VERSION ""

NS_ :

BS_:

BU_: TPMS EBS

BO_ 3221225472 VECTOR__INDEPENDENT_SIG_MSG: 0 Vector__XXX
 SG_ RqedPercentFanSpeed : 0|8@1+ (0.4,0) [0|100] "%" Vector__XXX
 SG_ IlluminationBrightnessPercent : 0|8@1+ (0.4,0) [0|100] "%" Vector__XXX
 SG_ CbA_CRfrgrntCmprssorOutletPress : 0|8@1+ (16,0) [0|4000] "kPa" Vector__XXX
 SG_ RelativeLevelRearAxleRight : 0|16@1+ (0.1,-2800) [-2800|3225.5] "mm" Vector__XXX
 SG_ RelativeLevelRearAxleLeft : 0|16@1+ (0.1,-2800) [-2800|3225.5] "mm" Vector__XXX
 SG_ RelativeLevelFrontAxleRight : 0|16@1+ (0.1,-2800) [-2800|3225.5] "mm" Vector__XXX
 SG_ RelativeLevelFrontAxleLeft : 0|16@1+ (0.1,-2800) [-2800|3225.5] "mm" Vector__XXX
 SG_ SspensionCtrlRefusalInformation : 0|4@1+ (1,0) [0|15] "" Vector__XXX
 SG_ SuspensionRemoteCtrl2 : 0|2@1+ (1,0) [0|3] "" Vector__XXX
 SG_ SuspensionRemoteCtrl1 : 0|2@1+ (1,0) [0|3] "" Vector__XXX
 SG_ RearAxleInBumperRange : 0|2@1+ (1,0) [0|3] "" Vector__XXX
 SG_ FrontAxleInBumperRange : 0|2@1+ (1,0) [0|3] "" Vector__XXX
 SG_ DoorRelease : 0|2@1+ (1,0) [0|3] "" Vector__XXX
 SG_ VehicleMotionInhibit : 0|2@1+ (1,0) [0|3] "" Vector__XXX
 SG_ SecurityDevice : 0|2@1+ (1,0) [0|3] "" Vector__XXX
 SG_ LevelCtrlMode : 0|4@1+ (1,0) [0|15] "" Vector__XXX
 SG_ KneelingInformation : 0|4@1+ (1,0) [0|15] "" Vector__XXX
 SG_ LiftingCtrlModeRearAxle : 0|2@1+ (1,0) [0|3] "" Vector__XXX
 SG_ LiftingCtrlModeFrontAxle : 0|2@1+ (1,0) [0|3] "" Vector__XXX
 SG_ LoweringCtrlModeRearAxle : 0|2@1+ (1,0) [0|3] "" Vector__XXX
 SG_ LoweringCtrlModeFrontAxle : 0|2@1+ (1,0) [0|3] "" Vector__XXX
 SG_ AboveNominalLevelRearAxle : 0|2@1+ (1,0) [0|3] "" Vector__XXX
 SG_ AboveNominalLevelFrontAxle : 0|2@1+ (1,0) [0|3] "" Vector__XXX
 SG_ BelowNominalLevelRearAxle : 0|2@1+ (1,0) [0|3] "" Vector__XXX
 SG_ BelowNominalLevelFrontAxle : 0|2@1+ (1,0) [0|3] "" Vector__XXX
 SG_ NominalLevelRearAxle : 0|4@1+ (1,0) [0|15] "" Vector__XXX
 SG_ NominalLevelFrontAxle : 0|4@1+ (1,0) [0|15] "" Vector__XXX
 SG_ LiftAxle2Pos : 0|2@1+ (1,0) [0|3] "" Vector__XXX
 SG_ LiftAxle1Pos : 0|2@1+ (1,0) [0|3] "" Vector__XXX
 SG_ UseTransferMode : 0|2@1+ (1,0) [0|3] "" Vector__XXX
 SG_ ParameterGroupNumber : 0|24@1+ (1,0) [0|16777215] "" Vector__XXX
 SG_ RoadSurfaceTemp : 0|16@1+ (0.03125,-273) [-273|1735] "deg" Vector__XXX
 SG_ EngAirInletTemp : 0|8@1+ (1,-40) [-40|210] "deg" Vector__XXX
 SG_ AmbientAirTemp : 0|16@1+ (0.03125,-273) [-273|1735] "deg" Vector__XXX
 SG_ CabInteriorTemp : 0|16@1+ (0.03125,-273) [-273|1735] "deg" Vector__XXX
 SG_ BarometricPress : 0|8@1+ (0.5,0) [0|125] "kPa" Vector__XXX
 SG_ TransOilLevelMeasurementStatus : 0|4@1+ (1,0) [0|15] "" Vector__XXX
 SG_ TransOilLevelCountdownTimer : 0|4@1+ (1,0) [0|15] "" Vector__XXX
 SG_ TransOilLevelHigh_Low : 0|8@1+ (0.5,-62.5) [-62.5|62.5] "L" Vector__XXX
 SG_ TransOilTemp : 0|16@1+ (0.03125,-273) [-273|1735] "deg" Vector__XXX
 SG_ TransOilPress : 0|8@1+ (16,0) [0|4000] "kPa" Vector__XXX
 SG_ TransFilterDiffPress : 0|8@1+ (2,0) [0|500] "kPa" Vector__XXX
 SG_ TransOilLevel : 0|8@1+ (0.4,0) [0|100] "%" Vector__XXX
 SG_ ClutchPress : 0|8@1+ (16,0) [0|4000] "kPa" Vector__XXX
 SG_ BatteryPotentialSwitched : 0|16@1+ (0.05,0) [0|3212.75] "V" Vector__XXX
 SG_ ElectricalPotential : 0|16@1+ (0.05,0) [0|3212.75] "V" Vector__XXX
 SG_ ChargingSystemPotential : 0|16@1+ (0.05,0) [0|3212.75] "V" Vector__XXX
 SG_ AltCurrent : 0|8@1+ (1,0) [0|250] "A" Vector__XXX
 SG_ NetBatteryCurrent : 0|8@1+ (1,-125) [-125|125] "A" Vector__XXX
 SG_ TotalNumberOfPacketsEoMA : 0|8@1+ (1,0) [0|255] "" Vector__XXX
 SG_ TotalMessageSizeEoMA : 0|16@1+ (1,0) [0|64255] "counts" Vector__XXX
 SG_ TotalMessageSizeBAM : 0|16@1+ (1,0) [0|64255] "counts" Vector__XXX
 SG_ TotalNumberOfPacketsBAM : 0|8@1+ (1,0) [0|255] "" Vector__XXX
 SG_ ConnectionAbortReason : 0|8@1+ (1,0) [0|255] "" Vector__XXX
 SG_ NextPacketNumberToBeSent : 0|8@1+ (1,0) [0|255] "" Vector__XXX
 SG_ NumberOfPacketsThatCanBeSent : 0|8@1+ (1,0) [0|255] "" Vector__XXX
 SG_ PGNumber : 0|24@1+ (1,0) [0|16777200] "" Vector__XXX
 SG_ MaximumNumberOfPackets : 0|8@1+ (1,0) [0|255] "" Vector__XXX
 SG_ TotalNumberOfPackets : 0|8@1+ (1,0) [0|255] "" Vector__XXX
 SG_ TotalMessageSize : 0|16@1+ (1,0) [0|64255] "counts" Vector__XXX
 SG_ ControlByte : 0|8@1+ (1,0) [0|255] "" Vector__XXX
 SG_ SequenceNumber : 0|8@1+ (1,0) [0|252] "" Vector__XXX
 SG_ DTC5 : 0|32@1+ (1,0) [0|4294967295] "" Vector__XXX
 SG_ DTC4 : 0|32@1+ (1,0) [0|4294967295] "" Vector__XXX
 SG_ DTC3 : 0|32@1+ (1,0) [0|4294967295] "" Vector__XXX
 SG_ DTC2 : 0|32@1+ (1,0) [0|4294967295] "" Vector__XXX
 SG_ DTC1 : 0|32@1+ (1,0) [0|4294967295] "" Vector__XXX
 SG_ DTC5 : 0|32@1+ (1,0) [0|4294967295] "" Vector__XXX
 SG_ DTC4 : 0|32@1+ (1,0) [0|4294967295] "" Vector__XXX
 SG_ DTC3 : 0|32@1+ (1,0) [0|4294967295] "" Vector__XXX
 SG_ DTC2 : 0|32@1+ (1,0) [0|4294967295] "" Vector__XXX
 SG_ CalibrationID4 : 0|32@1+ (1,0) [0|4294967295] "" Vector__XXX
 SG_ CalibrationID3 : 0|32@1+ (1,0) [0|4294967295] "" Vector__XXX
 SG_ CalibrationID2 : 0|32@1+ (1,0) [0|4294967295] "" Vector__XXX
 SG_ CalibrationID1 : 0|32@1+ (1,0) [0|4294967295] "" Vector__XXX
 SG_ CalibrationVerificationNumber : 0|32@1+ (1,0) [0|4294967295] "" Vector__XXX
 SG_ DTC5 : 0|32@1+ (1,0) [0|4294967295] "" Vector__XXX
 SG_ DTC4 : 0|32@1+ (1,0) [0|4294967295] "" Vector__XXX
 SG_ DTC3 : 0|32@1+ (1,0) [0|4294967295] "" Vector__XXX
 SG_ DTC2 : 0|32@1+ (1,0) [0|4294967295] "" Vector__XXX
 SG_ DTC1 : 0|32@1+ (1,0) [0|4294967295] "" Vector__XXX
 SG_ SPNSupported1High : 0|3@1+ (1,0) [0|7] "" Vector__XXX
 SG_ SPNSupportTypeSTR3 : 0|1@1+ (1,0) [0|1] "" Vector__XXX
 SG_ SPNSupportTypeSTR2 : 0|1@1+ (1,0) [0|1] "" Vector__XXX
 SG_ SPNSupportTypeEFF3 : 0|1@1+ (1,0) [0|1] "" Vector__XXX
 SG_ SPNSupportTypeEFF2 : 0|1@1+ (1,0) [0|1] "" Vector__XXX
 SG_ SPNSupportTypeDS3 : 0|1@1+ (1,0) [0|1] "" Vector__XXX
 SG_ SPNSupportTypeDS2 : 0|1@1+ (1,0) [0|1] "" Vector__XXX
 SG_ SPNSupported3High : 0|3@1+ (1,0) [0|7] "" Vector__XXX
 SG_ SPNSupported2High : 0|3@1+ (1,0) [0|7] "" Vector__XXX
 SG_ SPNSupported3 : 0|16@1+ (1,0) [0|65535] "" Vector__XXX
 SG_ SPNSupported2 : 0|16@1+ (1,0) [0|65535] "" Vector__XXX
 SG_ SPNDataLength3 : 0|8@1+ (1,0) [0|240] "" Vector__XXX
 SG_ SPNSupportTypeSTR1 : 0|1@1+ (1,0) [0|1] "" Vector__XXX
 SG_ SPNSupportTypeDS1 : 0|1@1+ (1,0) [0|1] "" Vector__XXX
 SG_ SPNSupportTypeEFF1 : 0|1@1+ (1,0) [0|1] "" Vector__XXX
 SG_ SPNDataLength2 : 0|8@1+ (1,0) [0|240] "" Vector__XXX
 SG_ SPNDataLength1 : 0|8@1+ (1,0) [0|240] "" Vector__XXX
 SG_ SPNSupported1 : 0|16@1+ (1,0) [0|65535] "" Vector__XXX
 SG_ DTC1 : 0|32@1+ (1,0) [0|4294967295] "" Vector__XXX
 SG_ ExpandedFreezeFrameLength : 0|8@1+ (1,0) [0|255] "Byte" Vector__XXX
 SG_ DTC1 : 0|32@1+ (1,0) [0|4294967295] "" Vector__XXX
 SG_ FreezeFrameLength : 0|8@1+ (1,0) [0|255] "Byte" Vector__XXX
 SG_ EngineCoolantTemperature : 0|8@1+ (1,-40) [-40|210] "°C" Vector__XXX
 SG_ MisfireMonitoringSupport : 0|1@1+ (1,0) [0|0] "" Vector__XXX
 SG_ OBDCompliance : 0|8@1+ (1,0) [0|240] "" Vector__XXX
 SG_ PreviouslyActiveTroubleCodes : 0|8@1+ (1,0) [0|240] "" Vector__XXX
 SG_ ActiveTroubleCodes : 0|8@1+ (1,0) [0|240] "" Vector__XXX
 SG_ SecondAirSystemMonStatus : 0|1@1+ (1,0) [0|1] "" Vector__XXX
 SG_ EvaporativeSystemMonStatus : 0|1@1+ (1,0) [0|1] "" Vector__XXX
 SG_ ACSystemRefrigerantMonStatus : 0|1@1+ (1,0) [0|1] "" Vector__XXX
 SG_ OxygenSensorHeaterMonStatus : 0|1@1+ (1,0) [0|1] "" Vector__XXX
 SG_ OxygenSensorMonStatus : 0|1@1+ (1,0) [0|1] "" Vector__XXX
 SG_ EGRSystemMonitoringStatus : 0|1@1+ (1,0) [0|1] "" Vector__XXX
 SG_ CatalystMonStatus : 0|1@1+ (1,0) [0|1] "" Vector__XXX
 SG_ ColdStartAidSystemMonStatus : 0|1@1+ (1,0) [0|1] "" Vector__XXX
 SG_ HeatedCatalystMonStatus : 0|1@1+ (1,0) [0|0] "" Vector__XXX
 SG_ CatalystMonSupp : 0|1@1+ (1,0) [0|1] "" Vector__XXX
 SG_ ColdStartAidSystemMonSupp : 0|1@1+ (1,0) [0|1] "" Vector__XXX
 SG_ HeatedCatalystMonSupp : 0|1@1+ (1,0) [0|0] "" Vector__XXX
 SG_ EvaporativeSystemMonSupp : 0|1@1+ (1,0) [0|1] "" Vector__XXX
 SG_ SecondAirSystemMonSupp : 0|1@1+ (1,0) [0|1] "" Vector__XXX
 SG_ ACSystemRefrigerantMonSupp : 0|1@1+ (1,0) [0|1] "" Vector__XXX
 SG_ OxygenSensorMonSupp : 0|1@1+ (1,0) [0|1] "" Vector__XXX
 SG_ OxygenSensorHeaterMonSupp : 0|1@1+ (1,0) [0|1] "" Vector__XXX
 SG_ EGRSystemMonitoringSupp : 0|1@1+ (1,0) [0|1] "" Vector__XXX
 SG_ MisfireMonitoringStatus : 0|1@1+ (1,0) [0|0] "" Vector__XXX
 SG_ ComprehensiveCompMonStatus : 0|1@1+ (1,0) [0|1] "" Vector__XXX
 SG_ FuelSystemMonitoringStatus : 0|1@1+ (1,0) [0|1] "" Vector__XXX
 SG_ ComprehensiveComponentMonSupp : 0|1@1+ (1,0) [0|0] "" Vector__XXX
 SG_ FuelSystemMonitoringSupport : 0|1@1+ (1,0) [0|1] "" Vector__XXX
 SG_ DTC5 : 0|32@1+ (1,0) [0|4294967295] "" Vector__XXX
 SG_ DTC4 : 0|32@1+ (1,0) [0|4294967295] "" Vector__XXX
 SG_ DTC3 : 0|32@1+ (1,0) [0|4294967295] "" Vector__XXX
 SG_ DTC2 : 0|32@1+ (1,0) [0|4294967295] "" Vector__XXX
 SG_ DTC1 : 0|32@1+ (1,0) [0|4294967295] "" Vector__XXX
 SG_ ShrtNameOfActualReportingDevice : 0|32@1+ (1,0) [0|0] "(2^32 - 1)" Vector__XXX
 SG_ LengthOfDataForTheReportedPGN : 0|8@1+ (1,0) [0|255] "" Vector__XXX
 SG_ PGNofRequstedInformation : 0|24@1+ (1,0) [0|16777215] "" Vector__XXX

BO_ 2566748171 AT2TI_EBS: 32 EBS
 SG_ Aftrtrtmnt2TrpNmbrOfActvRgnrtnMn : 224|32@1+ (1,0) [0|4294967295] "counts" Vector__XXX
 SG_ Aftrtrtmnt2TrpNmbrOfActvRgnrtnIn : 192|32@1+ (1,0) [0|4294967295] "counts" Vector__XXX
 SG_ Aftrtrtmnt2TrpNmbrOfPssvRgnrtns : 160|32@1+ (1,0) [0|4294967295] "counts" Vector__XXX
 SG_ Aftrtrtmnt2TrpPssvRgnrationTime : 128|32@1+ (1,0) [0|4211081215] "sec" Vector__XXX
 SG_ Aftrtrtmnt2TrpNmbrOfActvRgnrtns : 96|32@1+ (1,0) [0|4294967295] "counts" Vector__XXX
 SG_ Aftertreatment2TripDisabledTime : 64|32@1+ (1,0) [0|4211081215] "sec" Vector__XXX
 SG_ Aftrtrtmnt2TrpActvRgnrationTime : 32|32@1+ (1,0) [0|4211081215] "sec" Vector__XXX
 SG_ Aftertreatment2TripFuelUsed : 0|32@1+ (0.5,0) [0|2105540607.5] "L" Vector__XXX

BO_ 2566748414 AT2TI: 32 Vector__XXX
 SG_ Aftrtrtmnt2TrpNmbrOfActvRgnrtnMn : 224|32@1+ (1,0) [0|4294967295] "counts"  EBS
 SG_ Aftrtrtmnt2TrpNmbrOfActvRgnrtnIn : 192|32@1+ (1,0) [0|4294967295] "counts"  EBS
 SG_ Aftrtrtmnt2TrpNmbrOfPssvRgnrtns : 160|32@1+ (1,0) [0|4294967295] "counts"  EBS
 SG_ Aftrtrtmnt2TrpPssvRgnrationTime : 128|32@1+ (1,0) [0|4211081215] "sec"  EBS
 SG_ Aftrtrtmnt2TrpNmbrOfActvRgnrtns : 96|32@1+ (1,0) [0|4294967295] "counts"  EBS
 SG_ Aftertreatment2TripDisabledTime : 64|32@1+ (1,0) [0|4211081215] "sec"  EBS
 SG_ Aftrtrtmnt2TrpActvRgnrationTime : 32|32@1+ (1,0) [0|4211081215] "sec"  EBS
 SG_ Aftertreatment2TripFuelUsed : 0|32@1+ (0.5,0) [0|2105540607.5] "L"  EBS

BO_ 2550791691 CMD_PDU1_EBS: 15 EBS
 SG_ CMD_Signal : 0|8@1- (1,0) [0|0] "" Vector__XXX

BO_ 2550791934 CMD_PDU1: 15 Vector__XXX
 SG_ CMD_Signal : 0|8@1- (1,0) [0|0] ""  EBS

BO_ 2566838526 CA: 9 Vector__XXX
 SG_ AddressAssignment : 64|8@1+ (1,0) [0|255] ""  EBS
 SG_ ArbitraryAddressCapable : 63|1@1+ (1,0) [0|1] ""  EBS
 SG_ IndustryGroup M : 60|3@1+ (1,0) [0|7] ""  EBS
 SG_ VehicleSystemInstance : 56|4@1+ (1,0) [0|15] ""  EBS
 SG_ Function : 40|8@1+ (1,0) [0|255] ""  EBS
 SG_ VehicleSystem m0 : 49|7@1+ (1,0) [0|127] ""  EBS
 SG_ FunctionInstance : 35|5@1+ (1,0) [0|31] ""  EBS
 SG_ ECUInstance : 32|3@1+ (1,0) [0|7] ""  EBS
 SG_ ManufacturerCode : 21|11@1+ (1,0) [0|2047] ""  EBS
 SG_ IdentityNumber : 0|21@1+ (1,0) [0|2097152] ""  EBS
 SG_ VehicleSystem5 m5 : 49|7@1+ (1,0) [0|127] ""  EBS
 SG_ VehicleSystem4 m4 : 49|7@1+ (1,0) [0|127] ""  EBS
 SG_ VehicleSystem3 m3 : 49|7@1+ (1,0) [0|127] ""  EBS
 SG_ VehicleSystem2 m2 : 49|7@1+ (1,0) [0|127] ""  EBS
 SG_ VehicleSystem1 m1 : 49|7@1+ (1,0) [0|127] ""  EBS

BO_ 2042 CAN_STD: 1 Vector__XXX

BO_ 2565799424 ACL_EMS: 8 Vector__XXX
 SG_ VehicleSystem5 m5 : 49|7@1+ (1,0) [0|127] "" Vector__XXX
 SG_ VehicleSystem4 m4 : 49|7@1+ (1,0) [0|127] "" Vector__XXX
 SG_ VehicleSystem3 m3 : 49|7@1+ (1,0) [0|127] "" Vector__XXX
 SG_ VehicleSystem2 m2 : 49|7@1+ (1,0) [0|127] "" Vector__XXX
 SG_ VehicleSystem1 m1 : 49|7@1+ (1,0) [0|127] "" Vector__XXX
 SG_ ArbitraryAddressCapable : 63|1@1+ (1,0) [0|1] "" Vector__XXX
 SG_ IndustryGroup M : 60|3@1+ (1,0) [0|7] "" Vector__XXX
 SG_ VehicleSystemInstance : 56|4@1+ (1,0) [0|15] "" Vector__XXX
 SG_ VehicleSystem m0 : 49|7@1+ (1,0) [0|127] "" Vector__XXX
 SG_ Function : 40|8@1+ (1,0) [0|255] "" Vector__XXX
 SG_ FunctionInstance : 35|5@1+ (1,0) [0|31] "" Vector__XXX
 SG_ ECUInstance : 32|3@1+ (1,0) [0|7] "" Vector__XXX
 SG_ ManufacturerCode : 21|11@1+ (1,0) [0|2047] "" Vector__XXX
 SG_ IdentityNumber : 0|21@1+ (1,0) [0|2097152] "" Vector__XXX

BO_ 2565406208 ACKM_EMS: 8 Vector__XXX
 SG_ AddressBusy m3 : 32|8@1+ (1,0) [0|255] "" Vector__XXX
 SG_ ParameterGroupNumber : 40|24@1+ (1,0) [0|16777215] "" Vector__XXX
 SG_ GroupFunctionValue : 8|8@1+ (1,0) [0|255] "" Vector__XXX
 SG_ ControlByte M : 0|8@1+ (1,0) [0|255] "" Vector__XXX
 SG_ AddressAccessDenied m2 : 32|8@1+ (1,0) [0|255] "" Vector__XXX
 SG_ AddressNegativeAcknowledgement m1 : 32|8@1+ (1,0) [0|255] "" Vector__XXX
 SG_ AddressAcknowledged m0 : 32|8@1+ (1,0) [0|255] "" Vector__XXX

BO_ 2565406259 ACKM_TPMS: 8 TPMS
 SG_ AddressBusy m3 : 32|8@1+ (1,0) [0|255] "" Vector__XXX
 SG_ ParameterGroupNumber : 40|24@1+ (1,0) [0|16777215] "" Vector__XXX
 SG_ GroupFunctionValue : 8|8@1+ (1,0) [0|255] "" Vector__XXX
 SG_ ControlByte M : 0|8@1+ (1,0) [0|255] "" Vector__XXX
 SG_ AddressAccessDenied m2 : 32|8@1+ (1,0) [0|255] "" Vector__XXX
 SG_ AddressNegativeAcknowledgement m1 : 32|8@1+ (1,0) [0|255] "" Vector__XXX
 SG_ AddressAcknowledged m0 : 32|8@1+ (1,0) [0|255] "" Vector__XXX

BO_ 2565799475 ACL_TPMS: 8 TPMS
 SG_ VehicleSystem5 m5 : 49|7@1+ (1,0) [0|127] "" Vector__XXX
 SG_ VehicleSystem4 m4 : 49|7@1+ (1,0) [0|127] "" Vector__XXX
 SG_ VehicleSystem3 m3 : 49|7@1+ (1,0) [0|127] "" Vector__XXX
 SG_ VehicleSystem2 m2 : 49|7@1+ (1,0) [0|127] "" Vector__XXX
 SG_ VehicleSystem1 m1 : 49|7@1+ (1,0) [0|127] "" Vector__XXX
 SG_ ArbitraryAddressCapable : 63|1@1+ (1,0) [0|1] "" Vector__XXX
 SG_ IndustryGroup M : 60|3@1+ (1,0) [0|7] "" Vector__XXX
 SG_ VehicleSystemInstance : 56|4@1+ (1,0) [0|15] "" Vector__XXX
 SG_ VehicleSystem m0 : 49|7@1+ (1,0) [0|127] "" Vector__XXX
 SG_ Function : 40|8@1+ (1,0) [0|255] "" Vector__XXX
 SG_ FunctionInstance : 35|5@1+ (1,0) [0|31] "" Vector__XXX
 SG_ ECUInstance : 32|3@1+ (1,0) [0|7] "" Vector__XXX
 SG_ ManufacturerCode : 21|11@1+ (1,0) [0|2047] "" Vector__XXX
 SG_ IdentityNumber : 0|21@1+ (1,0) [0|2097152] "" Vector__XXX

BO_ 2565485323 RQST_EBS: 3 EBS
 SG_ ParameterGroupNumber : 0|24@1+ (1,0) [0|16777215] ""  TPMS

BO_ 2566850611 PROPR_08_TPMS: 8 TPMS
 SG_ PROPR_08_Signal : 0|64@1- (1,0) [0|0] ""  EBS

BO_ 2566850814 PROPR_08: 8 Vector__XXX
 SG_ PROPR_08_Signal : 0|64@1- (1,0) [0|0] "" Vector__XXX

BO_ 2566850355 PROPR_07_TPMS: 8 TPMS
 SG_ PROPR_07_Signal : 0|64@1- (1,0) [0|0] ""  EBS

BO_ 2566849547 PROPR_04_EBS: 8 EBS
 SG_ PROPR_04_Signal : 0|64@1- (1,0) [0|0] "" Vector__XXX

BO_ 2566849035 PROPR_02_EBS: 8 EBS
 SG_ PROPR_02_Signal : 0|64@1- (1,0) [0|0] "" Vector__XXX

BO_ 2566849291 PROPR_03_EBS: 8 EBS
 SG_ PROPR_03_Signal : 0|64@1- (1,0) [0|0] "" Vector__XXX

BO_ 2566850558 PROPR_07: 8 Vector__XXX
 SG_ PROPR_07_Signal : 0|64@1- (1,0) [0|0] "" Vector__XXX

BO_ 2566849790 PROPR_04: 8 Vector__XXX
 SG_ PROPR_04_Signal : 0|64@1- (1,0) [0|0] "" Vector__XXX

BO_ 2566849534 PROPR_03: 8 Vector__XXX
 SG_ PROPR_03_Signal : 0|64@1- (1,0) [0|0] "" Vector__XXX

BO_ 2566849278 PROPR_02: 8 Vector__XXX
 SG_ PROPR_02_Signal : 0|64@1- (1,0) [0|0] "" Vector__XXX

BO_ 2566834699 DM1_EBS: 22 EBS
 SG_ DTC5 : 144|32@1+ (1,0) [0|4294967295] "" Vector__XXX
 SG_ DTC4 : 112|32@1+ (1,0) [0|4294967295] "" Vector__XXX
 SG_ DTC3 : 80|32@1+ (1,0) [0|4294967295] "" Vector__XXX
 SG_ DTC2 : 48|32@1+ (1,0) [0|4294967295] "" Vector__XXX
 SG_ DTC1 : 16|32@1+ (1,0) [0|4294967295] "" Vector__XXX
 SG_ FlashRedStopLamp : 12|2@1+ (1,0) [0|3] "" Vector__XXX
 SG_ FlashProtectLamp : 8|2@1+ (1,0) [0|3] "" Vector__XXX
 SG_ FlashMalfuncIndicatorLamp : 14|2@1+ (1,0) [0|3] "" Vector__XXX
 SG_ FlashAmberWarningLamp : 10|2@1+ (1,0) [0|3] "" Vector__XXX
 SG_ MalfunctionIndicatorLampStatus : 6|2@1+ (1,0) [0|3] "" Vector__XXX
 SG_ AmberWarningLampStatus : 2|2@1+ (1,0) [0|3] "" Vector__XXX
 SG_ RedStopLampState : 4|2@1+ (1,0) [0|3] "" Vector__XXX
 SG_ ProtectLampStatus : 0|2@1+ (1,0) [0|3] "" Vector__XXX

BO_ 2566834955 DM2_EBS: 22 Vector__XXX
 SG_ DTC5 : 144|32@1+ (1,0) [0|4294967295] "" Vector__XXX
 SG_ DTC4 : 112|32@1+ (1,0) [0|4294967295] "" Vector__XXX
 SG_ DTC3 : 80|32@1+ (1,0) [0|4294967295] "" Vector__XXX
 SG_ DTC2 : 48|32@1+ (1,0) [0|4294967295] "" Vector__XXX
 SG_ DTC1 : 16|32@1+ (1,0) [0|4294967295] "" Vector__XXX
 SG_ MalfunctionIndicatorLampStatus : 6|2@1+ (1,0) [0|3] "" Vector__XXX
 SG_ RedStopLampState : 4|2@1+ (1,0) [0|3] "" Vector__XXX
 SG_ AmberWarningLampStatus : 2|2@1+ (1,0) [0|3] "" Vector__XXX
 SG_ ProtectLampStatus : 0|2@1+ (1,0) [0|3] "" Vector__XXX
 SG_ FlashRedStopLamp : 12|2@1+ (1,0) [0|3] "" Vector__XXX
 SG_ FlashProtectLamp : 8|2@1+ (1,0) [0|3] "" Vector__XXX
 SG_ FlashMalfuncIndicatorLamp : 14|2@1+ (1,0) [0|3] "" Vector__XXX
 SG_ FlashAmberWarningLamp : 10|2@1+ (1,0) [0|3] "" Vector__XXX

BO_ 2566764043 DM24_EBS: 12 Vector__XXX
 SG_ SPNSupported1High : 21|3@1+ (1,0) [0|7] "" Vector__XXX
 SG_ SPNSupportTypeSTR3 : 82|1@1+ (1,0) [0|1] "" Vector__XXX
 SG_ SPNSupportTypeSTR2 : 81|1@1+ (1,0) [0|1] "" Vector__XXX
 SG_ SPNSupportTypeEFF3 : 80|1@1+ (1,0) [0|1] "" Vector__XXX
 SG_ SPNSupportTypeEFF2 : 48|1@1+ (1,0) [0|1] "" Vector__XXX
 SG_ SPNSupportTypeDS3 : 50|1@1+ (1,0) [0|1] "" Vector__XXX
 SG_ SPNSupportTypeDS2 : 49|1@1+ (1,0) [0|1] "" Vector__XXX
 SG_ SPNSupported3High : 85|3@1+ (1,0) [0|7] "" Vector__XXX
 SG_ SPNSupported2High : 53|3@1+ (1,0) [0|7] "" Vector__XXX
 SG_ SPNSupported3 : 64|16@1+ (1,0) [0|65535] "" Vector__XXX
 SG_ SPNSupported2 : 32|16@1+ (1,0) [0|65535] "" Vector__XXX
 SG_ SPNDataLength3 : 88|8@1+ (1,0) [0|240] "" Vector__XXX
 SG_ SPNSupportTypeSTR1 : 18|1@1+ (1,0) [0|1] "" Vector__XXX
 SG_ SPNSupportTypeDS1 : 17|1@1+ (1,0) [0|1] "" Vector__XXX
 SG_ SPNSupportTypeEFF1 : 16|1@1+ (1,0) [0|1] "" Vector__XXX
 SG_ SPNDataLength2 : 56|8@1+ (1,0) [0|240] "" Vector__XXX
 SG_ SPNDataLength1 : 24|8@1+ (1,0) [0|240] "" Vector__XXX
 SG_ SPNSupported1 : 0|16@1+ (1,0) [0|65535] "" Vector__XXX

BO_ 2566764299 DM25_EBS: 13 Vector__XXX
 SG_ DTC1 : 8|32@1+ (1,0) [0|4294967295] "" Vector__XXX
 SG_ ExpandedFreezeFrameLength : 0|8@1+ (1,0) [0|255] "Byte" Vector__XXX

BO_ 2566835467 DM4_EBS: 13 Vector__XXX
 SG_ DTC1 : 8|32@1+ (1,0) [0|4294967295] "" Vector__XXX
 SG_ FreezeFrameLength : 0|8@1+ (1,0) [0|255] "Byte" Vector__XXX
 SG_ EngSpeed : 56|16@1+ (0.125,0) [0|8031.875] "RPM" Vector__XXX
 SG_ EngTorqueMode : 40|4@1+ (1,0) [0|15] "" Vector__XXX
 SG_ EngTurboBoostPress : 48|8@1+ (2,0) [0|500] "kPa" Vector__XXX
 SG_ WheelBasedVehicleSpeed : 88|16@1+ (0.00390625,0) [0|250.996] "km/h" Vector__XXX
 SG_ EngPercentLoadAtCurrentSpeed : 72|8@1+ (1,0) [0|250] "%" Vector__XXX
 SG_ EngineCoolantTemperature : 80|8@1+ (1,-40) [-40|210] "°C" Vector__XXX

BO_ 2566848779 PROPR_01_EBS: 8 EBS
 SG_ PROPR_01_Signal : 0|64@1- (1,0) [0|0] "" Vector__XXX

BO_ 2566849022 PROPR_01: 8 Vector__XXX
 SG_ PROPR_01_Signal : 0|64@1- (1,0) [0|0] "" Vector__XXX

BO_ 2565799435 ACL_EBS: 8 EBS
 SG_ VehicleSystem5 m5 : 49|7@1+ (1,0) [0|127] "" Vector__XXX
 SG_ VehicleSystem4 m4 : 49|7@1+ (1,0) [0|127] "" Vector__XXX
 SG_ VehicleSystem3 m3 : 49|7@1+ (1,0) [0|127] "" Vector__XXX
 SG_ VehicleSystem2 m2 : 49|7@1+ (1,0) [0|127] "" Vector__XXX
 SG_ VehicleSystem1 m1 : 49|7@1+ (1,0) [0|127] "" Vector__XXX
 SG_ ArbitraryAddressCapable : 63|1@1+ (1,0) [0|1] "" Vector__XXX
 SG_ IndustryGroup M : 60|3@1+ (1,0) [0|7] "" Vector__XXX
 SG_ VehicleSystemInstance : 56|4@1+ (1,0) [0|15] "" Vector__XXX
 SG_ VehicleSystem m0 : 49|7@1+ (1,0) [0|127] "" Vector__XXX
 SG_ Function : 40|8@1+ (1,0) [0|255] "" Vector__XXX
 SG_ FunctionInstance : 35|5@1+ (1,0) [0|31] "" Vector__XXX
 SG_ ECUInstance : 32|3@1+ (1,0) [0|7] "" Vector__XXX
 SG_ ManufacturerCode : 21|11@1+ (1,0) [0|2047] "" Vector__XXX
 SG_ IdentityNumber : 0|21@1+ (1,0) [0|2097152] "" Vector__XXX

BO_ 2565602827 TPDT_EBS: 8 EBS
 SG_ SequenceNumber : 0|8@1+ (1,0) [0|252] "" Vector__XXX

BO_ 2565668363 TPCM_EBS: 8 EBS
 SG_ TotalNumberOfPacketsEoMA m19 : 24|8@1+ (1,0) [0|255] "" Vector__XXX
 SG_ TotalMessageSizeEoMA m19 : 8|16@1+ (1,0) [0|64255] "counts" Vector__XXX
 SG_ TotalMessageSizeBAM m32 : 8|16@1+ (1,0) [0|64255] "counts" Vector__XXX
 SG_ TotalNumberOfPacketsBAM m32 : 24|8@1+ (1,0) [0|255] "" Vector__XXX
 SG_ ConnectionAbortReason m255 : 8|8@1+ (1,0) [0|255] "" Vector__XXX
 SG_ NextPacketNumberToBeSent m17 : 16|8@1+ (1,0) [0|255] "" Vector__XXX
 SG_ NumberOfPacketsThatCanBeSent m17 : 8|8@1+ (1,0) [0|255] "" Vector__XXX
 SG_ PGNumber : 40|24@1+ (1,0) [0|16777200] "" Vector__XXX
 SG_ MaximumNumberOfPackets m16 : 32|8@1+ (1,0) [0|255] "" Vector__XXX
 SG_ TotalNumberOfPackets m16 : 24|8@1+ (1,0) [0|255] "" Vector__XXX
 SG_ TotalMessageSize m16 : 8|16@1+ (1,0) [0|64255] "counts" Vector__XXX
 SG_ ControlByte M : 0|8@1+ (1,0) [0|255] "" Vector__XXX

BO_ 2565406219 ACKM_EBS: 8 EBS
 SG_ AddressBusy m3 : 32|8@1+ (1,0) [0|255] "" Vector__XXX
 SG_ ParameterGroupNumber : 40|24@1+ (1,0) [0|16777215] "" Vector__XXX
 SG_ GroupFunctionValue : 8|8@1+ (1,0) [0|255] "" Vector__XXX
 SG_ ControlByte M : 0|8@1+ (1,0) [0|255] "" Vector__XXX
 SG_ AddressAccessDenied m2 : 32|8@1+ (1,0) [0|255] "" Vector__XXX
 SG_ AddressNegativeAcknowledgement m1 : 32|8@1+ (1,0) [0|255] "" Vector__XXX
 SG_ AddressAcknowledged m0 : 32|8@1+ (1,0) [0|255] "" Vector__XXX

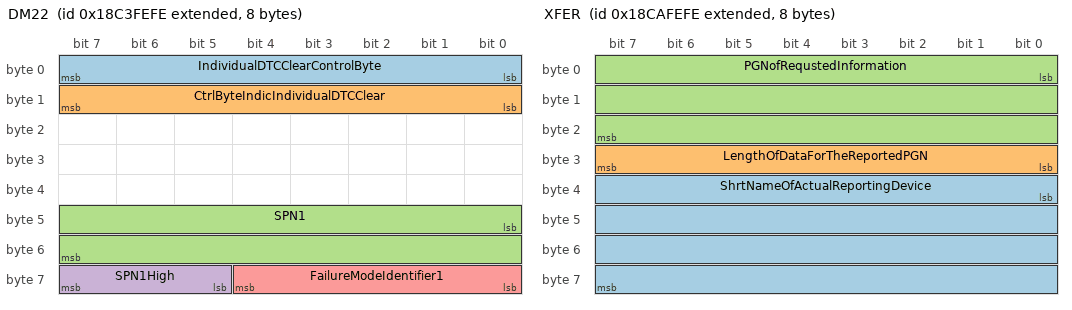
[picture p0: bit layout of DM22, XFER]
BO_ 2562981630 DM22: 8 Vector__XXX
 SG_ IndividualDTCClearControlByte : 0|8@1+ (1,0) [0|255] "" Vector__XXX
 SG_ CtrlByteIndicIndividualDTCClear : 8|8@1+ (1,0) [0|255] "" Vector__XXX
 SG_ SPN1 : 40|16@1+ (1,0) [0|65536] "" Vector__XXX
 SG_ SPN1High : 61|3@1+ (1,0) [0|7] "" Vector__XXX
 SG_ FailureModeIdentifier1 : 56|5@1+ (1,0) [0|0] "" Vector__XXX

BO_ 2566836222 DM6: 22 Vector__XXX
 SG_ DTC5 : 144|32@1+ (1,0) [0|4294967295] "" Vector__XXX
 SG_ DTC4 : 112|32@1+ (1,0) [0|4294967295] "" Vector__XXX
 SG_ DTC3 : 80|32@1+ (1,0) [0|4294967295] "" Vector__XXX
 SG_ DTC2 : 48|32@1+ (1,0) [0|4294967295] "" Vector__XXX
 SG_ DTC1 : 16|32@1+ (1,0) [0|4294967295] "" Vector__XXX
 SG_ FlashRedStopLamp : 12|2@1+ (1,0) [0|3] "" Vector__XXX
 SG_ FlashProtectLamp : 8|2@1+ (1,0) [0|3] "" Vector__XXX
 SG_ FlashMalfuncIndicatorLamp : 14|2@1+ (1,0) [0|3] "" Vector__XXX
 SG_ MalfunctionIndicatorLampStatus : 6|2@1+ (1,0) [0|3] "" Vector__XXX
 SG_ RedStopLampState : 4|2@1+ (1,0) [0|3] "" Vector__XXX
 SG_ AmberWarningLampStatus : 2|2@1+ (1,0) [0|3] "" Vector__XXX
 SG_ ProtectLampStatus : 0|2@1+ (1,0) [0|3] "" Vector__XXX

BO_ 2566835966 DM5: 8 Vector__XXX
 SG_ MisfireMonitoringSupport : 24|1@1+ (1,0) [0|0] "" Vector__XXX
 SG_ OBDCompliance : 16|8@1+ (1,0) [0|240] "" Vector__XXX
 SG_ PreviouslyActiveTroubleCodes : 8|8@1+ (1,0) [0|240] "" Vector__XXX
 SG_ ActiveTroubleCodes : 0|8@1+ (1,0) [0|240] "" Vector__XXX
 SG_ SecondAirSystemMonStatus : 51|1@1+ (1,0) [0|1] "" Vector__XXX
 SG_ EvaporativeSystemMonStatus : 50|1@1+ (1,0) [0|1] "" Vector__XXX
 SG_ ACSystemRefrigerantMonStatus : 52|1@1+ (1,0) [0|1] "" Vector__XXX
 SG_ OxygenSensorHeaterMonStatus : 54|1@1+ (1,0) [0|1] "" Vector__XXX
 SG_ OxygenSensorMonStatus : 53|1@1+ (1,0) [0|1] "" Vector__XXX
 SG_ EGRSystemMonitoringStatus : 55|1@1+ (1,0) [0|1] "" Vector__XXX
 SG_ CatalystMonStatus : 48|1@1+ (1,0) [0|1] "" Vector__XXX
 SG_ ColdStartAidSystemMonStatus : 56|1@1+ (1,0) [0|1] "" Vector__XXX
 SG_ HeatedCatalystMonStatus : 49|1@1+ (1,0) [0|0] "" Vector__XXX
 SG_ CatalystMonSupp : 32|1@1+ (1,0) [0|1] "" Vector__XXX
 SG_ ColdStartAidSystemMonSupp : 40|1@1+ (1,0) [0|1] "" Vector__XXX
 SG_ HeatedCatalystMonSupp : 33|1@1+ (1,0) [0|0] "" Vector__XXX
 SG_ EvaporativeSystemMonSupp : 34|1@1+ (1,0) [0|1] "" Vector__XXX
 SG_ SecondAirSystemMonSupp : 35|1@1+ (1,0) [0|1] "" Vector__XXX
 SG_ ACSystemRefrigerantMonSupp : 36|1@1+ (1,0) [0|1] "" Vector__XXX
 SG_ OxygenSensorMonSupp : 37|1@1+ (1,0) [0|1] "" Vector__XXX
 SG_ OxygenSensorHeaterMonSupp : 38|1@1+ (1,0) [0|1] "" Vector__XXX
 SG_ EGRSystemMonitoringSupp : 39|1@1+ (1,0) [0|1] "" Vector__XXX
 SG_ MisfireMonitoringStatus : 28|1@1+ (1,0) [0|0] "" Vector__XXX
 SG_ ComprehensiveCompMonStatus : 30|1@1+ (1,0) [0|1] "" Vector__XXX
 SG_ FuelSystemMonitoringStatus : 29|1@1+ (1,0) [0|1] "" Vector__XXX
 SG_ ComprehensiveComponentMonSupp : 26|1@1+ (1,0) [0|0] "" Vector__XXX
 SG_ FuelSystemMonitoringSupport : 25|1@1+ (1,0) [0|1] "" Vector__XXX

BO_ 2566835710 DM4: 13 Vector__XXX
 SG_ DTC1 : 8|32@1+ (1,0) [0|4294967295] "" Vector__XXX
 SG_ FreezeFrameLength : 0|8@1+ (1,0) [0|255] "Byte" Vector__XXX
 SG_ EngSpeed : 56|16@1+ (0.125,0) [0|8031.875] "RPM" Vector__XXX
 SG_ EngTorqueMode : 40|4@1+ (1,0) [0|15] "" Vector__XXX
 SG_ EngTurboBoostPress : 48|8@1+ (2,0) [0|500] "kPa" Vector__XXX
 SG_ WheelBasedVehicleSpeed : 88|16@1+ (0.00390625,0) [0|250.996] "km/h" Vector__XXX
 SG_ EngPercentLoadAtCurrentSpeed : 72|8@1+ (1,0) [0|250] "%" Vector__XXX
 SG_ EngineCoolantTemperature : 80|8@1+ (1,-40) [-40|210] "°C" Vector__XXX

BO_ 2566835454 DM3: 0 Vector__XXX

BO_ 2566764542 DM25: 13 Vector__XXX
 SG_ DTC1 : 8|32@1+ (1,0) [0|4294967295] "" Vector__XXX
 SG_ ExpandedFreezeFrameLength : 0|8@1+ (1,0) [0|255] "Byte" Vector__XXX

BO_ 2566764286 DM24: 12 Vector__XXX
 SG_ SPNSupported1High : 21|3@1+ (1,0) [0|7] "" Vector__XXX
 SG_ SPNSupportTypeSTR3 : 82|1@1+ (1,0) [0|1] "" Vector__XXX
 SG_ SPNSupportTypeSTR2 : 50|1@1+ (1,0) [0|1] "" Vector__XXX
 SG_ SPNSupportTypeEFF3 : 80|1@1+ (1,0) [0|1] "" Vector__XXX
 SG_ SPNSupportTypeEFF2 : 48|1@1+ (1,0) [0|1] "" Vector__XXX
 SG_ SPNSupportTypeDS3 : 81|1@1+ (1,0) [0|1] "" Vector__XXX
 SG_ SPNSupportTypeDS2 : 49|1@1+ (1,0) [0|1] "" Vector__XXX
 SG_ SPNSupported3High : 85|3@1+ (1,0) [0|7] "" Vector__XXX
 SG_ SPNSupported2High : 53|3@1+ (1,0) [0|7] "" Vector__XXX
 SG_ SPNSupported3 : 64|16@1+ (1,0) [0|65535] "" Vector__XXX
 SG_ SPNSupported2 : 32|16@1+ (1,0) [0|65535] "" Vector__XXX
 SG_ SPNDataLength3 : 88|8@1+ (1,0) [0|240] "" Vector__XXX
 SG_ SPNSupportTypeSTR1 : 18|1@1+ (1,0) [0|1] "" Vector__XXX
 SG_ SPNSupportTypeDS1 : 17|1@1+ (1,0) [0|1] "" Vector__XXX
 SG_ SPNSupportTypeEFF1 : 16|1@1+ (1,0) [0|1] "" Vector__XXX
 SG_ SPNDataLength2 : 56|8@1+ (1,0) [0|240] "" Vector__XXX
 SG_ SPNDataLength1 : 24|8@1+ (1,0) [0|240] "" Vector__XXX
 SG_ SPNSupported1 : 0|16@1+ (1,0) [0|65535] "" Vector__XXX

BO_ 2566835198 DM2: 22 Vector__XXX
 SG_ DTC5 : 144|32@1+ (1,0) [0|4294967295] "" Vector__XXX
 SG_ DTC4 : 112|32@1+ (1,0) [0|4294967295] "" Vector__XXX
 SG_ DTC3 : 80|32@1+ (1,0) [0|4294967295] "" Vector__XXX
 SG_ DTC2 : 48|32@1+ (1,0) [0|4294967295] "" Vector__XXX
 SG_ DTC1 : 16|32@1+ (1,0) [0|4294967295] "" Vector__XXX
 SG_ MalfunctionIndicatorLampStatus : 6|2@1+ (1,0) [0|3] "" Vector__XXX
 SG_ RedStopLampState : 4|2@1+ (1,0) [0|3] "" Vector__XXX
 SG_ AmberWarningLampStatus : 2|2@1+ (1,0) [0|3] "" Vector__XXX
 SG_ ProtectLampStatus : 0|2@1+ (1,0) [0|3] "" Vector__XXX
 SG_ FlashRedStopLamp : 12|2@1+ (1,0) [0|3] "" Vector__XXX
 SG_ FlashProtectLamp : 8|2@1+ (1,0) [0|3] "" Vector__XXX
 SG_ FlashMalfuncIndicatorLamp : 14|2@1+ (1,0) [0|3] "" Vector__XXX
 SG_ FlashAmberWarningLamp : 10|2@1+ (1,0) [0|3] "" Vector__XXX

BO_ 2564030206 DM19: 20 Vector__XXX
 SG_ CalibrationID4 : 128|32@1+ (1,0) [0|4294967295] "" Vector__XXX
 SG_ CalibrationID3 : 96|32@1+ (1,0) [0|4294967295] "" Vector__XXX
 SG_ CalibrationID2 : 64|32@1+ (1,0) [0|4294967295] "" Vector__XXX
 SG_ CalibrationID1 : 32|32@1+ (1,0) [0|4294967295] "" Vector__XXX
 SG_ CalibrationVerificationNumber : 0|32@1+ (1,0) [0|4294967295] "" Vector__XXX

BO_ 2566837502 DM12: 22 Vector__XXX
 SG_ DTC5 : 144|32@1+ (1,0) [0|4294967295] "" Vector__XXX
 SG_ DTC4 : 112|32@1+ (1,0) [0|4294967295] "" Vector__XXX
 SG_ DTC3 : 80|32@1+ (1,0) [0|4294967295] "" Vector__XXX
 SG_ DTC2 : 48|32@1+ (1,0) [0|4294967295] "" Vector__XXX
 SG_ FlashRedStopLamp : 12|2@1+ (1,0) [0|3] "" Vector__XXX
 SG_ FlashProtectLamp : 8|2@1+ (1,0) [0|3] "" Vector__XXX
 SG_ MalfunctionIndicatorLampStatus : 6|2@1+ (1,0) [0|3] "" Vector__XXX
 SG_ RedStopLampState : 4|2@1+ (1,0) [0|3] "" Vector__XXX
 SG_ AmberWarningLampStatus : 2|2@1+ (1,0) [0|3] "" Vector__XXX
 SG_ ProtectLampStatus : 0|2@1+ (1,0) [0|3] "" Vector__XXX
 SG_ FlashMalfuncIndicatorLamp : 14|2@1+ (1,0) [0|3] "" Vector__XXX
 SG_ FlashAmberWarningLamp : 10|2@1+ (1,0) [0|3] "" Vector__XXX
 SG_ SPN1 : 16|16@1+ (1,0) [0|65536] "" Vector__XXX

BO_ 2566834942 DM1: 22 Vector__XXX
 SG_ DTC5 : 144|32@1+ (1,0) [0|4294967295] "" Vector__XXX
 SG_ DTC4 : 112|32@1+ (1,0) [0|4294967295] "" Vector__XXX
 SG_ DTC3 : 80|32@1+ (1,0) [0|4294967295] "" Vector__XXX
 SG_ DTC2 : 48|32@1+ (1,0) [0|4294967295] "" Vector__XXX
 SG_ DTC1 : 16|32@1+ (1,0) [0|4294967295] "" Vector__XXX
 SG_ FlashRedStopLamp : 12|2@1+ (1,0) [0|3] "" Vector__XXX
 SG_ FlashProtectLamp : 8|2@1+ (1,0) [0|3] "" Vector__XXX
 SG_ FlashMalfuncIndicatorLamp : 14|2@1+ (1,0) [0|3] "" Vector__XXX
 SG_ FlashAmberWarningLamp : 10|2@1+ (1,0) [0|3] "" Vector__XXX
 SG_ MalfunctionIndicatorLampStatus : 6|2@1+ (1,0) [0|3] "" Vector__XXX
 SG_ AmberWarningLampStatus : 2|2@1+ (1,0) [0|3] "" Vector__XXX
 SG_ RedStopLampState : 4|2@1+ (1,0) [0|3] "" Vector__XXX
 SG_ ProtectLampStatus : 0|2@1+ (1,0) [0|3] "" Vector__XXX

BO_ 2565799678 ACL: 8 Vector__XXX
 SG_ VehicleSystem5 m5 : 49|7@1+ (1,0) [0|127] "" Vector__XXX
 SG_ VehicleSystem4 m4 : 49|7@1+ (1,0) [0|127] "" Vector__XXX
 SG_ VehicleSystem3 m3 : 49|7@1+ (1,0) [0|127] "" Vector__XXX
 SG_ VehicleSystem2 m2 : 49|7@1+ (1,0) [0|127] "" Vector__XXX
 SG_ VehicleSystem1 m1 : 49|7@1+ (1,0) [0|127] "" Vector__XXX
 SG_ ArbitraryAddressCapable : 63|1@1+ (1,0) [0|1] "" Vector__XXX
 SG_ IndustryGroup M : 60|3@1+ (1,0) [0|7] "" Vector__XXX
 SG_ VehicleSystemInstance : 56|4@1+ (1,0) [0|15] "" Vector__XXX
 SG_ VehicleSystem m0 : 49|7@1+ (1,0) [0|127] "" Vector__XXX
 SG_ Function : 40|8@1+ (1,0) [0|255] "" Vector__XXX
 SG_ FunctionInstance : 35|5@1+ (1,0) [0|31] "" Vector__XXX
 SG_ ECUInstance : 32|3@1+ (1,0) [0|7] "" Vector__XXX
 SG_ ManufacturerCode : 21|11@1+ (1,0) [0|2047] "" Vector__XXX
 SG_ IdentityNumber : 0|21@1+ (1,0) [0|2097152] "" Vector__XXX

BO_ 2563440382 XFER: 8 Vector__XXX
 SG_ ShrtNameOfActualReportingDevice : 32|32@1+ (1,0) [0|0] "(2^32 - 1)" Vector__XXX
 SG_ LengthOfDataForTheReportedPGN : 24|8@1+ (1,0) [0|255] "" Vector__XXX
 SG_ PGNofRequstedInformation : 0|24@1+ (1,0) [0|16777215] "" Vector__XXX

BO_ 2565603070 TPDT: 8 Vector__XXX
 SG_ SequenceNumber : 0|8@1+ (1,0) [0|252] ""  EBS

BO_ 2565668606 TPCM: 8 Vector__XXX
 SG_ TotalNumberOfPacketsEoMA m19 : 24|8@1+ (1,0) [0|255] ""  EBS
 SG_ TotalMessageSizeEoMA m19 : 8|16@1+ (1,0) [0|64255] "counts"  EBS
 SG_ TotalMessageSizeBAM m32 : 8|16@1+ (1,0) [0|64255] "counts"  EBS
 SG_ TotalNumberOfPacketsBAM m32 : 24|8@1+ (1,0) [0|255] ""  EBS
 SG_ ConnectionAbortReason m255 : 8|8@1+ (1,0) [0|255] ""  EBS
 SG_ NextPacketNumberToBeSent m17 : 16|8@1+ (1,0) [0|255] ""  EBS
 SG_ NumberOfPacketsThatCanBeSent m17 : 8|8@1+ (1,0) [0|255] ""  EBS
 SG_ PGNumber : 40|24@1+ (1,0) [0|16777200] ""  EBS
 SG_ MaximumNumberOfPackets m16 : 32|8@1+ (1,0) [0|255] ""  EBS
 SG_ TotalNumberOfPackets m16 : 24|8@1+ (1,0) [0|255] ""  EBS
 SG_ TotalMessageSize m16 : 8|16@1+ (1,0) [0|64255] "counts"  EBS
 SG_ ControlByte M : 0|8@1+ (1,0) [0|255] ""  EBS

BO_ 2565537534 RQST: 3 Vector__XXX
 SG_ ParameterGroupNumber : 0|24@1+ (1,0) [0|16777215] ""  EBS

BO_ 2565406462 ACKM: 8 Vector__XXX
 SG_ AddressBusy m3 : 32|8@1+ (1,0) [0|255] "" Vector__XXX
 SG_ ParameterGroupNumber : 40|24@1+ (1,0) [0|16777215] "" Vector__XXX
 SG_ GroupFunctionValue : 8|8@1+ (1,0) [0|255] "" Vector__XXX
 SG_ ControlByte M : 0|8@1+ (1,0) [0|255] "" Vector__XXX
 SG_ AddressAccessDenied m2 : 32|8@1+ (1,0) [0|255] "" Vector__XXX
 SG_ AddressNegativeAcknowledgement m1 : 32|8@1+ (1,0) [0|255] "" Vector__XXX
 SG_ AddressAcknowledged m0 : 32|8@1+ (1,0) [0|255] "" Vector__XXX

EV_ EnvEnable_Bug_Table03_Row01: 0 [0|1] "" 0 1 DUMMY_NODE_VECTOR0 Vector__XXX;

EV_ EnvEBS_CannotClaimACL: 0 [0|1] "" 0 2 DUMMY_NODE_VECTOR3  EBS;

EV_ EnvEBS_Powercycle: 0 [0|1] "" 0 3 DUMMY_NODE_VECTOR3 Vector__XXX;

EV_ EnvEBS_Powercycle_1s: 0 [0|1] "" 0 4 DUMMY_NODE_VECTOR3 Vector__XXX;

EV_ EnvEBS_RequestACL: 0 [0|1] "" 0 5 DUMMY_NODE_VECTOR3  EBS;

EV_ EnvEBS_SendACL: 0 [0|1] "" 0 6 DUMMY_NODE_VECTOR3  EBS;

EV_ EnvOpenOnlineHelpForThisDemo: 0 [0|0] "" 0 7 DUMMY_NODE_VECTOR0 Vector__XXX;

EV_ EnvSendShortDM1: 0 [0|1] "" 0 8 DUMMY_NODE_VECTOR0 Vector__XXX;

EV_ EnvEnable_Bug_Table03_Row07: 0 [0|1] "" 0 9 DUMMY_NODE_VECTOR0 Vector__XXX;

EV_ EnvEnable_Bug_Table03_Row06: 0 [0|1] "" 0 10 DUMMY_NODE_VECTOR0 Vector__XXX;

EV_ EnvEnable_Bug_Table03_Row05: 0 [0|1] "" 0 11 DUMMY_NODE_VECTOR0 Vector__XXX;

EV_ EnvEnable_Bug_Table03_Row04: 0 [0|1] "" 0 12 DUMMY_NODE_VECTOR0 Vector__XXX;

EV_ EnvEnable_Bug_Table03_Row03: 0 [0|1] "" 0 13 DUMMY_NODE_VECTOR0 Vector__XXX;

EV_ EnvEnable_Bug_Table03_Row02: 0 [0|1] "" 0 14 DUMMY_NODE_VECTOR0 Vector__XXX;

EV_ EnvVehicleSpeed: 1 [0|0] "km/h" 0 15 DUMMY_NODE_VECTOR0 Vector__XXX;

EV_ EnvEBS_FaultBrakePedalPos: 0 [0|1] "" 0 16 DUMMY_NODE_VECTOR1  EBS;

EV_ EnvEBS_FaultAppPressureError: 0 [0|1] "" 0 17 DUMMY_NODE_VECTOR1  EBS;

EV_ EnvEBS_BrakePedalPos: 0 [0|10] "" 0 18 DUMMY_NODE_VECTOR3  EBS;

EV_ EnvIgnitionSwitch: 0 [0|2] "" 2 19 DUMMY_NODE_VECTOR0 Vector__XXX;

EV_ EnvEBS_SimulationMode: 0 [0|1] "" 1 20 DUMMY_NODE_VECTOR3 Vector__XXX;
CM_ SG_ 3221225472 RqedPercentFanSpeed "Fan speed as a ratio of the actual fan drive (current speed) to the fully engaged fan drive (maximum fan speed).";
CM_ SG_ 3221225472 CbA_CRfrgrntCmprssorOutletPress "This is the gage pressure at the compressor outlet in the cab air conditioning system.";
CM_ SG_ 3221225472 RelativeLevelRearAxleRight "Information of the height at the left side of the rear axle referred to normal level 1.";
CM_ SG_ 3221225472 RelativeLevelRearAxleLeft "Information of the height at the left side of the rear axle referred to normal level 1.";
CM_ SG_ 3221225472 RelativeLevelFrontAxleRight "Information of the height at the right side of the front axle referred to normal level 1.";
CM_ SG_ 3221225472 RelativeLevelFrontAxleLeft "Information of the height at the left side of the front axle referred to normal level 1.";
CM_ SG_ 3221225472 SspensionCtrlRefusalInformation "Signal which indicates that the air suspension control cannot perform a request due to the operating conditions.";
CM_ SG_ 3221225472 SuspensionRemoteCtrl2 "Signal which indicates that the suspension system is controlled by remote control #2.";
CM_ SG_ 3221225472 SuspensionRemoteCtrl1 "Signal which indicates that the suspension system is controlled by remote control #1.";
CM_ SG_ 3221225472 RearAxleInBumperRange "Signal which indicates that the vehicle height at the rear axle (SPNs 1723 and 1724) is within the bumper range.";
CM_ SG_ 3221225472 FrontAxleInBumperRange "Signal which indicates that the vehicle height at the front axle (SPNs 1721 and 1722) is within the bumper range.";
CM_ SG_ 3221225472 DoorRelease "Signal which indicates that the doors may be opened.";
CM_ SG_ 3221225472 VehicleMotionInhibit "Signal which indicates whether vehicle motion is inhibited.";
CM_ SG_ 3221225472 SecurityDevice "The signal which indicates the status of the security device.";
CM_ SG_ 3221225472 AboveNominalLevelRearAxle "Signal which indicates whether the actual height of the rear axle is above the nominal (desired) level of the rear axle.";
CM_ SG_ 3221225472 AboveNominalLevelFrontAxle "Signal which indicates whether the actual height of the front axle is above the nominal (desired) level of the front axle.";
CM_ SG_ 3221225472 BelowNominalLevelRearAxle "Signal which indicates whether the actual height of the rear axle is below the nominal (desired) level for the rear axle.";
CM_ SG_ 3221225472 BelowNominalLevelFrontAxle "Signal which indicates whether the actual height of the front axle is below the nominal (desired) level for the front axle.";
CM_ SG_ 3221225472 NominalLevelRearAxle "Signal which indicates the nominal (desired) height of the rear axle to be controlled by the suspension system.";
CM_ SG_ 3221225472 NominalLevelFrontAxle "Signal which indicates the nominal (desired) height of the front axle to be controlled by the suspension system.";
CM_ SG_ 3221225472 LiftAxle2Pos "Signal which indicates the position / load condition of lift axle / tag axle #2.";
CM_ SG_ 3221225472 LiftAxle1Pos "Signal which indicates the position / load condition of lift axle / tag axle #1.";
CM_ SG_ 3221225472 UseTransferMode "Requester is to respond via the Transfer PGN";
CM_ SG_ 3221225472 ParameterGroupNumber "PGN which is requested by Request2 message";
CM_ SG_ 3221225472 RoadSurfaceTemp "Indicated temperature of road surface over which vehicle is operating.";
CM_ SG_ 3221225472 EngAirInletTemp "Temperature of air entering vehicle air induction system.";
CM_ SG_ 3221225472 AmbientAirTemp "Temperature of air surrounding vehicle.";
CM_ SG_ 3221225472 CabInteriorTemp "Temperature of air inside the part of the vehicle that encloses the driver and vehicle operating controls.";
CM_ SG_ 3221225472 BarometricPress "Absolute air pressure of the atmosphere.";
CM_ SG_ 3221225472 TransOilLevelHigh_Low "Amount of current volume of transmission sump oil compared to recommended volume.";
CM_ SG_ 3221225472 TransOilTemp "Temperature of the transmission lubricant.";
CM_ SG_ 3221225472 TransOilPress "Gage pressure of lubrication fluid in transmission, measured after pump.";
CM_ SG_ 3221225472 TransOilLevel "Ratio of volume of transmission sump oil to recommended volume.";
CM_ SG_ 3221225472 ClutchPress "Gage pressure of oil within a wet clutch.";
CM_ SG_ 3221225472 BatteryPotentialSwitched "Electrical potential measured at the input of the electronic control unit supplied through a switching device.";
CM_ SG_ 3221225472 ElectricalPotential "Measured electrical potential of the battery.";
CM_ SG_ 3221225472 ChargingSystemPotential "Electrical potential measured at the charging system output.";
CM_ SG_ 3221225472 AltCurrent "Measure of electrical current flow from the alternator.";
CM_ SG_ 3221225472 NetBatteryCurrent "Net flow of electrical current into/out of the battery or batteries.";
CM_ SG_ 3221225472 TotalNumberOfPacketsEoMA "Total number of packets for BAM message.Total number of packets received for RTS/CTS message.Total number of packets for RTS/CTS message.";
CM_ SG_ 3221225472 TotalMessageSizeEoMA "Total message size (in bytes) for BAM message.Total message size (in bytes) for RTS/CTS message.Total message size (in bytes) for RTS/CTS message.";
CM_ SG_ 3221225472 TotalMessageSizeBAM "Total message size (in bytes) for BAM message.Total message size (in bytes) for RTS/CTS message.Total message size (in bytes) for RTS/CTS message.";
CM_ SG_ 3221225472 TotalNumberOfPacketsBAM "Total number of packets for BAM message.Total number of packets received for RTS/CTS message.Total number of packets for RTS/CTS message.";
CM_ SG_ 3221225472 ConnectionAbortReason "Reason for connection abort message.";
CM_ SG_ 3221225472 NextPacketNumberToBeSent "Next Packet Number to be sent (TP.CM_CTS)";
CM_ SG_ 3221225472 NumberOfPacketsThatCanBeSent "Number of Packets that can be sent (TP.CM_CTS)";
CM_ SG_ 3221225472 MaximumNumberOfPackets "Maximum number of packets for RTS/CTS message.";
CM_ SG_ 3221225472 TotalNumberOfPackets "Total number of packets for BAM message.Total number of packets received for RTS/CTS message.Total number of packets for RTS/CTS message.";
CM_ SG_ 3221225472 TotalMessageSize "Total message size (in bytes) for BAM message.Total message size (in bytes) for RTS/CTS message.Total message size (in bytes) for RTS/CTS message.";
CM_ SG_ 3221225472 DTC5 "Diagnostic Trouble CodeDiagnostic Trouble CodeDiagnostic Trouble CodeDiagnostic Trouble Code";
CM_ SG_ 3221225472 DTC4 "Diagnostic Trouble CodeDiagnostic Trouble CodeDiagnostic Trouble CodeDiagnostic Trouble Code";
CM_ SG_ 3221225472 DTC3 "Diagnostic Trouble CodeDiagnostic Trouble CodeDiagnostic Trouble CodeDiagnostic Trouble Code";
CM_ SG_ 3221225472 DTC2 "Diagnostic Trouble CodeDiagnostic Trouble CodeDiagnostic Trouble CodeDiagnostic Trouble Code";
CM_ SG_ 3221225472 DTC1 "Diagnostic Trouble CodeDiagnostic Trouble CodeDiagnostic Trouble CodeDiagnostic Trouble CodeDiagnostic Trouble Code";
CM_ SG_ 3221225472 SPNSupported1High "This parameter defines the SPN(s) that is/are supported for the freeze frame and/or data stream information.";
CM_ SG_ 3221225472 SPNSupportTypeSTR3 "This parameter defines whether the applicable parameter (that is the SPN) is supported in the freeze frame, the data stream or both the freeze frame and data stream.";
CM_ SG_ 3221225472 SPNSupportTypeSTR2 "This parameter defines whether the applicable parameter (that is the SPN) is supported in the freeze frame, the data stream or both the freeze frame and data stream.";
CM_ SG_ 3221225472 SPNSupportTypeEFF3 "This parameter defines whether the applicable parameter (that is the SPN) is supported in the freeze frame, the data stream or both the freeze frame and data stream.";
CM_ SG_ 3221225472 SPNSupportTypeEFF2 "This parameter defines whether the applicable parameter (that is the SPN) is supported in the freeze frame, the data stream or both the freeze frame and data stream.";
CM_ SG_ 3221225472 SPNSupportTypeDS3 "This parameter defines whether the applicable parameter (that is the SPN) is supported in the freeze frame, the data stream or both the freeze frame and data stream.";
CM_ SG_ 3221225472 SPNSupportTypeDS2 "This parameter defines whether the applicable parameter (that is the SPN) is supported in the freeze frame, the data stream or both the freeze frame and data stream.";
CM_ SG_ 3221225472 SPNSupported3High "This parameter defines the SPN(s) that is/are supported for the freeze frame and/or data stream information.";
CM_ SG_ 3221225472 SPNSupported2High "This parameter defines the SPN(s) that is/are supported for the freeze frame and/or data stream information.";
CM_ SG_ 3221225472 SPNSupported3 "This parameter defines the SPN(s) that is/are supported for the freeze frame and/or data stream information.";
CM_ SG_ 3221225472 SPNSupported2 "This parameter defines the SPN(s) that is/are supported for the freeze frame and/or data stream information.";
CM_ SG_ 3221225472 SPNDataLength3 "The number of data bytes associated with the SPN in the Freeze Frame.";
CM_ SG_ 3221225472 SPNSupportTypeSTR1 "This parameter defines whether the applicable parameter (that is the SPN) is supported in the freeze frame, the data stream or both the freeze frame and data stream.";
CM_ SG_ 3221225472 SPNSupportTypeDS1 "This parameter defines whether the applicable parameter (that is the SPN) is supported in the freeze frame, the data stream or both the freeze frame and data stream.";
CM_ SG_ 3221225472 SPNSupportTypeEFF1 "This parameter defines whether the applicable parameter (that is the SPN) is supported in the freeze frame, the data stream or both the freeze frame and data stream.";
CM_ SG_ 3221225472 SPNDataLength2 "The number of data bytes associated with the SPN in the Freeze Frame.";
CM_ SG_ 3221225472 SPNDataLength1 "The number of data bytes associated with the SPN in the Freeze Frame.";
CM_ SG_ 3221225472 SPNSupported1 "This parameter defines the SPN(s) that is/are supported for the freeze frame and/or data stream information.";
CM_ SG_ 3221225472 ExpandedFreezeFrameLength "The freeze frame length shall be equal to the number of bytes in the required parameters plus the number of bytes in the
manufacturer specific parameters.";
CM_ SG_ 3221225472 FreezeFrameLength "The freeze frame length shall be equal to the number of bytes in the required parameters plus the number of bytes in the
manufacturer specific parameters.";
CM_ SG_ 3221225472 OBDCompliance "Identifies the OBD compliance capabilityof the responding controller.";
CM_ SG_ 3221225472 PreviouslyActiveTroubleCodes "Identifies the number of previously active trouble codes that are present in a specific controller.";
CM_ SG_ 3221225472 ActiveTroubleCodes "Identifies the number of active trouble codes that are present in a specific controller.";
CM_ SG_ 3221225472 ShrtNameOfActualReportingDevice "Short name of reporting device of the requested PGN via the Transfer PGN.";
CM_ SG_ 3221225472 LengthOfDataForTheReportedPGN "Length of data reported with the associated PGN via the Transfer PGN.";
CM_ SG_ 3221225472 PGNofRequstedInformation "PGN associated with this transfer message";
CM_ BO_ 2566838526 "Commanded Address";
CM_ SG_ 2566838526 AddressAssignment "The source address that is to be assigned to the CA that has the NAME corresponding to the one conveyed in the first eight bytes of this Commanded Address message.";
CM_ SG_ 2566838526 IndustryGroup "0 = Global; 
   1  = On-Highway; 
   2  = Agricultural and Forestry; 
   3  = Construction; 
   4  = Marine;
   5  = Industrial - Process
          Control - Stationary (Gen-Sets)
   6  = Reserve for SAE
   7  = Reserve for SAE";
CM_ SG_ 2566838526 ManufacturerCode "Assigned by NMEA 2000 Committee";
CM_ BO_ 2565799424 "Address Claimed";
CM_ SG_ 2565799424 IndustryGroup "0 = Global; 
   1  = On-Highway; 
   2  = Agricultural and Forestry; 
   3  = Construction; 
   4  = Marine;
   5  = Industrial - Process
          Control - Stationary (Gen-Sets)
   6  = Reserve for SAE
   7  = Reserve for SAE";
CM_ SG_ 2565799424 ManufacturerCode "Assigned by NMEA 2000 Committee";
CM_ BO_ 2565406208 "Acknowledgment Message";
CM_ SG_ 2565406208 ParameterGroupNumber "PGN which is requested by Request2 message";
CM_ SG_ 2565406208 GroupFunctionValue "Indicates the acknowledgement response.Indicates the acknowledgement response.Negative Acknowledgement Group Function valuePositive Acknowledgement Group Function value";
CM_ BO_ 2565406259 "Acknowledgment Message";
CM_ SG_ 2565406259 ParameterGroupNumber "PGN which is requested by Request2 message";
CM_ SG_ 2565406259 GroupFunctionValue "Indicates the acknowledgement response.Indicates the acknowledgement response.Negative Acknowledgement Group Function valuePositive Acknowledgement Group Function value";
CM_ BO_ 2565799475 "Address Claimed";
CM_ SG_ 2565799475 IndustryGroup "0 = Global; 
   1  = On-Highway; 
   2  = Agricultural and Forestry; 
   3  = Construction; 
   4  = Marine;
   5  = Industrial - Process
          Control - Stationary (Gen-Sets)
   6  = Reserve for SAE
   7  = Reserve for SAE";
CM_ SG_ 2565799475 ManufacturerCode "Assigned by NMEA 2000 Committee";
CM_ BO_ 2565485323 "Request";
CM_ SG_ 2565485323 ParameterGroupNumber "PGN which is requested by Request2 message";
CM_ BO_ 2566834699 "Active diagnostic trouble codes";
CM_ SG_ 2566834699 DTC5 "Diagnostic Trouble Code";
CM_ SG_ 2566834699 DTC4 "Diagnostic Trouble Code";
CM_ SG_ 2566834699 DTC3 "Diagnostic Trouble Code";
CM_ SG_ 2566834699 DTC2 "Diagnostic Trouble Code";
CM_ SG_ 2566834699 DTC1 "Diagnostic Trouble Code";
CM_ SG_ 2566834699 FlashRedStopLamp "This parameter provides the capability to flash the RSL (SPN 3039).";
CM_ SG_ 2566834699 FlashProtectLamp "This parameter provides the capability to flash the engine protect lamp (SPN 3041).";
CM_ SG_ 2566834699 FlashMalfuncIndicatorLamp "This parameter provides the capability to flash the MIL (SPN 3038).";
CM_ SG_ 2566834699 FlashAmberWarningLamp "This parameter provides the capability to flash the AWL (SPN 3040). ";
CM_ SG_ 2566834699 MalfunctionIndicatorLampStatus "A lamp used to relay only emissions-related trouble code information.";
CM_ SG_ 2566834699 AmberWarningLampStatus "This lamp is used to relay trouble code information that is reporting a problem with the vehicle system but the vehicle need
not be immediately stopped.";
CM_ SG_ 2566834699 RedStopLampState "This lamp is uesed to relay trouble code information that is of a severe enought condition that it warrants stopping the vehicle.";
CM_ SG_ 2566834699 ProtectLampStatus "This lamp is used to relay trouble code informatio that is reporting a problem with a vehicle system that is most
probably not electronic subsystem related.";
CM_ BO_ 2566834955 "Previously active diagnostic trouble codes";
CM_ SG_ 2566834955 DTC5 "Diagnostic Trouble Code";
CM_ SG_ 2566834955 DTC4 "Diagnostic Trouble Code";
CM_ SG_ 2566834955 DTC3 "Diagnostic Trouble Code";
CM_ SG_ 2566834955 DTC2 "Diagnostic Trouble Code";
CM_ SG_ 2566834955 DTC1 "Diagnostic Trouble Code";
CM_ SG_ 2566834955 MalfunctionIndicatorLampStatus "A lamp used to relay only emissions-related trouble code information.";
CM_ SG_ 2566834955 RedStopLampState "This lamp is uesed to relay trouble code information that is of a severe enought condition that it warrants stopping the vehicle.";
CM_ SG_ 2566834955 AmberWarningLampStatus "This lamp is used to relay trouble code information that is reporting a problem with the vehicle system but the vehicle need
not be immediately stopped.";
CM_ SG_ 2566834955 ProtectLampStatus "This lamp is used to relay trouble code informatio that is reporting a problem with a vehicle system that is most
probably not electronic subsystem related.";
CM_ SG_ 2566834955 FlashRedStopLamp "This parameter provides the capability to flash the RSL (SPN 3039).";
CM_ SG_ 2566834955 FlashProtectLamp "This parameter provides the capability to flash the engine protect lamp (SPN 3041).";
CM_ SG_ 2566834955 FlashMalfuncIndicatorLamp "This parameter provides the capability to flash the MIL (SPN 3038).";
CM_ SG_ 2566834955 FlashAmberWarningLamp "This parameter provides the capability to flash the AWL (SPN 3040). ";
CM_ BO_ 2566764043 "SPN Support. This message is used to identify those SPNs supported by the product for freeze frames and data stream messages.";
CM_ SG_ 2566764043 SPNSupported1High "This parameter defines the SPN(s) that is/are supported for the freeze frame and/or data stream information.";
CM_ SG_ 2566764043 SPNSupportTypeSTR3 "This parameter defines whether the applicable parameter (that is the SPN) is supported in the freeze frame, the data stream or both the freeze frame and data stream.";
CM_ SG_ 2566764043 SPNSupportTypeSTR2 "This parameter defines whether the applicable parameter (that is the SPN) is supported in the freeze frame, the data stream or both the freeze frame and data stream.";
CM_ SG_ 2566764043 SPNSupportTypeEFF3 "This parameter defines whether the applicable parameter (that is the SPN) is supported in the freeze frame, the data stream or both the freeze frame and data stream.";
CM_ SG_ 2566764043 SPNSupportTypeEFF2 "This parameter defines whether the applicable parameter (that is the SPN) is supported in the freeze frame, the data stream or both the freeze frame and data stream.";
CM_ SG_ 2566764043 SPNSupportTypeDS3 "This parameter defines whether the applicable parameter (that is the SPN) is supported in the freeze frame, the data stream or both the freeze frame and data stream.";
CM_ SG_ 2566764043 SPNSupportTypeDS2 "This parameter defines whether the applicable parameter (that is the SPN) is supported in the freeze frame, the data stream or both the freeze frame and data stream.";
CM_ SG_ 2566764043 SPNSupported3High "This parameter defines the SPN(s) that is/are supported for the freeze frame and/or data stream information.";
CM_ SG_ 2566764043 SPNSupported2High "This parameter defines the SPN(s) that is/are supported for the freeze frame and/or data stream information.";
CM_ SG_ 2566764043 SPNSupported3 "This parameter defines the SPN(s) that is/are supported for the freeze frame and/or data stream information.";
CM_ SG_ 2566764043 SPNSupported2 "This parameter defines the SPN(s) that is/are supported for the freeze frame and/or data stream information.";
CM_ SG_ 2566764043 SPNDataLength3 "The number of data bytes associated with the SPN in the Freeze Frame.";
CM_ SG_ 2566764043 SPNSupportTypeSTR1 "This parameter defines whether the applicable parameter (that is the SPN) is supported in the freeze frame, the data stream or both the freeze frame and data stream.";
CM_ SG_ 2566764043 SPNSupportTypeDS1 "This parameter defines whether the applicable parameter (that is the SPN) is supported in the freeze frame, the data stream or both the freeze frame and data stream.";
CM_ SG_ 2566764043 SPNSupportTypeEFF1 "This parameter defines whether the applicable parameter (that is the SPN) is supported in the freeze frame, the data stream or both the freeze frame and data stream.";
CM_ SG_ 2566764043 SPNDataLength2 "The number of data bytes associated with the SPN in the Freeze Frame.";
CM_ SG_ 2566764043 SPNDataLength1 "The number of data bytes associated with the SPN in the Freeze Frame.";
CM_ SG_ 2566764043 SPNSupported1 "This parameter defines the SPN(s) that is/are supported for the freeze frame and/or data stream information.";
CM_ BO_ 2566764299 "Expanded freeze frame.";
CM_ SG_ 2566764299 DTC1 "Diagnostic Trouble Code";
CM_ SG_ 2566764299 ExpandedFreezeFrameLength "The freeze frame length shall be equal to the number of bytes in the required parameters plus the number of bytes in the
manufacturer specific parameters.";
CM_ BO_ 2566835467 "Freeze frame parameters";
CM_ SG_ 2566835467 DTC1 "Diagnostic Trouble Code";
CM_ SG_ 2566835467 FreezeFrameLength "The freeze frame length shall be equal to the number of bytes in the required parameters plus the number of bytes in the
manufacturer specific parameters.";
CM_ SG_ 2566835467 EngSpeed "Actual engine speed which is calculated over a minimum crankshaft angle of 720 degrees divided by the number of cylinders.";
CM_ SG_ 2566835467 EngTorqueMode "State signal which indicates which engine torque mode is currently generating, limiting, or controlling the torque.";
CM_ SG_ 2566835467 EngTurboBoostPress "Gage pressure of air measured downstream on the compressor discharge side of the turbocharger.";
CM_ SG_ 2566835467 WheelBasedVehicleSpeed "Speed of the vehicle as calculated from wheel or tailshaft speed.";
CM_ BO_ 2565799435 "Address Claimed";
CM_ SG_ 2565799435 IndustryGroup "0 = Global; 
   1  = On-Highway; 
   2  = Agricultural and Forestry; 
   3  = Construction; 
   4  = Marine;
   5  = Industrial - Process
          Control - Stationary (Gen-Sets)
   6  = Reserve for SAE
   7  = Reserve for SAE";
CM_ SG_ 2565799435 ManufacturerCode "Assigned by NMEA 2000 Committee";
CM_ BO_ 2565602827 "Transport Protocol - Data Transfer";
CM_ BO_ 2565668363 "Transport Protocol - Connection Management";
CM_ SG_ 2565668363 TotalNumberOfPacketsEoMA "Total number of packets for BAM message.Total number of packets received for RTS/CTS message.Total number of packets for RTS/CTS message.";
CM_ SG_ 2565668363 TotalMessageSizeEoMA "Total message size (in bytes) for BAM message.Total message size (in bytes) for RTS/CTS message.Total message size (in bytes) for RTS/CTS message.";
CM_ SG_ 2565668363 TotalMessageSizeBAM "Total message size (in bytes) for BAM message.Total message size (in bytes) for RTS/CTS message.Total message size (in bytes) for RTS/CTS message.";
CM_ SG_ 2565668363 TotalNumberOfPacketsBAM "Total number of packets for BAM message.Total number of packets received for RTS/CTS message.Total number of packets for RTS/CTS message.";
CM_ SG_ 2565668363 ConnectionAbortReason "Reason for connection abort message.";
CM_ SG_ 2565668363 NextPacketNumberToBeSent "Next Packet Number to be sent (TP.CM_CTS)";
CM_ SG_ 2565668363 NumberOfPacketsThatCanBeSent "Number of Packets that can be sent (TP.CM_CTS)";
CM_ SG_ 2565668363 MaximumNumberOfPackets "Maximum number of packets for RTS/CTS message.";
CM_ SG_ 2565668363 TotalNumberOfPackets "Total number of packets for BAM message.Total number of packets received for RTS/CTS message.Total number of packets for RTS/CTS message.";
CM_ SG_ 2565668363 TotalMessageSize "Total message size (in bytes) for BAM message.Total message size (in bytes) for RTS/CTS message.Total message size (in bytes) for RTS/CTS message.";
CM_ BO_ 2565406219 "Acknowledgment Message";
CM_ SG_ 2565406219 ParameterGroupNumber "PGN which is requested by Request2 message";
CM_ SG_ 2565406219 GroupFunctionValue "Indicates the acknowledgement response.Indicates the acknowledgement response.Negative Acknowledgement Group Function valuePositive Acknowledgement Group Function value";
CM_ BO_ 2562981630 "Individual Clear/Reset of active and previously active DTC.";
CM_ SG_ 2562981630 SPN1 "SPN #1 (Conversion Version 4)";
CM_ SG_ 2562981630 SPN1High "SPN #1 (Conversion Version 4)";
CM_ SG_ 2562981630 FailureModeIdentifier1 "The FMI defines the type of failure detected in the subsystem identified by an SPN.";
CM_ BO_ 2566836222 "Pending DTCs";
CM_ SG_ 2566836222 DTC5 "Diagnostic Trouble Code";
CM_ SG_ 2566836222 DTC4 "Diagnostic Trouble Code";
CM_ SG_ 2566836222 DTC3 "Diagnostic Trouble Code";
CM_ SG_ 2566836222 DTC2 "Diagnostic Trouble Code";
CM_ SG_ 2566836222 DTC1 "Diagnostic Trouble Code";
CM_ SG_ 2566836222 FlashRedStopLamp "This parameter provides the capability to flash the RSL (SPN 3039).";
CM_ SG_ 2566836222 FlashProtectLamp "This parameter provides the capability to flash the engine protect lamp (SPN 3041).";
CM_ SG_ 2566836222 FlashMalfuncIndicatorLamp "This parameter provides the capability to flash the MIL (SPN 3038).";
CM_ SG_ 2566836222 MalfunctionIndicatorLampStatus "A lamp used to relay only emissions-related trouble code information.";
CM_ SG_ 2566836222 RedStopLampState "This lamp is uesed to relay trouble code information that is of a severe enought condition that it warrants stopping the vehicle.";
CM_ SG_ 2566836222 AmberWarningLampStatus "This lamp is used to relay trouble code information that is reporting a problem with the vehicle system but the vehicle need
not be immediately stopped.";
CM_ SG_ 2566836222 ProtectLampStatus "This lamp is used to relay trouble code informatio that is reporting a problem with a vehicle system that is most
probably not electronic subsystem related.";
CM_ BO_ 2566835966 "Diagnostic readiness 1";
CM_ SG_ 2566835966 OBDCompliance "Identifies the OBD compliance capabilityof the responding controller.";
CM_ SG_ 2566835966 PreviouslyActiveTroubleCodes "Identifies the number of previously active trouble codes that are present in a specific controller.";
CM_ SG_ 2566835966 ActiveTroubleCodes "Identifies the number of active trouble codes that are present in a specific controller.";
CM_ BO_ 2566835710 "Freeze frame parameters";
CM_ SG_ 2566835710 DTC1 "Diagnostic Trouble Code";
CM_ SG_ 2566835710 FreezeFrameLength "The freeze frame length shall be equal to the number of bytes in the required parameters plus the number of bytes in the
manufacturer specific parameters.";
CM_ SG_ 2566835710 EngSpeed "Actual engine speed which is calculated over a minimum crankshaft angle of 720 degrees divided by the number of cylinders.";
CM_ SG_ 2566835710 EngTorqueMode "State signal which indicates which engine torque mode is currently generating, limiting, or controlling the torque.";
CM_ SG_ 2566835710 EngTurboBoostPress "Gage pressure of air measured downstream on the compressor discharge side of the turbocharger.";
CM_ SG_ 2566835710 WheelBasedVehicleSpeed "Speed of the vehicle as calculated from wheel or tailshaft speed.";
CM_ BO_ 2566835454 "Diagnostic data clear/reset of previously active DTCs.";
CM_ BO_ 2566764542 "Expanded freeze frame.";
CM_ SG_ 2566764542 DTC1 "Diagnostic Trouble Code";
CM_ SG_ 2566764542 ExpandedFreezeFrameLength "The freeze frame length shall be equal to the number of bytes in the required parameters plus the number of bytes in the
manufacturer specific parameters.";
CM_ BO_ 2566764286 "SPN Support. This message is used to identify those SPNs supported by the product for freeze frames and data stream messages.";
CM_ SG_ 2566764286 SPNSupported1High "This parameter defines the SPN(s) that is/are supported for the freeze frame and/or data stream information.";
CM_ SG_ 2566764286 SPNSupportTypeSTR3 "This parameter defines whether the applicable parameter (that is the SPN) is supported in the freeze frame, the data stream or both the freeze frame and data stream.";
CM_ SG_ 2566764286 SPNSupportTypeSTR2 "This parameter defines whether the applicable parameter (that is the SPN) is supported in the freeze frame, the data stream or both the freeze frame and data stream.";
CM_ SG_ 2566764286 SPNSupportTypeEFF3 "This parameter defines whether the applicable parameter (that is the SPN) is supported in the freeze frame, the data stream or both the freeze frame and data stream.";
CM_ SG_ 2566764286 SPNSupportTypeEFF2 "This parameter defines whether the applicable parameter (that is the SPN) is supported in the freeze frame, the data stream or both the freeze frame and data stream.";
CM_ SG_ 2566764286 SPNSupportTypeDS3 "This parameter defines whether the applicable parameter (that is the SPN) is supported in the freeze frame, the data stream or both the freeze frame and data stream.";
CM_ SG_ 2566764286 SPNSupportTypeDS2 "This parameter defines whether the applicable parameter (that is the SPN) is supported in the freeze frame, the data stream or both the freeze frame and data stream.";
CM_ SG_ 2566764286 SPNSupported3High "This parameter defines the SPN(s) that is/are supported for the freeze frame and/or data stream information.";
CM_ SG_ 2566764286 SPNSupported2High "This parameter defines the SPN(s) that is/are supported for the freeze frame and/or data stream information.";
CM_ SG_ 2566764286 SPNSupported3 "This parameter defines the SPN(s) that is/are supported for the freeze frame and/or data stream information.";
CM_ SG_ 2566764286 SPNSupported2 "This parameter defines the SPN(s) that is/are supported for the freeze frame and/or data stream information.";
CM_ SG_ 2566764286 SPNDataLength3 "The number of data bytes associated with the SPN in the Freeze Frame.";
CM_ SG_ 2566764286 SPNSupportTypeSTR1 "This parameter defines whether the applicable parameter (that is the SPN) is supported in the freeze frame, the data stream or both the freeze frame and data stream.";
CM_ SG_ 2566764286 SPNSupportTypeDS1 "This parameter defines whether the applicable parameter (that is the SPN) is supported in the freeze frame, the data stream or both the freeze frame and data stream.";
CM_ SG_ 2566764286 SPNSupportTypeEFF1 "This parameter defines whether the applicable parameter (that is the SPN) is supported in the freeze frame, the data stream or both the freeze frame and data stream.";
CM_ SG_ 2566764286 SPNDataLength2 "The number of data bytes associated with the SPN in the Freeze Frame.";
CM_ SG_ 2566764286 SPNDataLength1 "The number of data bytes associated with the SPN in the Freeze Frame.";
CM_ SG_ 2566764286 SPNSupported1 "This parameter defines the SPN(s) that is/are supported for the freeze frame and/or data stream information.";
CM_ BO_ 2566835198 "Previously active diagnostic trouble codes";
CM_ SG_ 2566835198 DTC5 "Diagnostic Trouble Code";
CM_ SG_ 2566835198 DTC4 "Diagnostic Trouble Code";
CM_ SG_ 2566835198 DTC3 "Diagnostic Trouble Code";
CM_ SG_ 2566835198 DTC2 "Diagnostic Trouble Code";
CM_ SG_ 2566835198 DTC1 "Diagnostic Trouble Code";
CM_ SG_ 2566835198 MalfunctionIndicatorLampStatus "A lamp used to relay only emissions-related trouble code information.";
CM_ SG_ 2566835198 RedStopLampState "This lamp is uesed to relay trouble code information that is of a severe enought condition that it warrants stopping the vehicle.";
CM_ SG_ 2566835198 AmberWarningLampStatus "This lamp is used to relay trouble code information that is reporting a problem with the vehicle system but the vehicle need
not be immediately stopped.";
CM_ SG_ 2566835198 ProtectLampStatus "This lamp is used to relay trouble code informatio that is reporting a problem with a vehicle system that is most
probably not electronic subsystem related.";
CM_ SG_ 2566835198 FlashRedStopLamp "This parameter provides the capability to flash the RSL (SPN 3039).";
CM_ SG_ 2566835198 FlashProtectLamp "This parameter provides the capability to flash the engine protect lamp (SPN 3041).";
CM_ SG_ 2566835198 FlashMalfuncIndicatorLamp "This parameter provides the capability to flash the MIL (SPN 3038).";
CM_ SG_ 2566835198 FlashAmberWarningLamp "This parameter provides the capability to flash the AWL (SPN 3040). ";
CM_ BO_ 2564030206 "Calibration Information";
CM_ BO_ 2566837502 "Emissions-related active diagnostic trouble codes.";
CM_ SG_ 2566837502 DTC5 "Diagnostic Trouble Code";
CM_ SG_ 2566837502 DTC4 "Diagnostic Trouble Code";
CM_ SG_ 2566837502 DTC3 "Diagnostic Trouble Code";
CM_ SG_ 2566837502 DTC2 "Diagnostic Trouble Code";
CM_ SG_ 2566837502 FlashRedStopLamp "This parameter provides the capability to flash the RSL (SPN 3039).";
CM_ SG_ 2566837502 FlashProtectLamp "This parameter provides the capability to flash the engine protect lamp (SPN 3041).";
CM_ SG_ 2566837502 MalfunctionIndicatorLampStatus "A lamp used to relay only emissions-related trouble code information.";
CM_ SG_ 2566837502 RedStopLampState "This lamp is uesed to relay trouble code information that is of a severe enought condition that it warrants stopping the vehicle.";
CM_ SG_ 2566837502 AmberWarningLampStatus "This lamp is used to relay trouble code information that is reporting a problem with the vehicle system but the vehicle need
not be immediately stopped.";
CM_ SG_ 2566837502 ProtectLampStatus "This lamp is used to relay trouble code informatio that is reporting a problem with a vehicle system that is most
probably not electronic subsystem related.";
CM_ SG_ 2566837502 FlashMalfuncIndicatorLamp "This parameter provides the capability to flash the MIL (SPN 3038).";
CM_ SG_ 2566837502 FlashAmberWarningLamp "This parameter provides the capability to flash the AWL (SPN 3040). ";
CM_ SG_ 2566837502 SPN1 "SPN #1 (Conversion Version 4)";
CM_ BO_ 2566834942 "Active diagnostic trouble codes";
CM_ SG_ 2566834942 DTC5 "Diagnostic Trouble Code";
CM_ SG_ 2566834942 DTC4 "Diagnostic Trouble Code";
CM_ SG_ 2566834942 DTC3 "Diagnostic Trouble Code";
CM_ SG_ 2566834942 DTC2 "Diagnostic Trouble Code";
CM_ SG_ 2566834942 DTC1 "Diagnostic Trouble Code";
CM_ SG_ 2566834942 FlashRedStopLamp "This parameter provides the capability to flash the RSL (SPN 3039).";
CM_ SG_ 2566834942 FlashProtectLamp "This parameter provides the capability to flash the engine protect lamp (SPN 3041).";
CM_ SG_ 2566834942 FlashMalfuncIndicatorLamp "This parameter provides the capability to flash the MIL (SPN 3038).";
CM_ SG_ 2566834942 FlashAmberWarningLamp "This parameter provides the capability to flash the AWL (SPN 3040). ";
CM_ SG_ 2566834942 MalfunctionIndicatorLampStatus "A lamp used to relay only emissions-related trouble code information.";
CM_ SG_ 2566834942 AmberWarningLampStatus "This lamp is used to relay trouble code information that is reporting a problem with the vehicle system but the vehicle need
not be immediately stopped.";
CM_ SG_ 2566834942 RedStopLampState "This lamp is uesed to relay trouble code information that is of a severe enought condition that it warrants stopping the vehicle.";
CM_ SG_ 2566834942 ProtectLampStatus "This lamp is used to relay trouble code informatio that is reporting a problem with a vehicle system that is most
probably not electronic subsystem related.";
CM_ BO_ 2565799678 "Address Claimed";
CM_ SG_ 2565799678 IndustryGroup "0 = Global; 
   1  = On-Highway; 
   2  = Agricultural and Forestry; 
   3  = Construction; 
   4  = Marine;
   5  = Industrial - Process
          Control - Stationary (Gen-Sets)
   6  = Reserve for SAE
   7  = Reserve for SAE";
CM_ SG_ 2565799678 ManufacturerCode "Assigned by NMEA 2000 Committee";
CM_ BO_ 2563440382 "Transfer";
CM_ SG_ 2563440382 ShrtNameOfActualReportingDevice "Short name of reporting device of the requested PGN via the Transfer PGN.";
CM_ SG_ 2563440382 LengthOfDataForTheReportedPGN "Length of data reported with the associated PGN via the Transfer PGN.";
CM_ SG_ 2563440382 PGNofRequstedInformation "PGN associated with this transfer message";
CM_ BO_ 2565603070 "Transport Protocol - Data Transfer";
CM_ BO_ 2565668606 "Transport Protocol - Connection Management";
CM_ SG_ 2565668606 TotalNumberOfPacketsEoMA "Total number of packets for BAM message.Total number of packets received for RTS/CTS message.Total number of packets for RTS/CTS message.";
CM_ SG_ 2565668606 TotalMessageSizeEoMA "Total message size (in bytes) for BAM message.Total message size (in bytes) for RTS/CTS message.Total message size (in bytes) for RTS/CTS message.";
CM_ SG_ 2565668606 TotalMessageSizeBAM "Total message size (in bytes) for BAM message.Total message size (in bytes) for RTS/CTS message.Total message size (in bytes) for RTS/CTS message.";
CM_ SG_ 2565668606 TotalNumberOfPacketsBAM "Total number of packets for BAM message.Total number of packets received for RTS/CTS message.Total number of packets for RTS/CTS message.";
CM_ SG_ 2565668606 ConnectionAbortReason "Reason for connection abort message.";
CM_ SG_ 2565668606 NextPacketNumberToBeSent "Next Packet Number to be sent (TP.CM_CTS)";
CM_ SG_ 2565668606 NumberOfPacketsThatCanBeSent "Number of Packets that can be sent (TP.CM_CTS)";
CM_ SG_ 2565668606 MaximumNumberOfPackets "Maximum number of packets for RTS/CTS message.";
CM_ SG_ 2565668606 TotalNumberOfPackets "Total number of packets for BAM message.Total number of packets received for RTS/CTS message.Total number of packets for RTS/CTS message.";
CM_ SG_ 2565668606 TotalMessageSize "Total message size (in bytes) for BAM message.Total message size (in bytes) for RTS/CTS message.Total message size (in bytes) for RTS/CTS message.";
CM_ BO_ 2565537534 "Request";
CM_ SG_ 2565537534 ParameterGroupNumber "PGN which is requested by Request2 message";
CM_ BO_ 2565406462 "Acknowledgment Message";
CM_ SG_ 2565406462 ParameterGroupNumber "PGN which is requested by Request2 message";
CM_ SG_ 2565406462 GroupFunctionValue "Indicates the acknowledgement response.Indicates the acknowledgement response.Negative Acknowledgement Group Function valuePositive Acknowledgement Group Function value";
BA_DEF_ SG_  "SAEDocument" STRING ;
BA_DEF_ SG_  "GenSigEVName" STRING ;
BA_DEF_ BO_  "SAE_Document" STRING ;
BA_DEF_ BO_  "SingleFrame" INT 0 1;
BA_DEF_ SG_  "SigType" ENUM  "Default","Range","RangeSigned","ASCII","Discrete","Control","ReferencePGN","DTC","StringDelimiter","StringLength","StringLengthControl";
BA_DEF_ SG_  "GenSigStartValue" FLOAT 0 10000;
BA_DEF_ SG_  "GenSigSendType" ENUM  "Cyclic","OnWrite","reserved","OnChange","reserved","reserved","reserved","NoSigSendType";
BA_DEF_ SG_  "GenSigILSupport" ENUM  "Yes","No";
BA_DEF_ BO_  "GenMsgILSupport" ENUM  "Yes","No";
BA_DEF_ SG_  "SPN" INT 0 524287;
BA_DEF_ BO_  "GenMsgRequestable" INT 0 1;
BA_DEF_ BO_  "GenMsgSendType" ENUM  "cyclic","reserved","cyclicIfActive","reserved","reserved","reserved","reserved","reserved","noMsgSendType";
BA_DEF_ BO_  "VFrameFormat" ENUM  "StandardCAN","ExtendedCAN","reserved","J1939PG";
BA_DEF_ BO_  "GenMsgCycleTime" INT 0 3600000;
BA_DEF_DEF_  "SAEDocument" "";
BA_DEF_DEF_  "GenSigEVName" "Env@Nodename_@Signame";
BA_DEF_DEF_  "SAE_Document" "";
BA_DEF_DEF_  "SingleFrame" 1;
BA_DEF_DEF_  "SigType" "Default";
BA_DEF_DEF_  "GenSigStartValue" 0;
BA_DEF_DEF_  "GenSigSendType" "NoSigSendType";
BA_DEF_DEF_  "GenSigILSupport" "Yes";
BA_DEF_DEF_  "GenMsgILSupport" "Yes";
BA_DEF_DEF_  "SPN" 0;
BA_DEF_DEF_  "GenMsgRequestable" 1;
BA_DEF_DEF_  "GenMsgSendType" "noMsgSendType";
BA_DEF_DEF_  "VFrameFormat" "J1939PG";
BA_DEF_DEF_  "GenMsgCycleTime" 0;
BA_ "SAE_Document" BO_ 2566838526 "J1939-81";
BA_ "VFrameFormat" BO_ 2042 0;
BA_ "GenMsgSendType" BO_ 2566834699 0;
BA_ "GenMsgCycleTime" BO_ 2566834699 1000;
BA_ "GenMsgCycleTime" BO_ 2566834942 20;
BA_ "GenMsgSendType" BO_ 2566834942 0;
BA_ "SigType" SG_ 3221225472 RqedPercentFanSpeed 1;
BA_ "SPN" SG_ 3221225472 RqedPercentFanSpeed 986;
BA_ "SigType" SG_ 3221225472 IlluminationBrightnessPercent 1;
BA_ "SPN" SG_ 3221225472 IlluminationBrightnessPercent 1487;
BA_ "SigType" SG_ 3221225472 CbA_CRfrgrntCmprssorOutletPress 1;
BA_ "SPN" SG_ 3221225472 CbA_CRfrgrntCmprssorOutletPress 2609;
BA_ "SigType" SG_ 3221225472 RelativeLevelRearAxleRight 1;
BA_ "SPN" SG_ 3221225472 RelativeLevelRearAxleRight 1723;
BA_ "SigType" SG_ 3221225472 RelativeLevelRearAxleLeft 1;
BA_ "SPN" SG_ 3221225472 RelativeLevelRearAxleLeft 1724;
BA_ "SigType" SG_ 3221225472 RelativeLevelFrontAxleRight 1;
BA_ "SPN" SG_ 3221225472 RelativeLevelFrontAxleRight 1722;
BA_ "SigType" SG_ 3221225472 RelativeLevelFrontAxleLeft 1;
BA_ "SPN" SG_ 3221225472 RelativeLevelFrontAxleLeft 1721;
BA_ "SigType" SG_ 3221225472 SspensionCtrlRefusalInformation 4;
BA_ "SPN" SG_ 3221225472 SspensionCtrlRefusalInformation 1827;
BA_ "SigType" SG_ 3221225472 SuspensionRemoteCtrl2 4;
BA_ "SPN" SG_ 3221225472 SuspensionRemoteCtrl2 1825;
BA_ "SigType" SG_ 3221225472 SuspensionRemoteCtrl1 4;
BA_ "SPN" SG_ 3221225472 SuspensionRemoteCtrl1 1826;
BA_ "SigType" SG_ 3221225472 RearAxleInBumperRange 4;
BA_ "SPN" SG_ 3221225472 RearAxleInBumperRange 1823;
BA_ "SigType" SG_ 3221225472 FrontAxleInBumperRange 4;
BA_ "SPN" SG_ 3221225472 FrontAxleInBumperRange 1824;
BA_ "SigType" SG_ 3221225472 DoorRelease 4;
BA_ "SPN" SG_ 3221225472 DoorRelease 1744;
BA_ "SigType" SG_ 3221225472 VehicleMotionInhibit 4;
BA_ "SPN" SG_ 3221225472 VehicleMotionInhibit 1745;
BA_ "SigType" SG_ 3221225472 SecurityDevice 4;
BA_ "SPN" SG_ 3221225472 SecurityDevice 1746;
BA_ "SigType" SG_ 3221225472 LevelCtrlMode 4;
BA_ "SPN" SG_ 3221225472 LevelCtrlMode 1741;
BA_ "SigType" SG_ 3221225472 KneelingInformation 4;
BA_ "SPN" SG_ 3221225472 KneelingInformation 1742;
BA_ "SigType" SG_ 3221225472 LiftingCtrlModeRearAxle 4;
BA_ "SPN" SG_ 3221225472 LiftingCtrlModeRearAxle 1756;
BA_ "SigType" SG_ 3221225472 LiftingCtrlModeFrontAxle 4;
BA_ "SPN" SG_ 3221225472 LiftingCtrlModeFrontAxle 1739;
BA_ "SigType" SG_ 3221225472 LoweringCtrlModeRearAxle 4;
BA_ "SPN" SG_ 3221225472 LoweringCtrlModeRearAxle 1755;
BA_ "SigType" SG_ 3221225472 LoweringCtrlModeFrontAxle 4;
BA_ "SPN" SG_ 3221225472 LoweringCtrlModeFrontAxle 1740;
BA_ "SigType" SG_ 3221225472 AboveNominalLevelRearAxle 4;
BA_ "SPN" SG_ 3221225472 AboveNominalLevelRearAxle 1736;
BA_ "SigType" SG_ 3221225472 AboveNominalLevelFrontAxle 4;
BA_ "SPN" SG_ 3221225472 AboveNominalLevelFrontAxle 1737;
BA_ "SigType" SG_ 3221225472 BelowNominalLevelRearAxle 4;
BA_ "SPN" SG_ 3221225472 BelowNominalLevelRearAxle 1754;
BA_ "SigType" SG_ 3221225472 BelowNominalLevelFrontAxle 4;
BA_ "SPN" SG_ 3221225472 BelowNominalLevelFrontAxle 1738;
BA_ "SigType" SG_ 3221225472 NominalLevelRearAxle 4;
BA_ "SPN" SG_ 3221225472 NominalLevelRearAxle 1733;
BA_ "SigType" SG_ 3221225472 NominalLevelFrontAxle 4;
BA_ "SPN" SG_ 3221225472 NominalLevelFrontAxle 1734;
BA_ "SigType" SG_ 3221225472 LiftAxle2Pos 4;
BA_ "SPN" SG_ 3221225472 LiftAxle2Pos 1822;
BA_ "SigType" SG_ 3221225472 LiftAxle1Pos 4;
BA_ "SPN" SG_ 3221225472 LiftAxle1Pos 1743;
BA_ "SigType" SG_ 3221225472 UseTransferMode 4;
BA_ "SPN" SG_ 3221225472 UseTransferMode 2575;
BA_ "SigType" SG_ 3221225472 ParameterGroupNumber 1;
BA_ "SPN" SG_ 3221225472 ParameterGroupNumber 2574;
BA_ "SigType" SG_ 3221225472 RoadSurfaceTemp 1;
BA_ "SPN" SG_ 3221225472 RoadSurfaceTemp 79;
BA_ "SigType" SG_ 3221225472 EngAirInletTemp 1;
BA_ "SPN" SG_ 3221225472 EngAirInletTemp 172;
BA_ "SigType" SG_ 3221225472 AmbientAirTemp 1;
BA_ "SPN" SG_ 3221225472 AmbientAirTemp 171;
BA_ "SigType" SG_ 3221225472 CabInteriorTemp 1;
BA_ "SPN" SG_ 3221225472 CabInteriorTemp 170;
BA_ "SigType" SG_ 3221225472 BarometricPress 1;
BA_ "SPN" SG_ 3221225472 BarometricPress 108;
BA_ "SigType" SG_ 3221225472 TransOilLevelMeasurementStatus 4;
BA_ "SPN" SG_ 3221225472 TransOilLevelMeasurementStatus 3026;
BA_ "SigType" SG_ 3221225472 TransOilLevelCountdownTimer 4;
BA_ "SPN" SG_ 3221225472 TransOilLevelCountdownTimer 3028;
BA_ "SigType" SG_ 3221225472 TransOilLevelHigh_Low 1;
BA_ "SPN" SG_ 3221225472 TransOilLevelHigh_Low 3027;
BA_ "SigType" SG_ 3221225472 TransOilTemp 1;
BA_ "SPN" SG_ 3221225472 TransOilTemp 177;
BA_ "SigType" SG_ 3221225472 TransOilPress 1;
BA_ "SPN" SG_ 3221225472 TransOilPress 127;
BA_ "SigType" SG_ 3221225472 TransFilterDiffPress 1;
BA_ "SPN" SG_ 3221225472 TransFilterDiffPress 126;
BA_ "SigType" SG_ 3221225472 TransOilLevel 1;
BA_ "SPN" SG_ 3221225472 TransOilLevel 124;
BA_ "SigType" SG_ 3221225472 ClutchPress 1;
BA_ "SPN" SG_ 3221225472 ClutchPress 123;
BA_ "SigType" SG_ 3221225472 BatteryPotentialSwitched 1;
BA_ "GenSigILSupport" SG_ 3221225472 BatteryPotentialSwitched 1;
BA_ "SPN" SG_ 3221225472 BatteryPotentialSwitched 158;
BA_ "SigType" SG_ 3221225472 ElectricalPotential 1;
BA_ "SPN" SG_ 3221225472 ElectricalPotential 168;
BA_ "SigType" SG_ 3221225472 ChargingSystemPotential 1;
BA_ "GenSigILSupport" SG_ 3221225472 ChargingSystemPotential 1;
BA_ "SPN" SG_ 3221225472 ChargingSystemPotential 167;
BA_ "SigType" SG_ 3221225472 AltCurrent 1;
BA_ "SPN" SG_ 3221225472 AltCurrent 115;
BA_ "SigType" SG_ 3221225472 NetBatteryCurrent 1;
BA_ "SPN" SG_ 3221225472 NetBatteryCurrent 114;
BA_ "SigType" SG_ 3221225472 TotalNumberOfPacketsEoMA 1;
BA_ "SPN" SG_ 3221225472 TotalNumberOfPacketsEoMA 2558;
BA_ "SigType" SG_ 3221225472 TotalMessageSizeEoMA 1;
BA_ "SPN" SG_ 3221225472 TotalMessageSizeEoMA 2557;
BA_ "SigType" SG_ 3221225472 TotalMessageSizeBAM 1;
BA_ "SPN" SG_ 3221225472 TotalMessageSizeBAM 2557;
BA_ "SigType" SG_ 3221225472 TotalNumberOfPacketsBAM 1;
BA_ "SPN" SG_ 3221225472 TotalNumberOfPacketsBAM 2558;
BA_ "SigType" SG_ 3221225472 ConnectionAbortReason 1;
BA_ "SPN" SG_ 3221225472 ConnectionAbortReason 2570;
BA_ "SigType" SG_ 3221225472 NextPacketNumberToBeSent 1;
BA_ "SPN" SG_ 3221225472 NextPacketNumberToBeSent 2562;
BA_ "SigType" SG_ 3221225472 NumberOfPacketsThatCanBeSent 1;
BA_ "SPN" SG_ 3221225472 NumberOfPacketsThatCanBeSent 2561;
BA_ "SPN" SG_ 3221225472 PGNumber 2560;
BA_ "SigType" SG_ 3221225472 MaximumNumberOfPackets 1;
BA_ "SPN" SG_ 3221225472 MaximumNumberOfPackets 2559;
BA_ "SigType" SG_ 3221225472 TotalNumberOfPackets 1;
BA_ "SPN" SG_ 3221225472 TotalNumberOfPackets 2558;
BA_ "SigType" SG_ 3221225472 TotalMessageSize 1;
BA_ "SPN" SG_ 3221225472 TotalMessageSize 2557;
BA_ "SPN" SG_ 3221225472 ControlByte 2556;
BA_ "SigType" SG_ 3221225472 SequenceNumber 1;
BA_ "SPN" SG_ 3221225472 SequenceNumber 2572;
BA_ "SigType" SG_ 3221225472 DTC5 7;
BA_ "SigType" SG_ 3221225472 DTC4 7;
BA_ "SigType" SG_ 3221225472 DTC3 7;
BA_ "SigType" SG_ 3221225472 DTC2 7;
BA_ "SigType" SG_ 3221225472 DTC1 7;
BA_ "SPN" SG_ 3221225472 CalibrationID4 1635;
BA_ "SPN" SG_ 3221225472 CalibrationID3 1635;
BA_ "SPN" SG_ 3221225472 CalibrationID2 1635;
BA_ "SPN" SG_ 3221225472 CalibrationID1 1635;
BA_ "SigType" SG_ 3221225472 CalibrationVerificationNumber 1;
BA_ "SPN" SG_ 3221225472 CalibrationVerificationNumber 1634;
BA_ "SPN" SG_ 3221225472 SPNSupported1High 3146;
BA_ "SPN" SG_ 3221225472 SPNSupported3High 3146;
BA_ "SPN" SG_ 3221225472 SPNSupported2High 3146;
BA_ "SPN" SG_ 3221225472 SPNSupported3 3146;
BA_ "SPN" SG_ 3221225472 SPNSupported2 3146;
BA_ "SPN" SG_ 3221225472 SPNDataLength3 3148;
BA_ "SPN" SG_ 3221225472 SPNDataLength2 3148;
BA_ "SPN" SG_ 3221225472 SPNDataLength1 3148;
BA_ "SPN" SG_ 3221225472 SPNSupported1 3146;
BA_ "SPN" SG_ 3221225472 ExpandedFreezeFrameLength 3149;
BA_ "SPN" SG_ 3221225472 FreezeFrameLength 1217;
BA_ "SigType" SG_ 3221225472 EngineCoolantTemperature 1;
BA_ "SPN" SG_ 3221225472 EngineCoolantTemperature 110;
BA_ "SPN" SG_ 3221225472 MisfireMonitoringSupport 1221;
BA_ "SigType" SG_ 3221225472 OBDCompliance 1;
BA_ "SPN" SG_ 3221225472 OBDCompliance 1220;
BA_ "SigType" SG_ 3221225472 PreviouslyActiveTroubleCodes 1;
BA_ "SPN" SG_ 3221225472 PreviouslyActiveTroubleCodes 1219;
BA_ "SigType" SG_ 3221225472 ActiveTroubleCodes 1;
BA_ "SPN" SG_ 3221225472 ActiveTroubleCodes 1218;
BA_ "SPN" SG_ 3221225472 SecondAirSystemMonStatus 1223;
BA_ "SPN" SG_ 3221225472 EvaporativeSystemMonStatus 1223;
BA_ "SPN" SG_ 3221225472 ACSystemRefrigerantMonStatus 1223;
BA_ "SPN" SG_ 3221225472 OxygenSensorHeaterMonStatus 1223;
BA_ "SPN" SG_ 3221225472 OxygenSensorMonStatus 1223;
BA_ "SPN" SG_ 3221225472 EGRSystemMonitoringStatus 1223;
BA_ "SPN" SG_ 3221225472 CatalystMonStatus 1223;
BA_ "SPN" SG_ 3221225472 ColdStartAidSystemMonStatus 1223;
BA_ "SPN" SG_ 3221225472 HeatedCatalystMonStatus 1223;
BA_ "SPN" SG_ 3221225472 CatalystMonSupp 1222;
BA_ "SPN" SG_ 3221225472 ColdStartAidSystemMonSupp 1222;
BA_ "SPN" SG_ 3221225472 HeatedCatalystMonSupp 1222;
BA_ "SPN" SG_ 3221225472 EvaporativeSystemMonSupp 1222;
BA_ "SPN" SG_ 3221225472 SecondAirSystemMonSupp 1222;
BA_ "SPN" SG_ 3221225472 ACSystemRefrigerantMonSupp 1222;
BA_ "SPN" SG_ 3221225472 OxygenSensorMonSupp 1222;
BA_ "SPN" SG_ 3221225472 OxygenSensorHeaterMonSupp 1222;
BA_ "SPN" SG_ 3221225472 EGRSystemMonitoringSupp 1222;
BA_ "SPN" SG_ 3221225472 MisfireMonitoringStatus 1221;
BA_ "SPN" SG_ 3221225472 ComprehensiveCompMonStatus 1221;
BA_ "SPN" SG_ 3221225472 FuelSystemMonitoringStatus 1221;
BA_ "SPN" SG_ 3221225472 ComprehensiveComponentMonSupp 1221;
BA_ "SPN" SG_ 3221225472 FuelSystemMonitoringSupport 1221;
BA_ "SigType" SG_ 3221225472 ShrtNameOfActualReportingDevice 4;
BA_ "SPN" SG_ 3221225472 ShrtNameOfActualReportingDevice 2554;
BA_ "SigType" SG_ 3221225472 LengthOfDataForTheReportedPGN 1;
BA_ "SPN" SG_ 3221225472 LengthOfDataForTheReportedPGN 2553;
BA_ "SigType" SG_ 3221225472 PGNofRequstedInformation 1;
BA_ "SPN" SG_ 3221225472 PGNofRequstedInformation 2552;
BA_ "SAEDocument" SG_ 2566838526 AddressAssignment "J1939-81";
BA_ "SPN" SG_ 2566838526 AddressAssignment 2847;
BA_ "SigType" SG_ 2566838526 AddressAssignment 1;
BA_ "SAEDocument" SG_ 2566838526 ArbitraryAddressCapable "J1939-81";
BA_ "SPN" SG_ 2566838526 ArbitraryAddressCapable 2844;
BA_ "SAEDocument" SG_ 2566838526 IndustryGroup "NMEA2000";
BA_ "SPN" SG_ 2566838526 IndustryGroup 2846;
BA_ "SAEDocument" SG_ 2566838526 VehicleSystemInstance "J1939-81";
BA_ "SPN" SG_ 2566838526 VehicleSystemInstance 2843;
BA_ "SAEDocument" SG_ 2566838526 Function "J1939-81";
BA_ "SPN" SG_ 2566838526 Function 2841;
BA_ "SAEDocument" SG_ 2566838526 VehicleSystem "J1939-81";
BA_ "SAEDocument" SG_ 2566838526 FunctionInstance "J1939-81";
BA_ "SPN" SG_ 2566838526 FunctionInstance 2839;
BA_ "SAEDocument" SG_ 2566838526 ECUInstance "J1939-81";
BA_ "SPN" SG_ 2566838526 ECUInstance 2840;
BA_ "SAEDocument" SG_ 2566838526 ManufacturerCode "NMEA2000";
BA_ "SPN" SG_ 2566838526 ManufacturerCode 2838;
BA_ "SigType" SG_ 2566838526 ManufacturerCode 1;
BA_ "SAEDocument" SG_ 2566838526 IdentityNumber "J1939-81";
BA_ "SPN" SG_ 2566838526 IdentityNumber 2837;
BA_ "SAEDocument" SG_ 2566838526 VehicleSystem5 "J1939-81";
BA_ "SAEDocument" SG_ 2566838526 VehicleSystem4 "J1939-81";
BA_ "SAEDocument" SG_ 2566838526 VehicleSystem3 "J1939-81";
BA_ "SAEDocument" SG_ 2566838526 VehicleSystem2 "J1939-81";
BA_ "SAEDocument" SG_ 2566838526 VehicleSystem1 "J1939-81";
BA_ "SigType" SG_ 2565799424 IndustryGroup 4;
BA_ "SigType" SG_ 2565799424 ManufacturerCode 1;
BA_ "SigType" SG_ 2565406208 ParameterGroupNumber 1;
BA_ "SPN" SG_ 2565406208 ParameterGroupNumber 2574;
BA_ "SigType" SG_ 2565406208 GroupFunctionValue 1;
BA_ "SPN" SG_ 2565406208 GroupFunctionValue 2542;
BA_ "SPN" SG_ 2565406208 ControlByte 2556;
BA_ "SigType" SG_ 2565406259 ParameterGroupNumber 1;
BA_ "SPN" SG_ 2565406259 ParameterGroupNumber 2574;
BA_ "SigType" SG_ 2565406259 GroupFunctionValue 1;
BA_ "SPN" SG_ 2565406259 GroupFunctionValue 2542;
BA_ "SPN" SG_ 2565406259 ControlByte 2556;
BA_ "SigType" SG_ 2565799475 IndustryGroup 4;
BA_ "SigType" SG_ 2565799475 ManufacturerCode 1;
BA_ "SigType" SG_ 2565485323 ParameterGroupNumber 1;
BA_ "SPN" SG_ 2565485323 ParameterGroupNumber 2574;
BA_ "SigType" SG_ 2566834699 DTC5 7;
BA_ "SigType" SG_ 2566834699 DTC4 7;
BA_ "SigType" SG_ 2566834699 DTC3 7;
BA_ "SigType" SG_ 2566834699 DTC2 7;
BA_ "SigType" SG_ 2566834699 DTC1 7;
BA_ "SPN" SG_ 2566834699 FlashRedStopLamp 3039;
BA_ "SPN" SG_ 2566834699 FlashProtectLamp 3041;
BA_ "SigType" SG_ 2566834699 FlashMalfuncIndicatorLamp 4;
BA_ "SPN" SG_ 2566834699 FlashMalfuncIndicatorLamp 3038;
BA_ "SPN" SG_ 2566834699 FlashAmberWarningLamp 3040;
BA_ "SigType" SG_ 2566834699 MalfunctionIndicatorLampStatus 4;
BA_ "SPN" SG_ 2566834699 MalfunctionIndicatorLampStatus 1213;
BA_ "SigType" SG_ 2566834699 AmberWarningLampStatus 4;
BA_ "SPN" SG_ 2566834699 AmberWarningLampStatus 624;
BA_ "SigType" SG_ 2566834699 RedStopLampState 4;
BA_ "SPN" SG_ 2566834699 RedStopLampState 623;
BA_ "SigType" SG_ 2566834699 ProtectLampStatus 4;
BA_ "SPN" SG_ 2566834699 ProtectLampStatus 987;
BA_ "SigType" SG_ 2566834955 DTC5 7;
BA_ "SigType" SG_ 2566834955 DTC4 7;
BA_ "SigType" SG_ 2566834955 DTC3 7;
BA_ "SigType" SG_ 2566834955 DTC2 7;
BA_ "SigType" SG_ 2566834955 DTC1 7;
BA_ "SigType" SG_ 2566834955 MalfunctionIndicatorLampStatus 4;
BA_ "SPN" SG_ 2566834955 MalfunctionIndicatorLampStatus 1213;
BA_ "SigType" SG_ 2566834955 RedStopLampState 4;
BA_ "SPN" SG_ 2566834955 RedStopLampState 623;
BA_ "SigType" SG_ 2566834955 AmberWarningLampStatus 4;
BA_ "SPN" SG_ 2566834955 AmberWarningLampStatus 624;
BA_ "SigType" SG_ 2566834955 ProtectLampStatus 4;
BA_ "SPN" SG_ 2566834955 ProtectLampStatus 987;
BA_ "SPN" SG_ 2566834955 FlashRedStopLamp 3039;
BA_ "SPN" SG_ 2566834955 FlashProtectLamp 3041;
BA_ "SigType" SG_ 2566834955 FlashMalfuncIndicatorLamp 4;
BA_ "SPN" SG_ 2566834955 FlashMalfuncIndicatorLamp 3038;
BA_ "SPN" SG_ 2566834955 FlashAmberWarningLamp 3040;
BA_ "SPN" SG_ 2566764043 SPNSupported1High 3146;
BA_ "SPN" SG_ 2566764043 SPNSupported3High 3146;
BA_ "SPN" SG_ 2566764043 SPNSupported2High 3146;
BA_ "SPN" SG_ 2566764043 SPNSupported3 3146;
BA_ "SPN" SG_ 2566764043 SPNSupported2 3146;
BA_ "SPN" SG_ 2566764043 SPNDataLength3 3148;
BA_ "SPN" SG_ 2566764043 SPNDataLength2 3148;
BA_ "SPN" SG_ 2566764043 SPNDataLength1 3148;
BA_ "SPN" SG_ 2566764043 SPNSupported1 3146;
BA_ "SigType" SG_ 2566764299 DTC1 7;
BA_ "SPN" SG_ 2566764299 ExpandedFreezeFrameLength 3149;
BA_ "SigType" SG_ 2566835467 DTC1 7;
BA_ "SPN" SG_ 2566835467 FreezeFrameLength 1217;
BA_ "SigType" SG_ 2566835467 EngSpeed 1;
BA_ "SPN" SG_ 2566835467 EngSpeed 190;
BA_ "SigType" SG_ 2566835467 EngTorqueMode 4;
BA_ "SPN" SG_ 2566835467 EngTorqueMode 899;
BA_ "SigType" SG_ 2566835467 EngTurboBoostPress 1;
BA_ "SPN" SG_ 2566835467 EngTurboBoostPress 102;
BA_ "SigType" SG_ 2566835467 WheelBasedVehicleSpeed 1;
BA_ "SPN" SG_ 2566835467 WheelBasedVehicleSpeed 84;
BA_ "SigType" SG_ 2566835467 EngPercentLoadAtCurrentSpeed 1;
BA_ "SPN" SG_ 2566835467 EngPercentLoadAtCurrentSpeed 92;
BA_ "SigType" SG_ 2566835467 EngineCoolantTemperature 1;
BA_ "SPN" SG_ 2566835467 EngineCoolantTemperature 110;
BA_ "SigType" SG_ 2565799435 IndustryGroup 4;
BA_ "SigType" SG_ 2565799435 ManufacturerCode 1;
BA_ "SigType" SG_ 2565602827 SequenceNumber 1;
BA_ "SPN" SG_ 2565602827 SequenceNumber 2572;
BA_ "SigType" SG_ 2565668363 TotalNumberOfPacketsEoMA 1;
BA_ "SPN" SG_ 2565668363 TotalNumberOfPacketsEoMA 2558;
BA_ "SigType" SG_ 2565668363 TotalMessageSizeEoMA 1;
BA_ "SPN" SG_ 2565668363 TotalMessageSizeEoMA 2557;
BA_ "SigType" SG_ 2565668363 TotalMessageSizeBAM 1;
BA_ "SPN" SG_ 2565668363 TotalMessageSizeBAM 2557;
BA_ "SigType" SG_ 2565668363 TotalNumberOfPacketsBAM 1;
BA_ "SPN" SG_ 2565668363 TotalNumberOfPacketsBAM 2558;
BA_ "SigType" SG_ 2565668363 ConnectionAbortReason 1;
BA_ "SPN" SG_ 2565668363 ConnectionAbortReason 2570;
BA_ "SigType" SG_ 2565668363 NextPacketNumberToBeSent 1;
BA_ "SPN" SG_ 2565668363 NextPacketNumberToBeSent 2562;
BA_ "SigType" SG_ 2565668363 NumberOfPacketsThatCanBeSent 1;
BA_ "SPN" SG_ 2565668363 NumberOfPacketsThatCanBeSent 2561;
BA_ "SPN" SG_ 2565668363 PGNumber 2560;
BA_ "SigType" SG_ 2565668363 MaximumNumberOfPackets 1;
BA_ "SPN" SG_ 2565668363 MaximumNumberOfPackets 2559;
BA_ "SigType" SG_ 2565668363 TotalNumberOfPackets 1;
BA_ "SPN" SG_ 2565668363 TotalNumberOfPackets 2558;
BA_ "SigType" SG_ 2565668363 TotalMessageSize 1;
BA_ "SPN" SG_ 2565668363 TotalMessageSize 2557;
BA_ "SPN" SG_ 2565668363 ControlByte 2556;
BA_ "SigType" SG_ 2565406219 ParameterGroupNumber 1;
BA_ "SPN" SG_ 2565406219 ParameterGroupNumber 2574;
BA_ "SigType" SG_ 2565406219 GroupFunctionValue 1;
BA_ "SPN" SG_ 2565406219 GroupFunctionValue 2542;
BA_ "SPN" SG_ 2565406219 ControlByte 2556;
BA_ "SPN" SG_ 2562981630 IndividualDTCClearControlByte 3034;
BA_ "SPN" SG_ 2562981630 CtrlByteIndicIndividualDTCClear 3035;
BA_ "SPN" SG_ 2562981630 SPN1 1214;
BA_ "SPN" SG_ 2562981630 SPN1High 1214;
BA_ "SPN" SG_ 2562981630 FailureModeIdentifier1 1215;
BA_ "SigType" SG_ 2566836222 DTC5 7;
BA_ "SigType" SG_ 2566836222 DTC4 7;
BA_ "SigType" SG_ 2566836222 DTC3 7;
BA_ "SigType" SG_ 2566836222 DTC2 7;
BA_ "SigType" SG_ 2566836222 DTC1 7;
BA_ "SPN" SG_ 2566836222 FlashRedStopLamp 3039;
BA_ "SPN" SG_ 2566836222 FlashProtectLamp 3041;
BA_ "SigType" SG_ 2566836222 FlashMalfuncIndicatorLamp 4;
BA_ "SPN" SG_ 2566836222 FlashMalfuncIndicatorLamp 3038;
BA_ "SigType" SG_ 2566836222 MalfunctionIndicatorLampStatus 4;
BA_ "SPN" SG_ 2566836222 MalfunctionIndicatorLampStatus 1213;
BA_ "SigType" SG_ 2566836222 RedStopLampState 4;
BA_ "SPN" SG_ 2566836222 RedStopLampState 623;
BA_ "SigType" SG_ 2566836222 AmberWarningLampStatus 4;
BA_ "SPN" SG_ 2566836222 AmberWarningLampStatus 624;
BA_ "SigType" SG_ 2566836222 ProtectLampStatus 4;
BA_ "SPN" SG_ 2566836222 ProtectLampStatus 987;
BA_ "SPN" SG_ 2566835966 MisfireMonitoringSupport 1221;
BA_ "SigType" SG_ 2566835966 OBDCompliance 1;
BA_ "SPN" SG_ 2566835966 OBDCompliance 1220;
BA_ "SigType" SG_ 2566835966 PreviouslyActiveTroubleCodes 1;
BA_ "SPN" SG_ 2566835966 PreviouslyActiveTroubleCodes 1219;
BA_ "SigType" SG_ 2566835966 ActiveTroubleCodes 1;
BA_ "SPN" SG_ 2566835966 ActiveTroubleCodes 1218;
BA_ "SPN" SG_ 2566835966 SecondAirSystemMonStatus 1223;
BA_ "SPN" SG_ 2566835966 EvaporativeSystemMonStatus 1223;
BA_ "SPN" SG_ 2566835966 ACSystemRefrigerantMonStatus 1223;
BA_ "SPN" SG_ 2566835966 OxygenSensorHeaterMonStatus 1223;
BA_ "SPN" SG_ 2566835966 OxygenSensorMonStatus 1223;
BA_ "SPN" SG_ 2566835966 EGRSystemMonitoringStatus 1223;
BA_ "SPN" SG_ 2566835966 CatalystMonStatus 1223;
BA_ "SPN" SG_ 2566835966 ColdStartAidSystemMonStatus 1223;
BA_ "SPN" SG_ 2566835966 HeatedCatalystMonStatus 1223;
BA_ "SPN" SG_ 2566835966 CatalystMonSupp 1222;
BA_ "SPN" SG_ 2566835966 ColdStartAidSystemMonSupp 1222;
BA_ "SPN" SG_ 2566835966 HeatedCatalystMonSupp 1222;
BA_ "SPN" SG_ 2566835966 EvaporativeSystemMonSupp 1222;
BA_ "SPN" SG_ 2566835966 SecondAirSystemMonSupp 1222;
BA_ "SPN" SG_ 2566835966 ACSystemRefrigerantMonSupp 1222;
BA_ "SPN" SG_ 2566835966 OxygenSensorMonSupp 1222;
BA_ "SPN" SG_ 2566835966 OxygenSensorHeaterMonSupp 1222;
BA_ "SPN" SG_ 2566835966 EGRSystemMonitoringSupp 1222;
BA_ "SPN" SG_ 2566835966 MisfireMonitoringStatus 1221;
BA_ "SPN" SG_ 2566835966 ComprehensiveCompMonStatus 1221;
BA_ "SPN" SG_ 2566835966 FuelSystemMonitoringStatus 1221;
BA_ "SPN" SG_ 2566835966 ComprehensiveComponentMonSupp 1221;
BA_ "SPN" SG_ 2566835966 FuelSystemMonitoringSupport 1221;
BA_ "SigType" SG_ 2566835710 DTC1 7;
BA_ "SPN" SG_ 2566835710 FreezeFrameLength 1217;
BA_ "SigType" SG_ 2566835710 EngSpeed 1;
BA_ "SPN" SG_ 2566835710 EngSpeed 190;
BA_ "SigType" SG_ 2566835710 EngTorqueMode 4;
BA_ "SPN" SG_ 2566835710 EngTorqueMode 899;
BA_ "SigType" SG_ 2566835710 EngTurboBoostPress 1;
BA_ "SPN" SG_ 2566835710 EngTurboBoostPress 102;
BA_ "SigType" SG_ 2566835710 WheelBasedVehicleSpeed 1;
BA_ "SPN" SG_ 2566835710 WheelBasedVehicleSpeed 84;
BA_ "SigType" SG_ 2566835710 EngPercentLoadAtCurrentSpeed 1;
BA_ "SPN" SG_ 2566835710 EngPercentLoadAtCurrentSpeed 92;
BA_ "SigType" SG_ 2566835710 EngineCoolantTemperature 1;
BA_ "SPN" SG_ 2566835710 EngineCoolantTemperature 110;
BA_ "SigType" SG_ 2566764542 DTC1 7;
BA_ "SPN" SG_ 2566764542 ExpandedFreezeFrameLength 3149;
BA_ "SPN" SG_ 2566764286 SPNSupported1High 3146;
BA_ "SPN" SG_ 2566764286 SPNSupported3High 3146;
BA_ "SPN" SG_ 2566764286 SPNSupported2High 3146;
BA_ "SPN" SG_ 2566764286 SPNSupported3 3146;
BA_ "SPN" SG_ 2566764286 SPNSupported2 3146;
BA_ "SPN" SG_ 2566764286 SPNDataLength3 3148;
BA_ "SPN" SG_ 2566764286 SPNDataLength2 3148;
BA_ "SPN" SG_ 2566764286 SPNDataLength1 3148;
BA_ "SPN" SG_ 2566764286 SPNSupported1 3146;
BA_ "SigType" SG_ 2566835198 DTC5 7;
BA_ "SigType" SG_ 2566835198 DTC4 7;
BA_ "SigType" SG_ 2566835198 DTC3 7;
BA_ "SigType" SG_ 2566835198 DTC2 7;
BA_ "SigType" SG_ 2566835198 DTC1 7;
BA_ "SigType" SG_ 2566835198 MalfunctionIndicatorLampStatus 4;
BA_ "SPN" SG_ 2566835198 MalfunctionIndicatorLampStatus 1213;
BA_ "SigType" SG_ 2566835198 RedStopLampState 4;
BA_ "SPN" SG_ 2566835198 RedStopLampState 623;
BA_ "SigType" SG_ 2566835198 AmberWarningLampStatus 4;
BA_ "SPN" SG_ 2566835198 AmberWarningLampStatus 624;
BA_ "SigType" SG_ 2566835198 ProtectLampStatus 4;
BA_ "SPN" SG_ 2566835198 ProtectLampStatus 987;
BA_ "SPN" SG_ 2566835198 FlashRedStopLamp 3039;
BA_ "SPN" SG_ 2566835198 FlashProtectLamp 3041;
BA_ "SigType" SG_ 2566835198 FlashMalfuncIndicatorLamp 4;
BA_ "SPN" SG_ 2566835198 FlashMalfuncIndicatorLamp 3038;
BA_ "SPN" SG_ 2566835198 FlashAmberWarningLamp 3040;
BA_ "SPN" SG_ 2564030206 CalibrationID4 1635;
BA_ "SPN" SG_ 2564030206 CalibrationID3 1635;
BA_ "SPN" SG_ 2564030206 CalibrationID2 1635;
BA_ "SPN" SG_ 2564030206 CalibrationID1 1635;
BA_ "SigType" SG_ 2564030206 CalibrationVerificationNumber 1;
BA_ "SPN" SG_ 2564030206 CalibrationVerificationNumber 1634;
BA_ "SigType" SG_ 2566837502 DTC5 7;
BA_ "SigType" SG_ 2566837502 DTC4 7;
BA_ "SigType" SG_ 2566837502 DTC3 7;
BA_ "SigType" SG_ 2566837502 DTC2 7;
BA_ "SPN" SG_ 2566837502 FlashRedStopLamp 3039;
BA_ "SPN" SG_ 2566837502 FlashProtectLamp 3041;
BA_ "SigType" SG_ 2566837502 MalfunctionIndicatorLampStatus 4;
BA_ "SPN" SG_ 2566837502 MalfunctionIndicatorLampStatus 1213;
BA_ "SigType" SG_ 2566837502 RedStopLampState 4;
BA_ "SPN" SG_ 2566837502 RedStopLampState 623;
BA_ "SigType" SG_ 2566837502 AmberWarningLampStatus 4;
BA_ "SPN" SG_ 2566837502 AmberWarningLampStatus 624;
BA_ "SigType" SG_ 2566837502 ProtectLampStatus 4;
BA_ "SPN" SG_ 2566837502 ProtectLampStatus 987;
BA_ "SigType" SG_ 2566837502 FlashMalfuncIndicatorLamp 4;
BA_ "SPN" SG_ 2566837502 FlashMalfuncIndicatorLamp 3038;
BA_ "SPN" SG_ 2566837502 FlashAmberWarningLamp 3040;
BA_ "SPN" SG_ 2566837502 SPN1 1214;
BA_ "SigType" SG_ 2566834942 DTC5 7;
BA_ "SigType" SG_ 2566834942 DTC4 7;
BA_ "SigType" SG_ 2566834942 DTC3 7;
BA_ "SigType" SG_ 2566834942 DTC2 7;
BA_ "SigType" SG_ 2566834942 DTC1 7;
BA_ "SPN" SG_ 2566834942 FlashRedStopLamp 3039;
BA_ "SPN" SG_ 2566834942 FlashProtectLamp 3041;
BA_ "SigType" SG_ 2566834942 FlashMalfuncIndicatorLamp 4;
BA_ "SPN" SG_ 2566834942 FlashMalfuncIndicatorLamp 3038;
BA_ "SPN" SG_ 2566834942 FlashAmberWarningLamp 3040;
BA_ "SigType" SG_ 2566834942 MalfunctionIndicatorLampStatus 4;
BA_ "SPN" SG_ 2566834942 MalfunctionIndicatorLampStatus 1213;
BA_ "SigType" SG_ 2566834942 AmberWarningLampStatus 4;
BA_ "SPN" SG_ 2566834942 AmberWarningLampStatus 624;
BA_ "SigType" SG_ 2566834942 RedStopLampState 4;
BA_ "SPN" SG_ 2566834942 RedStopLampState 623;
BA_ "SigType" SG_ 2566834942 ProtectLampStatus 4;
BA_ "SPN" SG_ 2566834942 ProtectLampStatus 987;
BA_ "SAEDocument" SG_ 2565799678 VehicleSystem5 "J1939-81";
BA_ "SAEDocument" SG_ 2565799678 VehicleSystem4 "J1939-81";
BA_ "SAEDocument" SG_ 2565799678 VehicleSystem3 "J1939-81";
BA_ "SAEDocument" SG_ 2565799678 VehicleSystem2 "J1939-81";
BA_ "SAEDocument" SG_ 2565799678 VehicleSystem1 "J1939-81";
BA_ "SAEDocument" SG_ 2565799678 ArbitraryAddressCapable "J1939-81";
BA_ "SPN" SG_ 2565799678 ArbitraryAddressCapable 2844;
BA_ "SAEDocument" SG_ 2565799678 IndustryGroup "NMEA2000";
BA_ "SPN" SG_ 2565799678 IndustryGroup 2846;
BA_ "SAEDocument" SG_ 2565799678 VehicleSystemInstance "J1939-81";
BA_ "SPN" SG_ 2565799678 VehicleSystemInstance 2843;
BA_ "SAEDocument" SG_ 2565799678 VehicleSystem "J1939-81";
BA_ "SAEDocument" SG_ 2565799678 Function "J1939-81";
BA_ "SPN" SG_ 2565799678 Function 2841;
BA_ "SAEDocument" SG_ 2565799678 FunctionInstance "J1939-81";
BA_ "SPN" SG_ 2565799678 FunctionInstance 2839;
BA_ "SAEDocument" SG_ 2565799678 ECUInstance "J1939-81";
BA_ "SPN" SG_ 2565799678 ECUInstance 2840;
BA_ "SAEDocument" SG_ 2565799678 ManufacturerCode "NMEA2000";
BA_ "SPN" SG_ 2565799678 ManufacturerCode 2838;
BA_ "SigType" SG_ 2565799678 ManufacturerCode 1;
BA_ "SAEDocument" SG_ 2565799678 IdentityNumber "J1939-81";
BA_ "SPN" SG_ 2565799678 IdentityNumber 2837;
BA_ "SigType" SG_ 2563440382 ShrtNameOfActualReportingDevice 4;
BA_ "SPN" SG_ 2563440382 ShrtNameOfActualReportingDevice 2554;
BA_ "SigType" SG_ 2563440382 LengthOfDataForTheReportedPGN 1;
BA_ "SPN" SG_ 2563440382 LengthOfDataForTheReportedPGN 2553;
BA_ "SigType" SG_ 2563440382 PGNofRequstedInformation 1;
BA_ "SPN" SG_ 2563440382 PGNofRequstedInformation 2552;
BA_ "SigType" SG_ 2565603070 SequenceNumber 1;
BA_ "SPN" SG_ 2565603070 SequenceNumber 2572;
BA_ "SigType" SG_ 2565668606 TotalNumberOfPacketsEoMA 1;
BA_ "SPN" SG_ 2565668606 TotalNumberOfPacketsEoMA 2558;
BA_ "SigType" SG_ 2565668606 TotalMessageSizeEoMA 1;
BA_ "SPN" SG_ 2565668606 TotalMessageSizeEoMA 2557;
BA_ "SigType" SG_ 2565668606 TotalMessageSizeBAM 1;
BA_ "SPN" SG_ 2565668606 TotalMessageSizeBAM 2557;
BA_ "SigType" SG_ 2565668606 TotalNumberOfPacketsBAM 1;
BA_ "SPN" SG_ 2565668606 TotalNumberOfPacketsBAM 2558;
BA_ "SigType" SG_ 2565668606 ConnectionAbortReason 1;
BA_ "SPN" SG_ 2565668606 ConnectionAbortReason 2570;
BA_ "SigType" SG_ 2565668606 NextPacketNumberToBeSent 1;
BA_ "SPN" SG_ 2565668606 NextPacketNumberToBeSent 2562;
BA_ "SigType" SG_ 2565668606 NumberOfPacketsThatCanBeSent 1;
BA_ "SPN" SG_ 2565668606 NumberOfPacketsThatCanBeSent 2561;
BA_ "SPN" SG_ 2565668606 PGNumber 2560;
BA_ "SigType" SG_ 2565668606 MaximumNumberOfPackets 1;
BA_ "SPN" SG_ 2565668606 MaximumNumberOfPackets 2559;
BA_ "SigType" SG_ 2565668606 TotalNumberOfPackets 1;
BA_ "SPN" SG_ 2565668606 TotalNumberOfPackets 2558;
BA_ "SigType" SG_ 2565668606 TotalMessageSize 1;
BA_ "SPN" SG_ 2565668606 TotalMessageSize 2557;
BA_ "SPN" SG_ 2565668606 ControlByte 2556;
BA_ "SigType" SG_ 2565537534 ParameterGroupNumber 1;
BA_ "SPN" SG_ 2565537534 ParameterGroupNumber 2574;
BA_ "SigType" SG_ 2565406462 ParameterGroupNumber 1;
BA_ "SPN" SG_ 2565406462 ParameterGroupNumber 2574;
BA_ "SigType" SG_ 2565406462 GroupFunctionValue 1;
BA_ "SPN" SG_ 2565406462 GroupFunctionValue 2542;
BA_ "SPN" SG_ 2565406462 ControlByte 2556;
VAL_ 3221225472 SspensionCtrlRefusalInformation 7 "1101NotDefined" 15 "NotAvailable" 14 "Error" 6 "GnrlRjctINSpcifiedReasonApplies" 5 "BelowSpeedLimit" 4 "AboveSpeedLimit" 3 "BogieDiffNotLocked" 2 "WouldExceedAxleLoadLimit" 1 "AxleLoadLimitReached" 0 "ActualRqNotRefused" ;
VAL_ 3221225472 SuspensionRemoteCtrl2 3 "NotAvailable" 2 "Error" 1 "Active" 0 "NotActive" ;
VAL_ 3221225472 SuspensionRemoteCtrl1 3 "NotAvailable" 2 "Error" 1 "Active" 0 "NotActive" ;
VAL_ 3221225472 RearAxleInBumperRange 3 "NotAvailable" 2 "Error" 1 "ActualLevelWithinBumperRange" 0 "ActualLevelOutOfBumperRange" ;
VAL_ 3221225472 FrontAxleInBumperRange 3 "NotAvailable" 2 "Error" 1 "ActualLevelWithinBumperRange" 0 "ActualLevelOutOfBumperRange" ;
VAL_ 3221225472 DoorRelease 3 "NotAvailable" 2 "Error" 1 "DoorsMayBeOpened" 0 "DoorsMayNotBeOpened" ;
VAL_ 3221225472 VehicleMotionInhibit 3 "NotAvailable" 2 "Error" 1 "VehicleMotionIsInhibited" 0 "VehicleMayBeMoved" ;
VAL_ 3221225472 SecurityDevice 3 "NotAvailable" 2 "Error" 1 "Active" 0 "NotActive" ;
VAL_ 3221225472 LevelCtrlMode 10 "1101NotDefined" 15 "NotAvailable" 14 "Error" 9 "AirSuspensionCtrlProhibited" 8 "ExhstngBllwFnctnIBllwsArExhstdT" 7 "TractionHelpLoadReduce" 6 "OptmmTrctn2IPrssAtThDrvnAxlIsCt" 5 "OptmmTrctn1IPrssAtThDrvnAxlIsCt" 4 "PrssRt2IRtBtwnThPrssrsAtThDrvnA" 3 "PrssRt1IRtBtwnThPrssrsAtThDrvnA" 2 "LdFxngIDrvnAxlnIsLddTAVlDfndByT" 1 "TrctnHlpIDrvnAxlIsLddTAMxVlGvnB" 0 "NrmlOprtnISystmPrfrmsAPrCtrlOfT" ;
VAL_ 3221225472 KneelingInformation 15 "NotAvailable" 14 "Error" 5 "1101NotDefined" 4 "KneelingAborted" 3 "LiftingActive" 2 "KneelingLevelReached" 0 "NotActive" ;
VAL_ 3221225472 LiftingCtrlModeRearAxle 3 "NotAvailable" 2 "Error" 1 "LiftingActive" 0 "LiftingNotActive" ;
VAL_ 3221225472 LiftingCtrlModeFrontAxle 3 "NotAvailable" 2 "Error" 1 "LiftingActive" 0 "LiftingNotActive" ;
VAL_ 3221225472 LoweringCtrlModeRearAxle 3 "NotAvailable" 2 "Error" 1 "LoweringActive" 0 "LoweringNotActive" ;
VAL_ 3221225472 LoweringCtrlModeFrontAxle 3 "NotAvailable" 2 "Error" 1 "LoweringActive" 0 "LoweringNotActive" ;
VAL_ 3221225472 AboveNominalLevelRearAxle 3 "NotAvailable" 2 "Error" 1 "Above" 0 "NotAbove" ;
VAL_ 3221225472 AboveNominalLevelFrontAxle 3 "NotAvailable" 2 "Error" 1 "Above" 0 "NotAbove" ;
VAL_ 3221225472 BelowNominalLevelRearAxle 3 "NotAvailable" 2 "Error" 1 "Below" 0 "NotBelow" ;
VAL_ 3221225472 BelowNominalLevelFrontAxle 3 "NotAvailable" 2 "Error" 1 "Below" 0 "NotBelow" ;
VAL_ 3221225472 NominalLevelRearAxle 15 "NotAvailable" 14 "Error" 8 "1101NotDefined" 7 "LowerLevel" 6 "UpperLevel" 5 "CustomerLevel" 4 "PresetLevel" 3 "NormalLevel3" 2 "NormalLevel2" 1 "NormalLevel1" 0 "LevelNotSpecified" ;
VAL_ 3221225472 NominalLevelFrontAxle 15 "NotAvailable" 14 "Error" 8 "1101NotDefined" 7 "LowerLevel" 6 "UpperLevel" 5 "CustomerLevel" 4 "PresetLevel" 3 "NormalLevel3" 2 "NormalLevel2" 1 "NormalLevel1" 0 "LevelNotSpecified" ;
VAL_ 3221225472 LiftAxle2Pos 3 "NotAvailable" 2 "Error" 1 "LiftAxlePosUp_TagAxleUnladen" 0 "LiftAxlePosDown_TagAxleLaden" ;
VAL_ 3221225472 LiftAxle1Pos 3 "NotAvailable" 2 "Error" 1 "LiftAxlePosUp_TagAxleUnladen" 0 "LiftAxlePosDown_TagAxleLaden" ;
VAL_ 3221225472 UseTransferMode 3 "NA" 2 "Undefined" 1 "Yes" 0 "No" ;
VAL_ 3221225472 TransOilLevelMeasurementStatus 15 "NotAvailable" 14 "Error" 13 "ConditionsNotValidOther" 12 "NotDefined" 8 "CndtionsNotValidEngSpeedTooHigh" 7 "CnditionsNotValidEngSpeedTooLow" 6 "CndtionsNotValidVehicleNotLevel" 5 "CndtnsNtVldVhclMvngOtptShftSpdT" 4 "CndtnsNtVldTrnsFluidTempTooHigh" 3 "CndtnsNtVldTransFluidTempTooLow" 2 "ConditionsNotValidTransInGear" 1 "CndtnsNtVldSttlngTmrStllCntngDw" 0 "CndtnsVldFrTrnsOlLvlMeasurement" ;
VAL_ 3221225472 TransOilLevelCountdownTimer 15 "NotAvailable" 14 "Error" 13 "ThirteenMinutes" 12 "TwelveMinutes" 11 "ElevenMinutes" 10 "TenMinutes" 9 "NineMinutes" 8 "EightMinutes" 7 "SevenMinutes" 6 "SixMinutes" 5 "FiveMinutes" 4 "FourMinutes" 3 "ThreeMinutes" 2 "TwoMinutes" 1 "OneMinute" 0 "lessThan1Minute" ;
VAL_ 3221225472 PGNumber 255 "NotAvailable" ;
VAL_ 3221225472 ControlByte 24 "EAbort" 23 "EEoMACK" 22 "EDPO" 21 "ECTS" 20 "ERTS" 3 "CannotRespond" 2 "AccessDenied" 1 "NACK" 0 "ACK" 255 "Abort" 32 "BAM" 19 "EoMA" 17 "CTS" 16 "RTS" ;
VAL_ 3221225472 SPNSupportTypeSTR3 1 "NotSupportedInScaledTestResults" 0 "SupportedInScaledTestResults" ;
VAL_ 3221225472 SPNSupportTypeSTR2 1 "NotSupportedInScaledTestResults" 0 "SupportedInScaledTestResults" ;
VAL_ 3221225472 SPNSupportTypeEFF3 1 "NotSupportedInExFreezeFrame" 0 "SupportedInExFreezeFrame" ;
VAL_ 3221225472 SPNSupportTypeEFF2 1 "NotSupportedInExFreezeFrame" 0 "SupportedInExFreezeFrame" ;
VAL_ 3221225472 SPNSupportTypeDS3 1 "NotSupportedInDataStream" 0 "SupportedInDataStream" ;
VAL_ 3221225472 SPNSupportTypeDS2 1 "NotSupportedInDataStream" 0 "SupportedInDataStream" ;
VAL_ 3221225472 SPNSupportTypeSTR1 1 "NotSupportedInScaledTestResults" 0 "SupportedInScaledTestResults" ;
VAL_ 3221225472 SPNSupportTypeDS1 1 "NotSupportedInDataStream" 0 "SupportedInDataStream" ;
VAL_ 3221225472 SPNSupportTypeEFF1 1 "NotSupportedInExFreezeFrame" 0 "SupportedInExFreezeFrame" ;
VAL_ 3221225472 MisfireMonitoringSupport 3 "Not available" 2 "Reserved" 1 "test supported" 0 "test not supported" ;
VAL_ 3221225472 OBDCompliance 5 "Not intended to meet OBD II requ" 4 "OBD I" 3 "OBD and OBD II" 2 "OBD (Federal, EPA)" 1 "OBD II (California, ARB)" 0 "Reserver for assignment by SAE" ;
VAL_ 3221225472 SecondAirSystemMonStatus 1 "TestNotComplete" 0 "TestComplete" ;
VAL_ 3221225472 EvaporativeSystemMonStatus 1 "TestNotComplete" 0 "TestComplete" ;
VAL_ 3221225472 ACSystemRefrigerantMonStatus 1 "TestNotComplete" 0 "TestComplete" ;
VAL_ 3221225472 OxygenSensorHeaterMonStatus 1 "TestNotComplete" 0 "TestComplete" ;
VAL_ 3221225472 OxygenSensorMonStatus 1 "test not complete" 0 "test complete" ;
VAL_ 3221225472 EGRSystemMonitoringStatus 1 "TestNotComplete" 0 "TestComplete" ;
VAL_ 3221225472 CatalystMonStatus 0 "TestComplete" 1 "TestNotComplete" ;
VAL_ 3221225472 ColdStartAidSystemMonStatus 1 "TestNotComplete" 0 "TestComplete" ;
VAL_ 3221225472 HeatedCatalystMonStatus 1 "TestNotComplete" 0 "TestComplete" ;
VAL_ 3221225472 CatalystMonSupp 1 "TestSupported" 0 "TestNotSupported" ;
VAL_ 3221225472 ColdStartAidSystemMonSupp 1 "TestSupported" 0 "TestNotSupported" ;
VAL_ 3221225472 HeatedCatalystMonSupp 1 "TestSupported" 0 "TestNotSupported" ;
VAL_ 3221225472 EvaporativeSystemMonSupp 1 "TestSupported" 0 "TestNotSupported" ;
VAL_ 3221225472 SecondAirSystemMonSupp 1 "TestSupported" 0 "TestNotSupported" ;
VAL_ 3221225472 ACSystemRefrigerantMonSupp 1 "TestSupported" 0 "TestNotSupported" ;
VAL_ 3221225472 OxygenSensorMonSupp 1 "TestSupported" 0 "TestNotSupported" ;
VAL_ 3221225472 OxygenSensorHeaterMonSupp 1 "TestSupported" 0 "TestNotSupported" ;
VAL_ 3221225472 EGRSystemMonitoringSupp 1 "TestSupported" 0 "TestNotSupported" ;
VAL_ 3221225472 MisfireMonitoringStatus 1 "test not complete" 0 "test complete" ;
VAL_ 3221225472 ComprehensiveCompMonStatus 1 "test not complete" 0 "test complete" ;
VAL_ 3221225472 FuelSystemMonitoringStatus 1 "test not complete" 0 "test complete" ;
VAL_ 3221225472 ComprehensiveComponentMonSupp 3 "Not available" 2 "Reserved" 1 "test supported" 0 "test not supported" ;
VAL_ 3221225472 FuelSystemMonitoringSupport 1 "test supported" 0 "test not supported" ;
VAL_ 2566838526 IndustryGroup 6 "Reserved for SAE" 7 "Reserved for SAE" 5 "IndustrialProcessCtrlStationary" 4 "Marine" 3 "Construction" 2 "Agricultural and Forestry" 1 "On-Highway" 0 "Global" ;
VAL_ 2566838526 Function 127 "Reserved" 126 "Reserved" 125 "Reserved" 124 "Reserved" 123 "Reserved" 122 "Reserved" 121 "Reserved" 120 "Reserved" 119 "Reserved" 118 "Reserved" 117 "Reserved" 116 "Reserved" 115 "Reserved" 114 "Reserved" 113 "Reserved" 112 "Reserved" 111 "Reserved" 110 "Reserved" 109 "Reserved" 108 "Reserved" 107 "Reserved" 106 "Reserved" 105 "Reserved" 104 "Reserved" 103 "Reserved" 102 "Reserved" 101 "Reserved" 42 "Water Pump Control" 41 "Lighting - Operator Controls" 40 "Seat Control" 39 "Ignition Control Module" 38 "Tire Pressure Control" 37 "Cab Controller" 36 "Pneumatic - System Controller" 35 "Suspension - System Controller" 34 "Hydraulic Pump Controller" 33 "System Monitor" 32 "Headway Controller" 31 "Propulsion Battery Charger" 30 "Management Computer" 29 "Virtual Terminal (in cab)" 28 "Off Vehicle Gateway" 27 "Power TakeOff (Secondary or Front)" 26 "Body Controller" 25 "Network Interconnect ECU" 24 "Vehicle Security" 23 "Vehicle Navigation" 22 "Aerodynamic Control" 21 "Cab Climate Control" 20 "Trip Recorder" 19 "Instrument Cluster" 18 "Suspension - Drive Axle" 17 "Suspension - Steer Axle" 16 "Steering Controller" 15 "Fuel System" 14 "Cruise Control" 13 "Retarder - Driveline" 12 "Retarder - Engine" 11 "Brakes - Drive Axle" 10 "Brakes - Steer Axle" 9 "Brakes - System Controller" 8 "Axle - Drive" 7 "Axle - Steering" 6 "Power TakeOff - (Main or Rear)" 5 "Shift Control/Console" 4 "Battery Pack Monitor" 3 "Transmission" 2 "Electric Propulsion Control" 1 "Auxiliary Power Unit (APU)" 0 "Engine" 100 "Reserved" 99 "Reserved" 98 "Reserved" 97 "Reserved" 96 "Reserved" 95 "Reserved" 94 "Reserved" 93 "Reserved" 92 "Reserved" 91 "Reserved" 90 "Reserved" 89 "Reserved" 88 "Reserved" 87 "Reserved" 86 "Reserved" 85 "Reserved" 84 "Reserved" 83 "Reserved" 82 "Reserved" 81 "Reserved" 80 "Reserved" 79 "Reserved" 78 "Reserved" 77 "Reserved" 76 "Reserved" 75 "Supplemental Fan" 74 "Lubrication System" 73 "Rollover Detection Control" 72 "Coolant Valve Controller" 71 "Transfer Case Control" 70 "Auxiliary Regeneration Device" 69 "Engine Emission Aftertreatement System" 68 "Aftertreatment system gas measurement" 67 "Electrical System Controller" 66 "I/O Controller" 65 "Gas Flow Measurement" 64 "Endurance Braking" 63 "Engine Valve Controller" 62 "On-Board Diagnostic Unit" 61 "File Server/Printer" 60 "Cab Display" 59 "Starter" 58 "Fan Drive Control" 57 "Steering Column Unit" 56 "Communications Unit, Radio" 55 "Communications Unit, Satellite" 54 "Communications Unit, Cellular" 53 "Alternator/Charging System" 52 "Chassis Controller" 51 "Forward-Looking Collision Warning System" 50 "Auxiliary Heater" 49 "Clutch/Converter Control" 48 "Ramp Control" 47 "Information System Controller" 46 "Oil Sensor Unit" 45 "Vehicle Dynamic Stability Control" 44 "Exhaust Emission Control" 43 "Transmission Display" ;
VAL_ 2566838526 VehicleSystem 0 "Non-specific System" 127 "Not Available" ;
VAL_ 2566838526 ManufacturerCode 381 "B&G" 374 "Northern Lights" 373 "Electronic Design" 371 "Delphi" 370 "Heinzmann GmbH & Co. KG" 369 "Power Torque Engineering Ltd" 368 "HANSENHOF_electronic" 367 "Fliegl Agrartechnik" 366 "Viewnyx Corp." 365 "Digi-Star, LLC" 364 "OEM Controls Inc." 363 "BEI Duncan" 362 "Alois Poettinger Maschinenfabrik GmbH" 361 "InMach" 360 "HJS Fahrzeugtechnik GmbH & Co KG" 359 "Ludwig Bergmann GmbH" 358 "Victron Energy BV" 357 "Hardi International A/S" 356 "Fischer Panda Generators, Inc" 355 "Mastervolt International B.V." 354 "Junkkari OY" 353 "Hegemon Electronics, Inc." 352 "SAME DEUTZ-FAHR" 351 "Thrane & Thrane" 350 "Noris Marine Systems GmbH & Co KG" 349 "Suonentiet" 348 "Amazonen Werke H. Dreyer" 347 "Honeywell" 346 "Control Solutions" 345 "Korean Maritime University" 344 "Parvus Corporation" 343 "Baumer Group" 342 "THOMAS MAGNETE GmbH" 341 "Boning GmbH & Co" 340 "Continental AG" 339 "Competence Center ISOBUS e.V." 338 "GRAF-SYTECO" 337 "Carraro S.p.A." 336 "APE s.r.o." 335 "Evo Electric Ltd" 334 "Takata-Petri AG" 333 "Hadley Products Corporation" 332 "HWH Corporation" 331 "Horton, Inc." 330 "Kidde Aerospace and Defense" 329 "Deif A/S" 328 "Qwerty Electronik AB" 252 "Sensor-Technik Wiedemann GmbH" 251 "German Agricultural Society" 250 "Kuhn Group" 249 "Schaltbau GmbH" 233 "Yacht Monitoring Solutions Inc." 232 "TSD Integrated Controls" 1863 "Thomas G. Faria Co." 1862 "Sanshin" 1861 "Vector CANtech" 1860 "MMP" 1859 "Kvasar AB" 1858 "Litton" 1857 "Simrad" 1856 "Trimble" 1855 "Furuno USA" 1854 "Northstar Technologies" 1853 "Japan Radio Co." 1852 "Navionics" 1851 "Raymarine" 1850 "Teleflex" 222 "Generac Power Systems, Inc." 221 "SiE" 220 "Beede Electrical Instrument Company, Inc." 219 "Cat OEM Solutions" 218 "Gits Manufacturing Company" 217 "RM Michaelides Software & Elektronik GmbH" 216 "Paneltronics Inc." 215 "Aetna Engineering/Fireboy-Xintex" 214 "MC elettronica Srl" 213 "CNH Belgium N.V." 212 "Sure Power Industries, Inc." 211 "DNA Group" 210 "Iteris, Inc." 209 "Bell Equip. Co. SA (PTY) LTD" 208 "Drew Technologies, Inc." 207 "Otto Engineering" 206 "port GmbH" 205 "SmarTire Systems Inc" 204 "The Morey Corporation" 203 "MILtronik GmbH" 202 "Curtis Instruments, Inc." 201 "Disenos y Tecnologia S.A." 200 "MGM Brakes" 199 "Actia Corp." 198 "Mystic Valley Communications" 197 "Mechron Power Systems" 196 "LEMKEN GmbH & Co. KG" 195 "General Engine Products" 194 "TriMark Corporation" 193 "Nobletec" 192 "Floscan" 191 "XATA Corporation" 190 "Hella KGaA Hueck & Co." 189 "QUALCOMM" 188 "EMP Corp." 187 "Air-Weigh" 186 "Altronic, Inc." 185 "Beede Electrical Instrument Company" 184 "EIA Electronics" 183 "KDS Controls, Inc." 182 "Vehicle Systems Engineering B.V." 181 "Coretronics, Inc." 180 "Smart Power Systems" 179 "TeeJet Technologies Denmark" 178 "Siemens VDO Automotive AG" 177 "Diagnostic System Associates" 176 "Moritz Aerospace" 175 "Veris Technologies, Inc." 174 "AB Volvo Penta" 173 "Ryeso, Inc." 172 "Yanmar Marine USA" 171 "Wachendorff Elektronik GmbH & Co. KG" 170 "Computronics Corporation Ltd." 169 "Marlin Technologies Inc." 168 "Xantrex" 167 "JLG Industries Inc." 166 "Phoenix International" 165 "CPAC Systems AB" 164 "DaimlerChrysler Off-Highway" 163 "BRP Inc." 162 "Axiomatic Technologies" 161 "Offshore Systems (UK) Limited" 160 "Nido" 159 "NTech Industries Inc." 158 "Firestone Industrial Products Company" 157 "ISSPRO Inc." 156 "ITT Industries - Cannon" 155 "Vetronix Corporation" 154 "Westerbeke Corporation" 153 "Woodward, Industrial Controls Division" 152 "elobau GmbH & Co. KG" 151 "Raven Industries Inc. - Flow Controls Division" 150 "Fleetguard" 149 "Holset" 148 "Blue Water Data, Inc." 147 "Nautibus Electronic GmbH" 146 "Maxima Technologies" 145 "MurCal Controls" 144 "Mercury Marine" 143 "W. Gmeiner GmbH & Co." 142 "TRW Automotive (Commercial Steering Systems)" 141 "Thales Navigation Ltd." 140 "Lowrance Electronics, Inc." 139 "Caterpillar Trimble Control Technologies (CTCT), LLC" 138 "Georg Fritzmeier GmbH & Co. KG" 137 "Maretron" 136 "Komatsu Ltd." 135 "Airmar Technology Corporation" 134 "Iris Technology Ltd." 133 "Bucher Schoerling GmbH" 132 "Mulag-Fahrzeugwerk" 131 "ITT Industries" 130 "Nido - Universal Machines B.V." 129 "OMNEX Control Systems, Inc." 128 "Gerhard Duecker GmbH & Co. KG" 127 "Holland USA" 126 "Driver Tech" 125 "Nevada Automotive Test Center" 124 "Hydac Electronic" 123 "Basler Electric" 122 "FG Wilson (Engineering) Limited" 121 "HED (Hydro Electronic Devices, Inc.)" 120 "RDS Technology Ltd." 119 "IntegriNautics" 118 "Intron GmbH" 117 "HUSCO International" 116 "BEELINE Technologies" 115 "NACCO Materials Handling Group, Inc." 114 "EControls, Inc." 113 "Stress-Tek, Inc." 112 "MECALAC" 111 "Maschinenfabrik Bernhard Krone GmbH" 110 "EPIQ Sensor-Nite" 109 "TeeJet Technologies Denmark" 108 "WTK-Elecktronik GmbH" 107 "Grimme Landmaschinen GmbH & Co. KG" 106 "BAE Systems Controls, Inc." 105 "Kiepe Elektrik GmbH & Co. KG" 104 "Claas Selbstfahrende Erntemaschinen GmbH" 103 "Agrocom GmbH & Co. Agrarsystem KG" 102 "AGCO GmbH & Co." 101 "Sensoria" 100 "VDO Technik AG" 99 "International Transmissions Ltd (ITL)" 98 "Mueller-Elektronik GmbH & Co." 97 "Ag Leader Technology, Inc." 96 "Mech@tronic IT GmbH" 95 "Pacific Insight Electronics Corp." 94 "CNH Global N.V." 93 "Perkins Engines Company Ltd." 92 "Ag-Chem Equipment Co., Inc." 91 "BSG Bodensee Steuergeraete GmbH" 90 "Knorr-Bremse SfN GmbH" 89 "Kverneland Group, Electronics Division" 88 "Satloc Precision GPS" 87 "J.C. Bamford Excavators Ltd (JCB)" 86 "C.E. Niehoff & Company" 85 "Kohler Co." 84 "New Holland UK Limited" 83 "Eaton VORAD Technologies" 82 "Bobcat/Ingersoll-Rand" 81 "Fire Research Corp" 80 "Twin Disc, Inc." 79 "Daimler Benz AG - Engine Division (PBM)" 78 "Frank W. Murphy Manufacturing, Inc." 77 "Deere Power Systems Group" 76 "unused" 75 "Deere & Co. Agricultural Division" 74 "Eaton Axle-Brake Division" 73 "LeTourneau, Inc." 72 "Sisu Corporation" 71 "Vansco Electronics Ltd." 70 "Flex-Coil Limited" 69 "Trimble Navigation" 68 "Scania" 67 "Funk Manufacturing Company" 66 "John Deere Construction Equipment Division" 65 "MAN Nutzfahrzeuge AG" 64 "unused" 63 "ZF Industries Inc." 62 "Wabco" 61 "Volvo Truck Corp." 60 "Volvo Trucks North America Inc." 59 "VES Inc." 58 "SPX Corporation, OTC Division" 57 "Sauer-Danfoss Co." 56 "SAIC" 55 "Ryder System Inc." 54 "Meritor Wabco" 53 "Continental Automotive Systems US, Inc." 52 "Meritor Automotive, Inc." 51 "Robert Bosch GmbH" 50 "Robert Bosch Corp" 49 "RE America Inc." 48 "Pollak Alphabet" 47 "Phillips Semiconductor" 46 "Parasoft Computing Solutions" 45 "PACCAR" 44 "Nippondenso Co. Ltd." 43 "International Truck and Engine Corp. Vehicle Electronics" 42 "International Truck and Engine Corp. Engine Electronics" 41 "Motorola Inc." 40 "Motorola AIEG Inc." 39 "Microfirm Inc." 38 "Micro Processor Systems Inc." 37 "Mack Trucks Inc." 36 "Lucas Ltd." 35 "Kenworth Truck Co." 34 "Kelsey Hayes Co." 33 "John Deere" 32 "Jacobs Vehicle Systems" 31 "J Pollak Corp." 30 "Isuzu Motors Ltd." 29 "Hino Motors Ltd." 28 "Grote Ind. Inc." 27 "GMC" 26 "General Motors Corp., Service Technology Group" 25 "Daimler Trucks North America LLC" 24 "Ford Motor Co., Vehicle Controls" 23 "Ford Motor Co., Heavy Truck" 22 "Ford Motor Co., Electronic Concepts $ Systems" 21 "Echilin Inc., Midland Brake Inc." 20 "Eaton Ltd" 19 "Eaton Corp. Trucking Info Services" 18 "Eaton Corp, Transmission Division" 17 "Eaton Corp. Res & Dev" 16 "Eaton Corp." 15 "Dickey-John Corp." 14 "Detroit Diesel Corporation" 13 "Delco Electronics" 12 "Deere & Company, Precision Farming" 11 "Dearborn Group Inc." 10 "Cummins Engine Co." 9 "Chrysler Corp." 8 "Caterpillar Inc." 7 "Case Corp." 6 "Berifors Electronics AB" 5 "AMP Inc." 4 "Ametek-Dixson" 3 "Ametek, US Gauge Division" 2 "Allison Transmission, GMC" 1 "Allied Signal Inc." 0 "Reserved" 231 "Topcon Positioning Systems, Inc." 230 "Saucon Technologies" 229 "Garmin International Inc." 228 "ZF Marine Electronics" 227 "Lykketronic A/S" 226 "Monaco Coach Corporation" 225 "SKF" 224 "EMMI Network, S.L." 223 "Vaueo Retarder Co., Ltd." 263 "IMMI" 262 "HydraForce, Inc" 261 "Red Dot Corporation" 260 "Reichhardt GmbH" 259 "Jetter AG" 258 "ARAG" 257 "Honda Motor Co., Ltd" 256 "Tyco Electronics AMP" 255 "MEAS France" 254 "GE Sensing" 253 "Mobile Control Systems" 298 "Holley Performance" 297 "Zonar Systems Inc" 296 "micro dynamics GmbH" 295 "BEP Marine" 294 "Grayhill Inc." 293 "Spyder Controls Corp." 292 "IKUSI - Angel Iglesias S.A." 291 "Groeneveld Transport Efficiency BV" 290 "Kuebler GmbH" 289 "Watlow" 288 "Mitsubishi FUSO Truck & Bus Corp." 287 "NTech Industries, Inc" 286 "Coelmo srl" 285 "Sea Recovery Corp" 284 "Mobile Tech Chile" 283 "CWF Hamilton & Co Ltd" 282 "Medallion Instrumentation Systems" 281 "Precision Governors LLC" 311 "Patrick Power Products" 310 "TECNORD srl" 309 "Krauss-Maffei Wegmann GmbH & Co. KG" 308 "Cyntrx" 307 "MAS Technologies" 306 "Sleipner Motor AB" 305 "NovAtel Inc" 304 "EmpirBus AB" 303 "CTS Corporation" 302 "Nissin Kogyo Co., LTD" 301 "Parker Hannifin (UK) Ltd FDE group" 300 "Systron Donner Automotive" 299 "Rauch Landmaschinen GmbH" 280 "Leica Geosystems Pty Ltd" 279 "Geometris LP" 278 "Takata Electronics" 277 "LHP Telematics" 276 "Aqua-Hot Heating Systems" 275 "Navico Egersund AS" 274 "LTW Technology Co., LTD" 273 "Active Research Limited" 272 "Gross Mechanical Laboratories, Inc" 327 "Sonceboz SA" 326 "Akron Brass Company" 325 "ASM Automation Sensorik Messtechnik GmbH" 324 "Snap-on Diagnostics" 323 "Mobileye Vision Technologies Ltd." 322 "MICHENKA s.r.o." 321 "Ultra Electronics, Electrics" 320 "Miedema Landbouwwerktuigenfabriek B.V." 319 "Cadec Global" 318 "SAT Plan" 317 "Navtronics Bvba" 316 "ITT Flow Control" 315 "Icom Incorporated" 314 "CSM GmbH" 313 "Ilmor Engineering, Inc" 312 "Lectronix, Inc." 271 "Cole Hersee" 270 "Tennant" 269 "Saft America Inc.,  Space & Defense Division" 268 "Accurate Technologies" 267 "Red Lion Controls, Inc" 266 "International Thermal Research Ltd" 265 "MTS Sensor Technologie GmbH" 264 "Autolync" 248 "Cooper Standard Automotive Active Systems Group" 247 "ePULSE" 246 "Class 1, Inc" 245 "Capstan Ag Systems, Inc." 244 "Techno-Matic" 243 "eRide, Inc." 242 "Kokusandenki Co. Ltd" 241 "Schneider Automation SAS " 240 "Vanair Mfg" 239 "May & Scofield Ltd" 238 "ZF Friedrichshafen AG" 237 "Agtron Enterprises Inc" 236 "Norac Systems International Inc" 235 "SailorMade Marine Telemetry - Tetra Technology Ltd." 234 "Mondial electronic GmbH" ;
VAL_ 2566838526 VehicleSystem5 127 "Not Available" 0 "Ind. Process Control Stationary" ;
VAL_ 2566838526 VehicleSystem4 100 "Deck/Cargo/Fishing equip. sys" 90 "Environmental (HVAC) Systems" 80 "Instrumentation/General Systems" 70 "Communications Systems" 60 "Navigation Systems" 50 "Propulsion Systems" 40 "Steering Systems" 30 "Power Mgmt and lighting systems" 25 "Gateway" 20 "Safety Systems" 10 "System Tools" 127 "Not Available" 0 "Non-specific System" ;
VAL_ 2566838526 VehicleSystem3 8 "Grader" 7 "Four Wheel Drive Loader" 6 "Forklift" 5 "Excavator" 4 "Crawler" 3 "Backhoe" 2 "Articulated Dump Truck" 1 "Skid Steer Loader" 127 "Not Available" 0 "Non-specific System" ;
VAL_ 2566838526 VehicleSystem2 16 "Skidder" 15 "Earth Work" 14 "Special Crops" 13 "Powered Auxiliary Device" 12 "Farm Yard Operations" 11 "Transport/Trailer" 10 "Irrigation" 9 "Forage" 8 "Root Harvesters" 7 "Harvesters" 6 "Sprayers" 5 "Fertilizers" 4 "Planters/Seeders" 3 "Secondary Tillage" 2 "Tillage" 1 "Tractor" 127 "Not Available" 0 "Non-specific System" ;
VAL_ 2566838526 VehicleSystem1 2 "Trailer" 1 "Tractor" 127 "Not Available" 0 "Non-specific System" ;
VAL_ 2565799424 VehicleSystem5 127 "Not Available" 0 "Ind. Process Control Stationary" ;
VAL_ 2565799424 VehicleSystem4 100 "Deck/Cargo/Fishing equip. sys" 90 "Environmental (HVAC) Systems" 80 "Instrumentation/General Systems" 70 "Communications Systems" 60 "Navigation Systems" 50 "Propulsion Systems" 40 "Steering Systems" 30 "Power Mgmt and lighting systems" 25 "Gateway" 20 "Safety Systems" 10 "System Tools" 127 "Not Available" 0 "Non-specific System" ;
VAL_ 2565799424 VehicleSystem3 8 "Grader" 7 "Four Wheel Drive Loader" 6 "Forklift" 5 "Excavator" 4 "Crawler" 3 "Backhoe" 2 "Articulated Dump Truck" 1 "Skid Steer Loader" 127 "Not Available" 0 "Non-specific System" ;
VAL_ 2565799424 VehicleSystem2 16 "Skidder" 15 "Earth Work" 14 "Special Crops" 13 "Powered Auxiliary Device" 12 "Farm Yard Operations" 11 "Transport/Trailer" 10 "Irrigation" 9 "Forage" 8 "Root Harvesters" 7 "Harvesters" 6 "Sprayers" 5 "Fertilizers" 4 "Planters/Seeders" 3 "Secondary Tillage" 2 "Tillage" 1 "Tractor" 127 "Not Available" 0 "Non-specific System" ;
VAL_ 2565799424 VehicleSystem1 2 "Trailer" 1 "Tractor" 127 "Not Available" 0 "Non-specific System" ;
VAL_ 2565799424 IndustryGroup 6 "Reserved for SAE" 7 "Reserved for SAE" 5 "IndustrialProcessCtrlStationary" 4 "Marine" 3 "Construction" 2 "Agricultural and Forestry" 1 "On-Highway" 0 "Global" ;
VAL_ 2565799424 VehicleSystem 0 "Non-specific System" 127 "Not Available" ;
VAL_ 2565799424 Function 127 "Reserved" 126 "Reserved" 125 "Reserved" 124 "Reserved" 123 "Reserved" 122 "Reserved" 121 "Reserved" 120 "Reserved" 119 "Reserved" 118 "Reserved" 117 "Reserved" 116 "Reserved" 115 "Reserved" 114 "Reserved" 113 "Reserved" 112 "Reserved" 111 "Reserved" 110 "Reserved" 109 "Reserved" 108 "Reserved" 107 "Reserved" 106 "Reserved" 105 "Reserved" 104 "Reserved" 103 "Reserved" 102 "Reserved" 101 "Reserved" 42 "Water Pump Control" 41 "Lighting - Operator Controls" 40 "Seat Control" 39 "Ignition Control Module" 38 "Tire Pressure Control" 37 "Cab Controller" 36 "Pneumatic - System Controller" 35 "Suspension - System Controller" 34 "Hydraulic Pump Controller" 33 "System Monitor" 32 "Headway Controller" 31 "Propulsion Battery Charger" 30 "Management Computer" 29 "Virtual Terminal (In Cab)" 28 "Off Vehicle Gateway" 27 "Power TakeOff (Secondary or Front)" 26 "Body Controller" 25 "Network Interconnect ECU" 24 "Vehicle Security" 23 "Vehicle Navigation" 22 "Aerodynamic Control" 21 "Cab Climate Control" 20 "Trip Recorder" 19 "Instrument Cluster" 18 "Suspension - Drive Axle" 17 "Suspension - Steer Axle" 16 "Steeting Controller" 15 "Fuel System" 14 "Cruise Control" 13 "Retarder - Driveline" 12 "Retarder - Engine" 11 "Brakes - Drive Axle" 10 "Brakes - Steer Axle" 9 "Brakes - System Controller" 8 "Axle - Drive" 7 "Axle - Steering" 6 "Power TakeOff - (Main or Rear)" 5 "Shift Control/Console" 4 "Battery Pack Monitor" 3 "Transmission" 2 "Electric Propulsion Control" 1 "Auxiliary Power Unit (APU)" 0 "Engine" 100 "Reserved" 99 "Reserved" 98 "Reserved" 97 "Reserved" 96 "Reserved" 95 "Reserved" 94 "Reserved" 93 "Reserved" 92 "Reserved" 91 "Reserved" 90 "Reserved" 89 "Reserved" 88 "Reserved" 87 "Reserved" 86 "Reserved" 85 "Reserved" 84 "Reserved" 83 "Reserved" 82 "Reserved" 81 "Reserved" 80 "Reserved" 79 "Reserved" 78 "Reserved" 77 "Reserved" 76 "Reserved" 75 "Reserved" 74 "Reserved" 73 "Reserved" 72 "Coolant Valve Controller" 71 "Transfer Case Control" 70 "Auxiliary Regeneration Device" 69 "Engine Emission Aftertreatement System" 68 "Aftertreatment system gas measurement" 67 "Electrical System Controller" 66 "I/O Controller" 65 "Gas Flow Measurement" 64 "Endurance Braking" 63 "Engine Valve Controller" 62 "On-Board Diagnostic Unit" 61 "File Server/Printer" 60 "Cab Display" 59 "Starter" 58 "Fan Drive Control" 57 "Steering Column Unit" 56 "Communications Unit, Radio" 55 "Communications Unit, Satellite" 54 "Communications Unit, Cellular" 53 "Alternator/Charging System" 52 "Chassis Controller" 51 "Forward-Looking Collision Warning System" 50 "Auxiliary Heater" 49 "Clutch/Converter Control" 48 "Ramp Control" 47 "Information System Controller" 46 "Oil Sensor Unit" 45 "Vehicle Dynamic Stability Control" 44 "Exhaust Emission Control" 43 "Transmission Display" ;
VAL_ 2565799424 ManufacturerCode 1863 "Thomas G. Faria Co." 1862 "Sanshin" 1861 "Vector CANtech" 1860 "MMP" 1859 "Kvasar AB" 1858 "Litton" 1857 "Simrad" 1856 "Trimble" 1855 "Furuno USA" 1854 "Northstar Technologies" 1853 "Japan Radio Co." 1852 "Navionics" 1851 "Raymarine" 1850 "Teleflex" 222 "Generac Power Systems, Inc." 221 "SiE" 220 "Beede Electrical Instrument Company, Inc." 219 "Cat OEM Solutions" 218 "Gits Manufacturing Company" 217 "RM Michaelides Software & Elektronik GmbH" 216 "Paneltronics Inc." 215 "Aetna Engineering/Fireboy-Xintex" 214 "MC elettronica Srl" 213 "CNH Belgium N.V." 212 "Sure Power Industries, Inc." 211 "DNA Group" 210 "Iteris, Inc." 209 "Bell Equip. Co. SA (PTY) LTD" 208 "Drew Technologies, Inc." 207 "Otto Engineering" 206 "port GmbH" 205 "SmarTire Systems Inc" 204 "The Morey Corporation" 203 "MILtronik GmbH" 202 "Curtis Instruments, Inc." 201 "Disenos y Tecnologia S.A." 200 "MGM Brakes" 199 "Actia Corp." 198 "Mystic Valley Communications" 197 "Mechron Power Systems" 196 "LEMKEN GmbH & Co. KG" 195 "General Engine Products" 194 "TriMark Corporation" 193 "Jeppesen Marine" 192 "Floscan" 191 "XATA Corporation" 190 "Hella KGaA Hueck & Co." 189 "QUALCOMM" 188 "EMP Corp." 187 "Air-Weigh" 186 "Altronic, Inc." 185 "Beede Electrical Instrument Company" 184 "EIA Electronics" 183 "KDS Controls, Inc." 182 "Vehicle Systems Engineering B.V." 181 "Coretronics, Inc." 180 "Smart Power Systems" 179 "Midwest Technologies Illinois, LLC" 178 "Siemens VDO Automotive AG" 177 "Diagnostic System Associates" 176 "Moritz Aerospace" 175 "Veris Technologies, Inc." 174 "AB Volvo Penta" 173 "Ryeso, Inc." 172 "Yanmar Marine USA" 171 "Wachendorff Elektronik GmbH & Co. KG" 170 "Computronics Corporation Ltd." 169 "Marlin Technologies Inc." 168 "Xantrex" 167 "JLG Industries Inc." 166 "Phoenix International" 165 "CPAC Systems AB" 164 "DaimlerChrysler Off-Highway" 163 "BRP Inc." 162 "Axiomatic Technologies" 161 "Offshore Systems (UK) Limited" 160 "Nido" 159 "NTech Industries Inc." 158 "Firestone Industrial Products Company" 157 "ISSPRO Inc." 156 "ITT Industries - Cannon" 155 "Vetronix Corporation" 154 "Westerbeke Corporation" 153 "Woodward, Industrial Controls Division" 152 "Elobau Elektrobauelemente GmbH & Co. KG" 151 "Raven Industries Inc. - Flow Controls Division" 150 "Fleetguard" 149 "Holset" 148 "Blue Water Data, Inc." 147 "Nautibus Electronic GmbH" 146 "Maxima Technologies" 145 "MurCal Controls" 144 "Mercury Marine" 143 "W. Gmeiner GmbH & Co." 142 "TRW Automotive (Commercial Steering Systems)" 141 "Thales Navigation Ltd." 140 "Lowrance Electronics, Inc." 139 "Caterpillar Trimble Control Technologies (CTCT), LLC" 138 "Georg Fritzmeier GmbH & Co. KG" 137 "Maretron" 136 "Komatsu Ltd." 135 "Airmar Technology Corporation" 134 "Iris Technology Ltd." 133 "Bucher Schoerling GmbH" 132 "Mulag-Fahrzeugwerk" 131 "ITT Industries" 130 "Nido - Universal Machines B.V." 129 "OMNEX Control Systems, Inc." 128 "Gerhard Duecker GmbH & Co. KG" 127 "Holland USA" 126 "Driver Tech" 125 "Nevada Automotive Test Center" 124 "Hydac Electronic" 123 "Basler Electric" 122 "FG Wilson (Engineering) Limited" 121 "HED (Hydro Electronic Devices, Inc.)" 120 "RDS Technology Ltd." 119 "IntegriNautics" 118 "Intron GmbH" 117 "HUSCO International" 116 "BEELINE Technologies" 115 "NACCO Materials Handling Group, Inc." 114 "EControls, Inc." 113 "Stress-Tek, Inc." 112 "MECALAC" 111 "Maschinenfabrik Bernhard Krone GmbH" 110 "EPIQ Sensor-Nite" 109 "LH Technologies ApS" 108 "WTK-Elecktronik GmbH" 107 "Grimme Landmaschinen GmbH & Co. KG" 106 "BAE Systems Controls, Inc." 105 "Kiepe Elektrik GmbH & Co. KG" 104 "Claas Selbstfahrende Erntemaschinen GmbH" 103 "Agrocom GmbH & Co. Agrarsystem KG" 102 "AGCO GmbH & Co." 101 "Sensoria" 100 "VDO Technik AG" 99 "International Transmissions Ltd (ITL)" 98 "Mueller-Elektronik GmbH & Co." 97 "Ag Leader Technology, Inc." 96 "Mech@tronic IT GmbH" 95 "Pacific Insight Electronics Corp." 94 "CNH Global N.V." 93 "Perkins Engines Company Ltd." 92 "Ag-Chem Equipment Co., Inc." 91 "BSG Bodensee Steuergeraete GmbH" 90 "Knorr-Bremse SfN GmbH" 89 "Kverneland Group, Electronics Division" 88 "Satloc Precision GPS" 87 "J.C. Bamford Excavators Ltd (JCB)" 86 "C.E. Niehoff & Company" 85 "Kohler Co." 84 "New Holland UK Limited" 83 "Eaton VORAD Technologies" 82 "Bobcat/Ingersoll-Rand" 81 "Fire Research Corp" 80 "Twin Disc, Inc." 79 "Daimler Benz AG - Engine Division (PBM)" 78 "Frank W. Murphy Manufacturing, Inc." 77 "Deere Power Systems Group" 76 "unused" 75 "Deere & Co. Agricultural Division" 74 "Eaton Axle-Brake Division" 73 "LeTourneau, Inc." 72 "Sisu Corporation" 71 "Vansco Electronics Ltd." 70 "Flex-Coil Limited" 69 "Trimble Navigation" 68 "Scania" 67 "Funk Manufacturing Company" 66 "John Deere Construction Equipment Division" 65 "MAN Nutzfahrzeuge AG" 64 "unused" 63 "ZF Industries Inc." 62 "Wabco" 61 "Volvo Truck Corp." 60 "Volvo Trucks North America Inc." 59 "VES Inc." 58 "SPX Corporation, OTC Division" 57 "Sauer-Danfoss Co." 56 "SAIC" 55 "Ryder System Inc." 54 "Meritor Wabco" 53 "Rockwell Land Transportation" 52 "Meritor Automotive, Inc." 51 "Robert Bosch GmbH" 50 "Robert Bosch Corp" 49 "RE America Inc." 48 "Pollak Alphabet" 47 "Phillips Semiconductor" 46 "Parasoft Computing Solutions" 45 "PACCAR" 44 "Nippondenso Co. Ltd." 43 "International Truck and Engine Corp. Vehicle Electronics" 42 "International Truck and Engine Corp. Engine Electronics" 41 "Motorola Inc." 40 "Motorola AIEG Inc." 39 "Microfirm Inc." 38 "Micro Processor Systems Inc." 37 "Mack Trucks Inc." 36 "Lucas Ltd." 35 "Kenworth Truck Co." 34 "Kelsey Hayes Co." 33 "John Deere" 32 "Jacobs Vehicle Systems" 31 "J Pollak Corp." 30 "Isuzu Motors Ltd." 29 "Hino Motors Ltd." 28 "Grote Ind. Inc." 27 "GMC" 26 "General Motors Corp., Service Technology Group" 25 "Freightliner LLC" 24 "Ford Motor Co., Vehicle Controls" 23 "Ford Motor Co., Heavy Truck" 22 "Ford Motor Co., Electronic Concepts $ Systems" 21 "Echilin Inc., Midland Brake Inc." 20 "Eaton Ltd" 19 "Eaton Corp. Trucking Info Services" 18 "Eaton Corp, Transmission Division" 17 "Eaton Corp. Res & Dev" 16 "Eaton Corp." 15 "Dickey-John Corp." 14 "Detroit Diesel Corporation" 13 "Delco Electronics" 12 "Deere & Company, Precision Farming" 11 "Dearborn Group Inc." 10 "Cummins Engine Co." 9 "Chrysler Corp." 8 "Caterpillar Inc." 7 "Case Corp." 6 "Berifors Electronics AB" 5 "AMP Inc." 4 "Ametek-Dixson" 3 "Ametek, US Gauge Division" 2 "Allison Transmission, GMC" 1 "Allied Signal Inc." 0 "Reserved" ;
VAL_ 2565406208 ControlByte 24 "EAbort" 23 "EEoMACK" 22 "EDPO" 21 "ECTS" 20 "ERTS" 3 "CannotRespond" 2 "AccessDenied" 1 "NACK" 0 "ACK" 255 "Abort" 32 "BAM" 19 "EoMA" 17 "CTS" 16 "RTS" ;
VAL_ 2565406259 ControlByte 24 "EAbort" 23 "EEoMACK" 22 "EDPO" 21 "ECTS" 20 "ERTS" 3 "CannotRespond" 2 "AccessDenied" 1 "NACK" 0 "ACK" 255 "Abort" 32 "BAM" 19 "EoMA" 17 "CTS" 16 "RTS" ;
VAL_ 2565799475 VehicleSystem5 127 "Not Available" 0 "Ind. Process Control Stationary" ;
VAL_ 2565799475 VehicleSystem4 100 "Deck/Cargo/Fishing equip. sys" 90 "Environmental (HVAC) Systems" 80 "Instrumentation/General Systems" 70 "Communications Systems" 60 "Navigation Systems" 50 "Propulsion Systems" 40 "Steering Systems" 30 "Power Mgmt and lighting systems" 25 "Gateway" 20 "Safety Systems" 10 "System Tools" 127 "Not Available" 0 "Non-specific System" ;
VAL_ 2565799475 VehicleSystem3 8 "Grader" 7 "Four Wheel Drive Loader" 6 "Forklift" 5 "Excavator" 4 "Crawler" 3 "Backhoe" 2 "Articulated Dump Truck" 1 "Skid Steer Loader" 127 "Not Available" 0 "Non-specific System" ;
VAL_ 2565799475 VehicleSystem2 16 "Skidder" 15 "Earth Work" 14 "Special Crops" 13 "Powered Auxiliary Device" 12 "Farm Yard Operations" 11 "Transport/Trailer" 10 "Irrigation" 9 "Forage" 8 "Root Harvesters" 7 "Harvesters" 6 "Sprayers" 5 "Fertilizers" 4 "Planters/Seeders" 3 "Secondary Tillage" 2 "Tillage" 1 "Tractor" 127 "Not Available" 0 "Non-specific System" ;
VAL_ 2565799475 VehicleSystem1 2 "Trailer" 1 "Tractor" 127 "Not Available" 0 "Non-specific System" ;
VAL_ 2565799475 IndustryGroup 6 "Reserved for SAE" 7 "Reserved for SAE" 5 "IndustrialProcessCtrlStationary" 4 "Marine" 3 "Construction" 2 "Agricultural and Forestry" 1 "On-Highway" 0 "Global" ;
VAL_ 2565799475 VehicleSystem 0 "Non-specific System" 127 "Not Available" ;
VAL_ 2565799475 Function 127 "Reserved" 126 "Reserved" 125 "Reserved" 124 "Reserved" 123 "Reserved" 122 "Reserved" 121 "Reserved" 120 "Reserved" 119 "Reserved" 118 "Reserved" 117 "Reserved" 116 "Reserved" 115 "Reserved" 114 "Reserved" 113 "Reserved" 112 "Reserved" 111 "Reserved" 110 "Reserved" 109 "Reserved" 108 "Reserved" 107 "Reserved" 106 "Reserved" 105 "Reserved" 104 "Reserved" 103 "Reserved" 102 "Reserved" 101 "Reserved" 42 "Water Pump Control" 41 "Lighting - Operator Controls" 40 "Seat Control" 39 "Ignition Control Module" 38 "Tire Pressure Control" 37 "Cab Controller" 36 "Pneumatic - System Controller" 35 "Suspension - System Controller" 34 "Hydraulic Pump Controller" 33 "System Monitor" 32 "Headway Controller" 31 "Propulsion Battery Charger" 30 "Management Computer" 29 "Virtual Terminal (In Cab)" 28 "Off Vehicle Gateway" 27 "Power TakeOff (Secondary or Front)" 26 "Body Controller" 25 "Network Interconnect ECU" 24 "Vehicle Security" 23 "Vehicle Navigation" 22 "Aerodynamic Control" 21 "Cab Climate Control" 20 "Trip Recorder" 19 "Instrument Cluster" 18 "Suspension - Drive Axle" 17 "Suspension - Steer Axle" 16 "Steeting Controller" 15 "Fuel System" 14 "Cruise Control" 13 "Retarder - Driveline" 12 "Retarder - Engine" 11 "Brakes - Drive Axle" 10 "Brakes - Steer Axle" 9 "Brakes - System Controller" 8 "Axle - Drive" 7 "Axle - Steering" 6 "Power TakeOff - (Main or Rear)" 5 "Shift Control/Console" 4 "Battery Pack Monitor" 3 "Transmission" 2 "Electric Propulsion Control" 1 "Auxiliary Power Unit (APU)" 0 "Engine" 100 "Reserved" 99 "Reserved" 98 "Reserved" 97 "Reserved" 96 "Reserved" 95 "Reserved" 94 "Reserved" 93 "Reserved" 92 "Reserved" 91 "Reserved" 90 "Reserved" 89 "Reserved" 88 "Reserved" 87 "Reserved" 86 "Reserved" 85 "Reserved" 84 "Reserved" 83 "Reserved" 82 "Reserved" 81 "Reserved" 80 "Reserved" 79 "Reserved" 78 "Reserved" 77 "Reserved" 76 "Reserved" 75 "Reserved" 74 "Reserved" 73 "Reserved" 72 "Coolant Valve Controller" 71 "Transfer Case Control" 70 "Auxiliary Regeneration Device" 69 "Engine Emission Aftertreatement System" 68 "Aftertreatment system gas measurement" 67 "Electrical System Controller" 66 "I/O Controller" 65 "Gas Flow Measurement" 64 "Endurance Braking" 63 "Engine Valve Controller" 62 "On-Board Diagnostic Unit" 61 "File Server/Printer" 60 "Cab Display" 59 "Starter" 58 "Fan Drive Control" 57 "Steering Column Unit" 56 "Communications Unit, Radio" 55 "Communications Unit, Satellite" 54 "Communications Unit, Cellular" 53 "Alternator/Charging System" 52 "Chassis Controller" 51 "Forward-Looking Collision Warning System" 50 "Auxiliary Heater" 49 "Clutch/Converter Control" 48 "Ramp Control" 47 "Information System Controller" 46 "Oil Sensor Unit" 45 "Vehicle Dynamic Stability Control" 44 "Exhaust Emission Control" 43 "Transmission Display" ;
VAL_ 2565799475 ManufacturerCode 1863 "Thomas G. Faria Co." 1862 "Sanshin" 1861 "Vector CANtech" 1860 "MMP" 1859 "Kvasar AB" 1858 "Litton" 1857 "Simrad" 1856 "Trimble" 1855 "Furuno USA" 1854 "Northstar Technologies" 1853 "Japan Radio Co." 1852 "Navionics" 1851 "Raymarine" 1850 "Teleflex" 222 "Generac Power Systems, Inc." 221 "SiE" 220 "Beede Electrical Instrument Company, Inc." 219 "Cat OEM Solutions" 218 "Gits Manufacturing Company" 217 "RM Michaelides Software & Elektronik GmbH" 216 "Paneltronics Inc." 215 "Aetna Engineering/Fireboy-Xintex" 214 "MC elettronica Srl" 213 "CNH Belgium N.V." 212 "Sure Power Industries, Inc." 211 "DNA Group" 210 "Iteris, Inc." 209 "Bell Equip. Co. SA (PTY) LTD" 208 "Drew Technologies, Inc." 207 "Otto Engineering" 206 "port GmbH" 205 "SmarTire Systems Inc" 204 "The Morey Corporation" 203 "MILtronik GmbH" 202 "Curtis Instruments, Inc." 201 "Disenos y Tecnologia S.A." 200 "MGM Brakes" 199 "Actia Corp." 198 "Mystic Valley Communications" 197 "Mechron Power Systems" 196 "LEMKEN GmbH & Co. KG" 195 "General Engine Products" 194 "TriMark Corporation" 193 "Jeppesen Marine" 192 "Floscan" 191 "XATA Corporation" 190 "Hella KGaA Hueck & Co." 189 "QUALCOMM" 188 "EMP Corp." 187 "Air-Weigh" 186 "Altronic, Inc." 185 "Beede Electrical Instrument Company" 184 "EIA Electronics" 183 "KDS Controls, Inc." 182 "Vehicle Systems Engineering B.V." 181 "Coretronics, Inc." 180 "Smart Power Systems" 179 "Midwest Technologies Illinois, LLC" 178 "Siemens VDO Automotive AG" 177 "Diagnostic System Associates" 176 "Moritz Aerospace" 175 "Veris Technologies, Inc." 174 "AB Volvo Penta" 173 "Ryeso, Inc." 172 "Yanmar Marine USA" 171 "Wachendorff Elektronik GmbH & Co. KG" 170 "Computronics Corporation Ltd." 169 "Marlin Technologies Inc." 168 "Xantrex" 167 "JLG Industries Inc." 166 "Phoenix International" 165 "CPAC Systems AB" 164 "DaimlerChrysler Off-Highway" 163 "BRP Inc." 162 "Axiomatic Technologies" 161 "Offshore Systems (UK) Limited" 160 "Nido" 159 "NTech Industries Inc." 158 "Firestone Industrial Products Company" 157 "ISSPRO Inc." 156 "ITT Industries - Cannon" 155 "Vetronix Corporation" 154 "Westerbeke Corporation" 153 "Woodward, Industrial Controls Division" 152 "Elobau Elektrobauelemente GmbH & Co. KG" 151 "Raven Industries Inc. - Flow Controls Division" 150 "Fleetguard" 149 "Holset" 148 "Blue Water Data, Inc." 147 "Nautibus Electronic GmbH" 146 "Maxima Technologies" 145 "MurCal Controls" 144 "Mercury Marine" 143 "W. Gmeiner GmbH & Co." 142 "TRW Automotive (Commercial Steering Systems)" 141 "Thales Navigation Ltd." 140 "Lowrance Electronics, Inc." 139 "Caterpillar Trimble Control Technologies (CTCT), LLC" 138 "Georg Fritzmeier GmbH & Co. KG" 137 "Maretron" 136 "Komatsu Ltd." 135 "Airmar Technology Corporation" 134 "Iris Technology Ltd." 133 "Bucher Schoerling GmbH" 132 "Mulag-Fahrzeugwerk" 131 "ITT Industries" 130 "Nido - Universal Machines B.V." 129 "OMNEX Control Systems, Inc." 128 "Gerhard Duecker GmbH & Co. KG" 127 "Holland USA" 126 "Driver Tech" 125 "Nevada Automotive Test Center" 124 "Hydac Electronic" 123 "Basler Electric" 122 "FG Wilson (Engineering) Limited" 121 "HED (Hydro Electronic Devices, Inc.)" 120 "RDS Technology Ltd." 119 "IntegriNautics" 118 "Intron GmbH" 117 "HUSCO International" 116 "BEELINE Technologies" 115 "NACCO Materials Handling Group, Inc." 114 "EControls, Inc." 113 "Stress-Tek, Inc." 112 "MECALAC" 111 "Maschinenfabrik Bernhard Krone GmbH" 110 "EPIQ Sensor-Nite" 109 "LH Technologies ApS" 108 "WTK-Elecktronik GmbH" 107 "Grimme Landmaschinen GmbH & Co. KG" 106 "BAE Systems Controls, Inc." 105 "Kiepe Elektrik GmbH & Co. KG" 104 "Claas Selbstfahrende Erntemaschinen GmbH" 103 "Agrocom GmbH & Co. Agrarsystem KG" 102 "AGCO GmbH & Co." 101 "Sensoria" 100 "VDO Technik AG" 99 "International Transmissions Ltd (ITL)" 98 "Mueller-Elektronik GmbH & Co." 97 "Ag Leader Technology, Inc." 96 "Mech@tronic IT GmbH" 95 "Pacific Insight Electronics Corp." 94 "CNH Global N.V." 93 "Perkins Engines Company Ltd." 92 "Ag-Chem Equipment Co., Inc." 91 "BSG Bodensee Steuergeraete GmbH" 90 "Knorr-Bremse SfN GmbH" 89 "Kverneland Group, Electronics Division" 88 "Satloc Precision GPS" 87 "J.C. Bamford Excavators Ltd (JCB)" 86 "C.E. Niehoff & Company" 85 "Kohler Co." 84 "New Holland UK Limited" 83 "Eaton VORAD Technologies" 82 "Bobcat/Ingersoll-Rand" 81 "Fire Research Corp" 80 "Twin Disc, Inc." 79 "Daimler Benz AG - Engine Division (PBM)" 78 "Frank W. Murphy Manufacturing, Inc." 77 "Deere Power Systems Group" 76 "unused" 75 "Deere & Co. Agricultural Division" 74 "Eaton Axle-Brake Division" 73 "LeTourneau, Inc." 72 "Sisu Corporation" 71 "Vansco Electronics Ltd." 70 "Flex-Coil Limited" 69 "Trimble Navigation" 68 "Scania" 67 "Funk Manufacturing Company" 66 "John Deere Construction Equipment Division" 65 "MAN Nutzfahrzeuge AG" 64 "unused" 63 "ZF Industries Inc." 62 "Wabco" 61 "Volvo Truck Corp." 60 "Volvo Trucks North America Inc." 59 "VES Inc." 58 "SPX Corporation, OTC Division" 57 "Sauer-Danfoss Co." 56 "SAIC" 55 "Ryder System Inc." 54 "Meritor Wabco" 53 "Rockwell Land Transportation" 52 "Meritor Automotive, Inc." 51 "Robert Bosch GmbH" 50 "Robert Bosch Corp" 49 "RE America Inc." 48 "Pollak Alphabet" 47 "Phillips Semiconductor" 46 "Parasoft Computing Solutions" 45 "PACCAR" 44 "Nippondenso Co. Ltd." 43 "International Truck and Engine Corp. Vehicle Electronics" 42 "International Truck and Engine Corp. Engine Electronics" 41 "Motorola Inc." 40 "Motorola AIEG Inc." 39 "Microfirm Inc." 38 "Micro Processor Systems Inc." 37 "Mack Trucks Inc." 36 "Lucas Ltd." 35 "Kenworth Truck Co." 34 "Kelsey Hayes Co." 33 "John Deere" 32 "Jacobs Vehicle Systems" 31 "J Pollak Corp." 30 "Isuzu Motors Ltd." 29 "Hino Motors Ltd." 28 "Grote Ind. Inc." 27 "GMC" 26 "General Motors Corp., Service Technology Group" 25 "Freightliner LLC" 24 "Ford Motor Co., Vehicle Controls" 23 "Ford Motor Co., Heavy Truck" 22 "Ford Motor Co., Electronic Concepts $ Systems" 21 "Echilin Inc., Midland Brake Inc." 20 "Eaton Ltd" 19 "Eaton Corp. Trucking Info Services" 18 "Eaton Corp, Transmission Division" 17 "Eaton Corp. Res & Dev" 16 "Eaton Corp." 15 "Dickey-John Corp." 14 "Detroit Diesel Corporation" 13 "Delco Electronics" 12 "Deere & Company, Precision Farming" 11 "Dearborn Group Inc." 10 "Cummins Engine Co." 9 "Chrysler Corp." 8 "Caterpillar Inc." 7 "Case Corp." 6 "Berifors Electronics AB" 5 "AMP Inc." 4 "Ametek-Dixson" 3 "Ametek, US Gauge Division" 2 "Allison Transmission, GMC" 1 "Allied Signal Inc." 0 "Reserved" ;
VAL_ 2566834699 FlashRedStopLamp 3 "Unavailable / Do Not Flash" 2 "Reserved" 1 "Fast Flash" 0 "Slow Flash" ;
VAL_ 2566834699 FlashProtectLamp 3 "Unavailable / Do Not Flash" 2 "Reserved" 1 "Fast Flash" 0 "Slow Flash" ;
VAL_ 2566834699 FlashMalfuncIndicatorLamp 3 "Unavailable / Do Not Flash" 2 "Reserved" 1 "Fast Flash" 0 "Slow Flash" ;
VAL_ 2566834699 FlashAmberWarningLamp 3 "Unavailable / Do Not Flash" 2 "Reserved" 1 "Fast Flash" 0 "Slow Flash" ;
VAL_ 2566834699 MalfunctionIndicatorLampStatus 3 "Not available" 2 "Reserved" 1 "Lamp on" 0 "Lamp off" ;
VAL_ 2566834699 AmberWarningLampStatus 3 "Not available" 2 "Reserved" 1 "Lamp on" 0 "Lamp off" ;
VAL_ 2566834699 RedStopLampState 3 "Not available" 2 "Reserved" 1 "Lamp on" 0 "Lamp off" ;
VAL_ 2566834699 ProtectLampStatus 3 "Not available" 2 "Reserved" 1 "Lamp on" 0 "Lamp off" ;
VAL_ 2566834955 MalfunctionIndicatorLampStatus 3 "Not available" 2 "Reserved" 1 "Lamp on" 0 "Lamp off" ;
VAL_ 2566834955 RedStopLampState 3 "Not available" 2 "Reserved" 1 "Lamp on" 0 "Lamp off" ;
VAL_ 2566834955 AmberWarningLampStatus 3 "Not available" 2 "Reserved" 1 "Lamp on" 0 "Lamp off" ;
VAL_ 2566834955 ProtectLampStatus 3 "Not available" 2 "Reserved" 1 "Lamp on" 0 "Lamp off" ;
VAL_ 2566834955 FlashRedStopLamp 3 "Unavailable / Do Not Flash" 2 "Reserved" 1 "Fast Flash" 0 "Slow Flash" ;
VAL_ 2566834955 FlashProtectLamp 3 "Unavailable / Do Not Flash" 2 "Reserved" 1 "Fast Flash" 0 "Slow Flash" ;
VAL_ 2566834955 FlashMalfuncIndicatorLamp 3 "Unavailable / Do Not Flash" 2 "Reserved" 1 "Fast Flash" 0 "Slow Flash" ;
VAL_ 2566834955 FlashAmberWarningLamp 3 "Unavailable / Do Not Flash" 2 "Reserved" 1 "Fast Flash" 0 "Slow Flash" ;
VAL_ 2566764043 SPNSupportTypeSTR3 1 "NotSupportedInScaledTestResults" 0 "SupportedInScaledTestResults" ;
VAL_ 2566764043 SPNSupportTypeSTR2 1 "NotSupportedInScaledTestResults" 0 "SupportedInScaledTestResults" ;
VAL_ 2566764043 SPNSupportTypeEFF3 1 "NotSupportedInExFreezeFrame" 0 "SupportedInExFreezeFrame" ;
VAL_ 2566764043 SPNSupportTypeEFF2 1 "NotSupportedInExFreezeFrame" 0 "SupportedInExFreezeFrame" ;
VAL_ 2566764043 SPNSupportTypeDS3 1 "NotSupportedInDataStream" 0 "SupportedInDataStream" ;
VAL_ 2566764043 SPNSupportTypeDS2 1 "NotSupportedInDataStream" 0 "SupportedInDataStream" ;
VAL_ 2566764043 SPNSupportTypeSTR1 1 "NotSupportedInScaledTestResults" 0 "SupportedInScaledTestResults" ;
VAL_ 2566764043 SPNSupportTypeDS1 1 "NotSupportedInDataStream" 0 "SupportedInDataStream" ;
VAL_ 2566764043 SPNSupportTypeEFF1 1 "NotSupportedInExFreezeFrame" 0 "SupportedInExFreezeFrame" ;
VAL_ 2566835467 EngTorqueMode 15 "Not available" 11 "Remote accelerator" 10 "Braking system" 9 "High speed governor" 8 "Torque limiting" 7 "ABS control" 6 "Transmission control" 5 "ASR control" 4 "Road speed governor" 3 "PTO governor" 2 "Cruise control" 1 "Accelerator pedal/operator selec" 0 "Low idle governor/no request (de" ;
VAL_ 2565799435 VehicleSystem5 127 "Not Available" 0 "Ind. Process Control Stationary" ;
VAL_ 2565799435 VehicleSystem4 100 "Deck/Cargo/Fishing equip. sys" 90 "Environmental (HVAC) Systems" 80 "Instrumentation/General Systems" 70 "Communications Systems" 60 "Navigation Systems" 50 "Propulsion Systems" 40 "Steering Systems" 30 "Power Mgmt and lighting systems" 25 "Gateway" 20 "Safety Systems" 10 "System Tools" 127 "Not Available" 0 "Non-specific System" ;
VAL_ 2565799435 VehicleSystem3 8 "Grader" 7 "Four Wheel Drive Loader" 6 "Forklift" 5 "Excavator" 4 "Crawler" 3 "Backhoe" 2 "Articulated Dump Truck" 1 "Skid Steer Loader" 127 "Not Available" 0 "Non-specific System" ;
VAL_ 2565799435 VehicleSystem2 16 "Skidder" 15 "Earth Work" 14 "Special Crops" 13 "Powered Auxiliary Device" 12 "Farm Yard Operations" 11 "Transport/Trailer" 10 "Irrigation" 9 "Forage" 8 "Root Harvesters" 7 "Harvesters" 6 "Sprayers" 5 "Fertilizers" 4 "Planters/Seeders" 3 "Secondary Tillage" 2 "Tillage" 1 "Tractor" 127 "Not Available" 0 "Non-specific System" ;
VAL_ 2565799435 VehicleSystem1 2 "Trailer" 1 "Tractor" 127 "Not Available" 0 "Non-specific System" ;
VAL_ 2565799435 IndustryGroup 6 "Reserved for SAE" 7 "Reserved for SAE" 5 "IndustrialProcessCtrlStationary" 4 "Marine" 3 "Construction" 2 "Agricultural and Forestry" 1 "On-Highway" 0 "Global" ;
VAL_ 2565799435 VehicleSystem 0 "Non-specific System" 127 "Not Available" ;
VAL_ 2565799435 Function 127 "Reserved" 126 "Reserved" 125 "Reserved" 124 "Reserved" 123 "Reserved" 122 "Reserved" 121 "Reserved" 120 "Reserved" 119 "Reserved" 118 "Reserved" 117 "Reserved" 116 "Reserved" 115 "Reserved" 114 "Reserved" 113 "Reserved" 112 "Reserved" 111 "Reserved" 110 "Reserved" 109 "Reserved" 108 "Reserved" 107 "Reserved" 106 "Reserved" 105 "Reserved" 104 "Reserved" 103 "Reserved" 102 "Reserved" 101 "Reserved" 42 "Water Pump Control" 41 "Lighting - Operator Controls" 40 "Seat Control" 39 "Ignition Control Module" 38 "Tire Pressure Control" 37 "Cab Controller" 36 "Pneumatic - System Controller" 35 "Suspension - System Controller" 34 "Hydraulic Pump Controller" 33 "System Monitor" 32 "Headway Controller" 31 "Propulsion Battery Charger" 30 "Management Computer" 29 "Virtual Terminal (In Cab)" 28 "Off Vehicle Gateway" 27 "Power TakeOff (Secondary or Front)" 26 "Body Controller" 25 "Network Interconnect ECU" 24 "Vehicle Security" 23 "Vehicle Navigation" 22 "Aerodynamic Control" 21 "Cab Climate Control" 20 "Trip Recorder" 19 "Instrument Cluster" 18 "Suspension - Drive Axle" 17 "Suspension - Steer Axle" 16 "Steeting Controller" 15 "Fuel System" 14 "Cruise Control" 13 "Retarder - Driveline" 12 "Retarder - Engine" 11 "Brakes - Drive Axle" 10 "Brakes - Steer Axle" 9 "Brakes - System Controller" 8 "Axle - Drive" 7 "Axle - Steering" 6 "Power TakeOff - (Main or Rear)" 5 "Shift Control/Console" 4 "Battery Pack Monitor" 3 "Transmission" 2 "Electric Propulsion Control" 1 "Auxiliary Power Unit (APU)" 0 "Engine" 100 "Reserved" 99 "Reserved" 98 "Reserved" 97 "Reserved" 96 "Reserved" 95 "Reserved" 94 "Reserved" 93 "Reserved" 92 "Reserved" 91 "Reserved" 90 "Reserved" 89 "Reserved" 88 "Reserved" 87 "Reserved" 86 "Reserved" 85 "Reserved" 84 "Reserved" 83 "Reserved" 82 "Reserved" 81 "Reserved" 80 "Reserved" 79 "Reserved" 78 "Reserved" 77 "Reserved" 76 "Reserved" 75 "Reserved" 74 "Reserved" 73 "Reserved" 72 "Coolant Valve Controller" 71 "Transfer Case Control" 70 "Auxiliary Regeneration Device" 69 "Engine Emission Aftertreatement System" 68 "Aftertreatment system gas measurement" 67 "Electrical System Controller" 66 "I/O Controller" 65 "Gas Flow Measurement" 64 "Endurance Braking" 63 "Engine Valve Controller" 62 "On-Board Diagnostic Unit" 61 "File Server/Printer" 60 "Cab Display" 59 "Starter" 58 "Fan Drive Control" 57 "Steering Column Unit" 56 "Communications Unit, Radio" 55 "Communications Unit, Satellite" 54 "Communications Unit, Cellular" 53 "Alternator/Charging System" 52 "Chassis Controller" 51 "Forward-Looking Collision Warning System" 50 "Auxiliary Heater" 49 "Clutch/Converter Control" 48 "Ramp Control" 47 "Information System Controller" 46 "Oil Sensor Unit" 45 "Vehicle Dynamic Stability Control" 44 "Exhaust Emission Control" 43 "Transmission Display" ;
VAL_ 2565799435 ManufacturerCode 1863 "Thomas G. Faria Co." 1862 "Sanshin" 1861 "Vector CANtech" 1860 "MMP" 1859 "Kvasar AB" 1858 "Litton" 1857 "Simrad" 1856 "Trimble" 1855 "Furuno USA" 1854 "Northstar Technologies" 1853 "Japan Radio Co." 1852 "Navionics" 1851 "Raymarine" 1850 "Teleflex" 222 "Generac Power Systems, Inc." 221 "SiE" 220 "Beede Electrical Instrument Company, Inc." 219 "Cat OEM Solutions" 218 "Gits Manufacturing Company" 217 "RM Michaelides Software & Elektronik GmbH" 216 "Paneltronics Inc." 215 "Aetna Engineering/Fireboy-Xintex" 214 "MC elettronica Srl" 213 "CNH Belgium N.V." 212 "Sure Power Industries, Inc." 211 "DNA Group" 210 "Iteris, Inc." 209 "Bell Equip. Co. SA (PTY) LTD" 208 "Drew Technologies, Inc." 207 "Otto Engineering" 206 "port GmbH" 205 "SmarTire Systems Inc" 204 "The Morey Corporation" 203 "MILtronik GmbH" 202 "Curtis Instruments, Inc." 201 "Disenos y Tecnologia S.A." 200 "MGM Brakes" 199 "Actia Corp." 198 "Mystic Valley Communications" 197 "Mechron Power Systems" 196 "LEMKEN GmbH & Co. KG" 195 "General Engine Products" 194 "TriMark Corporation" 193 "Jeppesen Marine" 192 "Floscan" 191 "XATA Corporation" 190 "Hella KGaA Hueck & Co." 189 "QUALCOMM" 188 "EMP Corp." 187 "Air-Weigh" 186 "Altronic, Inc." 185 "Beede Electrical Instrument Company" 184 "EIA Electronics" 183 "KDS Controls, Inc." 182 "Vehicle Systems Engineering B.V." 181 "Coretronics, Inc." 180 "Smart Power Systems" 179 "Midwest Technologies Illinois, LLC" 178 "Siemens VDO Automotive AG" 177 "Diagnostic System Associates" 176 "Moritz Aerospace" 175 "Veris Technologies, Inc." 174 "AB Volvo Penta" 173 "Ryeso, Inc." 172 "Yanmar Marine USA" 171 "Wachendorff Elektronik GmbH & Co. KG" 170 "Computronics Corporation Ltd." 169 "Marlin Technologies Inc." 168 "Xantrex" 167 "JLG Industries Inc." 166 "Phoenix International" 165 "CPAC Systems AB" 164 "DaimlerChrysler Off-Highway" 163 "BRP Inc." 162 "Axiomatic Technologies" 161 "Offshore Systems (UK) Limited" 160 "Nido" 159 "NTech Industries Inc." 158 "Firestone Industrial Products Company" 157 "ISSPRO Inc." 156 "ITT Industries - Cannon" 155 "Vetronix Corporation" 154 "Westerbeke Corporation" 153 "Woodward, Industrial Controls Division" 152 "Elobau Elektrobauelemente GmbH & Co. KG" 151 "Raven Industries Inc. - Flow Controls Division" 150 "Fleetguard" 149 "Holset" 148 "Blue Water Data, Inc." 147 "Nautibus Electronic GmbH" 146 "Maxima Technologies" 145 "MurCal Controls" 144 "Mercury Marine" 143 "W. Gmeiner GmbH & Co." 142 "TRW Automotive (Commercial Steering Systems)" 141 "Thales Navigation Ltd." 140 "Lowrance Electronics, Inc." 139 "Caterpillar Trimble Control Technologies (CTCT), LLC" 138 "Georg Fritzmeier GmbH & Co. KG" 137 "Maretron" 136 "Komatsu Ltd." 135 "Airmar Technology Corporation" 134 "Iris Technology Ltd." 133 "Bucher Schoerling GmbH" 132 "Mulag-Fahrzeugwerk" 131 "ITT Industries" 130 "Nido - Universal Machines B.V." 129 "OMNEX Control Systems, Inc." 128 "Gerhard Duecker GmbH & Co. KG" 127 "Holland USA" 126 "Driver Tech" 125 "Nevada Automotive Test Center" 124 "Hydac Electronic" 123 "Basler Electric" 122 "FG Wilson (Engineering) Limited" 121 "HED (Hydro Electronic Devices, Inc.)" 120 "RDS Technology Ltd." 119 "IntegriNautics" 118 "Intron GmbH" 117 "HUSCO International" 116 "BEELINE Technologies" 115 "NACCO Materials Handling Group, Inc." 114 "EControls, Inc." 113 "Stress-Tek, Inc." 112 "MECALAC" 111 "Maschinenfabrik Bernhard Krone GmbH" 110 "EPIQ Sensor-Nite" 109 "LH Technologies ApS" 108 "WTK-Elecktronik GmbH" 107 "Grimme Landmaschinen GmbH & Co. KG" 106 "BAE Systems Controls, Inc." 105 "Kiepe Elektrik GmbH & Co. KG" 104 "Claas Selbstfahrende Erntemaschinen GmbH" 103 "Agrocom GmbH & Co. Agrarsystem KG" 102 "AGCO GmbH & Co." 101 "Sensoria" 100 "VDO Technik AG" 99 "International Transmissions Ltd (ITL)" 98 "Mueller-Elektronik GmbH & Co." 97 "Ag Leader Technology, Inc." 96 "Mech@tronic IT GmbH" 95 "Pacific Insight Electronics Corp." 94 "CNH Global N.V." 93 "Perkins Engines Company Ltd." 92 "Ag-Chem Equipment Co., Inc." 91 "BSG Bodensee Steuergeraete GmbH" 90 "Knorr-Bremse SfN GmbH" 89 "Kverneland Group, Electronics Division" 88 "Satloc Precision GPS" 87 "J.C. Bamford Excavators Ltd (JCB)" 86 "C.E. Niehoff & Company" 85 "Kohler Co." 84 "New Holland UK Limited" 83 "Eaton VORAD Technologies" 82 "Bobcat/Ingersoll-Rand" 81 "Fire Research Corp" 80 "Twin Disc, Inc." 79 "Daimler Benz AG - Engine Division (PBM)" 78 "Frank W. Murphy Manufacturing, Inc." 77 "Deere Power Systems Group" 76 "unused" 75 "Deere & Co. Agricultural Division" 74 "Eaton Axle-Brake Division" 73 "LeTourneau, Inc." 72 "Sisu Corporation" 71 "Vansco Electronics Ltd." 70 "Flex-Coil Limited" 69 "Trimble Navigation" 68 "Scania" 67 "Funk Manufacturing Company" 66 "John Deere Construction Equipment Division" 65 "MAN Nutzfahrzeuge AG" 64 "unused" 63 "ZF Industries Inc." 62 "Wabco" 61 "Volvo Truck Corp." 60 "Volvo Trucks North America Inc." 59 "VES Inc." 58 "SPX Corporation, OTC Division" 57 "Sauer-Danfoss Co." 56 "SAIC" 55 "Ryder System Inc." 54 "Meritor Wabco" 53 "Rockwell Land Transportation" 52 "Meritor Automotive, Inc." 51 "Robert Bosch GmbH" 50 "Robert Bosch Corp" 49 "RE America Inc." 48 "Pollak Alphabet" 47 "Phillips Semiconductor" 46 "Parasoft Computing Solutions" 45 "PACCAR" 44 "Nippondenso Co. Ltd." 43 "International Truck and Engine Corp. Vehicle Electronics" 42 "International Truck and Engine Corp. Engine Electronics" 41 "Motorola Inc." 40 "Motorola AIEG Inc." 39 "Microfirm Inc." 38 "Micro Processor Systems Inc." 37 "Mack Trucks Inc." 36 "Lucas Ltd." 35 "Kenworth Truck Co." 34 "Kelsey Hayes Co." 33 "John Deere" 32 "Jacobs Vehicle Systems" 31 "J Pollak Corp." 30 "Isuzu Motors Ltd." 29 "Hino Motors Ltd." 28 "Grote Ind. Inc." 27 "GMC" 26 "General Motors Corp., Service Technology Group" 25 "Freightliner LLC" 24 "Ford Motor Co., Vehicle Controls" 23 "Ford Motor Co., Heavy Truck" 22 "Ford Motor Co., Electronic Concepts $ Systems" 21 "Echilin Inc., Midland Brake Inc." 20 "Eaton Ltd" 19 "Eaton Corp. Trucking Info Services" 18 "Eaton Corp, Transmission Division" 17 "Eaton Corp. Res & Dev" 16 "Eaton Corp." 15 "Dickey-John Corp." 14 "Detroit Diesel Corporation" 13 "Delco Electronics" 12 "Deere & Company, Precision Farming" 11 "Dearborn Group Inc." 10 "Cummins Engine Co." 9 "Chrysler Corp." 8 "Caterpillar Inc." 7 "Case Corp." 6 "Berifors Electronics AB" 5 "AMP Inc." 4 "Ametek-Dixson" 3 "Ametek, US Gauge Division" 2 "Allison Transmission, GMC" 1 "Allied Signal Inc." 0 "Reserved" ;
VAL_ 2565668363 PGNumber 255 "NotAvailable" ;
VAL_ 2565668363 ControlByte 24 "EAbort" 23 "EEoMACK" 22 "EDPO" 21 "ECTS" 20 "ERTS" 3 "CannotRespond" 2 "AccessDenied" 1 "NACK" 0 "ACK" 255 "Abort" 32 "BAM" 19 "EoMA" 17 "CTS" 16 "RTS" ;
VAL_ 2565406219 ControlByte 24 "EAbort" 23 "EEoMACK" 22 "EDPO" 21 "ECTS" 20 "ERTS" 3 "CannotRespond" 2 "AccessDenied" 1 "NACK" 0 "ACK" 255 "Abort" 32 "BAM" 19 "EoMA" 17 "CTS" 16 "RTS" ;
VAL_ 2562981630 FailureModeIdentifier1 31 "Not available" 19 "Received network data in error" 18 "Below normal (moderatels severe)" 17 "Below normal (least severe)" 16 "Above normal (moderately severe)" 15 "Above normal (least severe)" 14 "Special intstructions" 13 "Out of calibration" 12 "Bad intelligent device" 11 "Root cause not known" 10 "Abnormal rate of change" 9 "Abnormal update rate" 8 "Abnormal frequency" 7 "Mechanical system not responding" 6 "Current above normal" 5 "Current below normal" 4 "Voltage below normal" 3 "Voltage above normal" 2 "Data erratic" 1 "Below normal (most severe)" 0 "Above normal (most severe)" ;
VAL_ 2566836222 FlashRedStopLamp 3 "Unavailable / Do Not Flash" 2 "Reserved" 1 "Fast Flash" 0 "Slow Flash" ;
VAL_ 2566836222 FlashProtectLamp 3 "Unavailable / Do Not Flash" 2 "Reserved" 1 "Fast Flash" 0 "Slow Flash" ;
VAL_ 2566836222 FlashMalfuncIndicatorLamp 3 "Unavailable / Do Not Flash" 2 "Reserved" 1 "Fast Flash" 0 "Slow Flash" ;
VAL_ 2566836222 MalfunctionIndicatorLampStatus 3 "Not available" 2 "Reserved" 1 "Lamp on" 0 "Lamp off" ;
VAL_ 2566836222 RedStopLampState 3 "Not available" 2 "Reserved" 1 "Lamp on" 0 "Lamp off" ;
VAL_ 2566836222 AmberWarningLampStatus 3 "Not available" 2 "Reserved" 1 "Lamp on" 0 "Lamp off" ;
VAL_ 2566836222 ProtectLampStatus 3 "Not available" 2 "Reserved" 1 "Lamp on" 0 "Lamp off" ;
VAL_ 2566835966 MisfireMonitoringSupport 3 "Not available" 2 "Reserved" 1 "test supported" 0 "test not supported" ;
VAL_ 2566835966 OBDCompliance 5 "Not intended to meet OBD II requ" 4 "OBD I" 3 "OBD and OBD II" 2 "OBD (Federal, EPA)" 1 "OBD II (California, ARB)" 0 "Reserver for assignment by SAE" ;
VAL_ 2566835966 SecondAirSystemMonStatus 1 "TestNotComplete" 0 "TestComplete" ;
VAL_ 2566835966 EvaporativeSystemMonStatus 1 "TestNotComplete" 0 "TestComplete" ;
VAL_ 2566835966 ACSystemRefrigerantMonStatus 1 "TestNotComplete" 0 "TestComplete" ;
VAL_ 2566835966 OxygenSensorHeaterMonStatus 1 "TestNotComplete" 0 "TestComplete" ;
VAL_ 2566835966 OxygenSensorMonStatus 1 "test not complete" 0 "test complete" ;
VAL_ 2566835966 EGRSystemMonitoringStatus 1 "TestNotComplete" 0 "TestComplete" ;
VAL_ 2566835966 CatalystMonStatus 0 "TestComplete" 1 "TestNotComplete" ;
VAL_ 2566835966 ColdStartAidSystemMonStatus 1 "TestNotComplete" 0 "TestComplete" ;
VAL_ 2566835966 HeatedCatalystMonStatus 1 "TestNotComplete" 0 "TestComplete" ;
VAL_ 2566835966 CatalystMonSupp 1 "TestSupported" 0 "TestNotSupported" ;
VAL_ 2566835966 ColdStartAidSystemMonSupp 1 "TestSupported" 0 "TestNotSupported" ;
VAL_ 2566835966 HeatedCatalystMonSupp 1 "TestSupported" 0 "TestNotSupported" ;
VAL_ 2566835966 EvaporativeSystemMonSupp 1 "TestSupported" 0 "TestNotSupported" ;
VAL_ 2566835966 SecondAirSystemMonSupp 1 "TestSupported" 0 "TestNotSupported" ;
VAL_ 2566835966 ACSystemRefrigerantMonSupp 1 "TestSupported" 0 "TestNotSupported" ;
VAL_ 2566835966 OxygenSensorMonSupp 1 "TestSupported" 0 "TestNotSupported" ;
VAL_ 2566835966 OxygenSensorHeaterMonSupp 1 "TestSupported" 0 "TestNotSupported" ;
VAL_ 2566835966 EGRSystemMonitoringSupp 1 "TestSupported" 0 "TestNotSupported" ;
VAL_ 2566835966 MisfireMonitoringStatus 1 "test not complete" 0 "test complete" ;
VAL_ 2566835966 ComprehensiveCompMonStatus 1 "test not complete" 0 "test complete" ;
VAL_ 2566835966 FuelSystemMonitoringStatus 1 "test not complete" 0 "test complete" ;
VAL_ 2566835966 ComprehensiveComponentMonSupp 3 "Not available" 2 "Reserved" 1 "test supported" 0 "test not supported" ;
VAL_ 2566835966 FuelSystemMonitoringSupport 1 "test supported" 0 "test not supported" ;
VAL_ 2566835710 EngTorqueMode 15 "Not available" 11 "Remote accelerator" 10 "Braking system" 9 "High speed governor" 8 "Torque limiting" 7 "ABS control" 6 "Transmission control" 5 "ASR control" 4 "Road speed governor" 3 "PTO governor" 2 "Cruise control" 1 "Accelerator pedal/operator selec" 0 "Low idle governor/no request (de" ;
VAL_ 2566764286 SPNSupportTypeSTR3 1 "NotSupportedInScaledTestResults" 0 "SupportedInScaledTestResults" ;
VAL_ 2566764286 SPNSupportTypeSTR2 1 "NotSupportedInScaledTestResults" 0 "SupportedInScaledTestResults" ;
VAL_ 2566764286 SPNSupportTypeEFF3 1 "NotSupportedInExFreezeFrame" 0 "SupportedInExFreezeFrame" ;
VAL_ 2566764286 SPNSupportTypeEFF2 1 "NotSupportedInExFreezeFrame" 0 "SupportedInExFreezeFrame" ;
VAL_ 2566764286 SPNSupportTypeDS3 1 "NotSupportedInDataStream" 0 "SupportedInDataStream" ;
VAL_ 2566764286 SPNSupportTypeDS2 1 "NotSupportedInDataStream" 0 "SupportedInDataStream" ;
VAL_ 2566764286 SPNSupportTypeSTR1 1 "NotSupportedInScaledTestResults" 0 "SupportedInScaledTestResults" ;
VAL_ 2566764286 SPNSupportTypeDS1 1 "NotSupportedInDataStream" 0 "SupportedInDataStream" ;
VAL_ 2566764286 SPNSupportTypeEFF1 1 "NotSupportedInExFreezeFrame" 0 "SupportedInExFreezeFrame" ;
VAL_ 2566835198 MalfunctionIndicatorLampStatus 3 "Not available" 2 "Reserved" 1 "Lamp on" 0 "Lamp off" ;
VAL_ 2566835198 RedStopLampState 3 "Not available" 2 "Reserved" 1 "Lamp on" 0 "Lamp off" ;
VAL_ 2566835198 AmberWarningLampStatus 3 "Not available" 2 "Reserved" 1 "Lamp on" 0 "Lamp off" ;
VAL_ 2566835198 ProtectLampStatus 3 "Not available" 2 "Reserved" 1 "Lamp on" 0 "Lamp off" ;
VAL_ 2566835198 FlashRedStopLamp 3 "Unavailable / Do Not Flash" 2 "Reserved" 1 "Fast Flash" 0 "Slow Flash" ;
VAL_ 2566835198 FlashProtectLamp 3 "Unavailable / Do Not Flash" 2 "Reserved" 1 "Fast Flash" 0 "Slow Flash" ;
VAL_ 2566835198 FlashMalfuncIndicatorLamp 3 "Unavailable / Do Not Flash" 2 "Reserved" 1 "Fast Flash" 0 "Slow Flash" ;
VAL_ 2566835198 FlashAmberWarningLamp 3 "Unavailable / Do Not Flash" 2 "Reserved" 1 "Fast Flash" 0 "Slow Flash" ;
VAL_ 2566837502 FlashRedStopLamp 3 "Unavailable / Do Not Flash" 2 "Reserved" 1 "Fast Flash" 0 "Slow Flash" ;
VAL_ 2566837502 FlashProtectLamp 3 "Unavailable / Do Not Flash" 2 "Reserved" 1 "Fast Flash" 0 "Slow Flash" ;
VAL_ 2566837502 MalfunctionIndicatorLampStatus 3 "Not available" 2 "Reserved" 1 "Lamp on" 0 "Lamp off" ;
VAL_ 2566837502 RedStopLampState 3 "Not available" 2 "Reserved" 1 "Lamp on" 0 "Lamp off" ;
VAL_ 2566837502 AmberWarningLampStatus 3 "Not available" 2 "Reserved" 1 "Lamp on" 0 "Lamp off" ;
VAL_ 2566837502 ProtectLampStatus 3 "Not available" 2 "Reserved" 1 "Lamp on" 0 "Lamp off" ;
VAL_ 2566837502 FlashMalfuncIndicatorLamp 3 "Unavailable / Do Not Flash" 2 "Reserved" 1 "Fast Flash" 0 "Slow Flash" ;
VAL_ 2566837502 FlashAmberWarningLamp 3 "Unavailable / Do Not Flash" 2 "Reserved" 1 "Fast Flash" 0 "Slow Flash" ;
VAL_ 2566834942 FlashRedStopLamp 3 "Unavailable / Do Not Flash" 2 "Reserved" 1 "Fast Flash" 0 "Slow Flash" ;
VAL_ 2566834942 FlashProtectLamp 3 "Unavailable / Do Not Flash" 2 "Reserved" 1 "Fast Flash" 0 "Slow Flash" ;
VAL_ 2566834942 FlashMalfuncIndicatorLamp 3 "Unavailable / Do Not Flash" 2 "Reserved" 1 "Fast Flash" 0 "Slow Flash" ;
VAL_ 2566834942 FlashAmberWarningLamp 3 "Unavailable / Do Not Flash" 2 "Reserved" 1 "Fast Flash" 0 "Slow Flash" ;
VAL_ 2566834942 MalfunctionIndicatorLampStatus 3 "Not available" 2 "Reserved" 1 "Lamp on" 0 "Lamp off" ;
VAL_ 2566834942 AmberWarningLampStatus 3 "Not available" 2 "Reserved" 1 "Lamp on" 0 "Lamp off" ;
VAL_ 2566834942 RedStopLampState 3 "Not available" 2 "Reserved" 1 "Lamp on" 0 "Lamp off" ;
VAL_ 2566834942 ProtectLampStatus 3 "Not available" 2 "Reserved" 1 "Lamp on" 0 "Lamp off" ;
VAL_ 2565799678 VehicleSystem5 127 "Not Available" 0 "Ind. Process Control Stationary" ;
VAL_ 2565799678 VehicleSystem4 100 "Deck/Cargo/Fishing equip. sys" 90 "Environmental (HVAC) Systems" 80 "Instrumentation/General Systems" 70 "Communications Systems" 60 "Navigation Systems" 50 "Propulsion Systems" 40 "Steering Systems" 30 "Power Mgmt and lighting systems" 25 "Gateway" 20 "Safety Systems" 10 "System Tools" 127 "Not Available" 0 "Non-specific System" ;
VAL_ 2565799678 VehicleSystem3 8 "Grader" 7 "Four Wheel Drive Loader" 6 "Forklift" 5 "Excavator" 4 "Crawler" 3 "Backhoe" 2 "Articulated Dump Truck" 1 "Skid Steer Loader" 127 "Not Available" 0 "Non-specific System" ;
VAL_ 2565799678 VehicleSystem2 16 "Skidder" 15 "Earth Work" 14 "Special Crops" 13 "Powered Auxiliary Device" 12 "Farm Yard Operations" 11 "Transport/Trailer" 10 "Irrigation" 9 "Forage" 8 "Root Harvesters" 7 "Harvesters" 6 "Sprayers" 5 "Fertilizers" 4 "Planters/Seeders" 3 "Secondary Tillage" 2 "Tillage" 1 "Tractor" 127 "Not Available" 0 "Non-specific System" ;
VAL_ 2565799678 VehicleSystem1 2 "Trailer" 1 "Tractor" 127 "Not Available" 0 "Non-specific System" ;
VAL_ 2565799678 IndustryGroup 6 "Reserved for SAE" 7 "Reserved for SAE" 5 "IndustrialProcessCtrlStationary" 4 "Marine" 3 "Construction" 2 "Agricultural and Forestry" 1 "On-Highway" 0 "Global" ;
VAL_ 2565799678 VehicleSystem 0 "Non-specific System" 127 "Not Available" ;
VAL_ 2565799678 Function 127 "Reserved" 126 "Reserved" 125 "Reserved" 124 "Reserved" 123 "Reserved" 122 "Reserved" 121 "Reserved" 120 "Reserved" 119 "Reserved" 118 "Reserved" 117 "Reserved" 116 "Reserved" 115 "Reserved" 114 "Reserved" 113 "Reserved" 112 "Reserved" 111 "Reserved" 110 "Reserved" 109 "Reserved" 108 "Reserved" 107 "Reserved" 106 "Reserved" 105 "Reserved" 104 "Reserved" 103 "Reserved" 102 "Reserved" 101 "Reserved" 42 "Water Pump Control" 41 "Lighting - Operator Controls" 40 "Seat Control" 39 "Ignition Control Module" 38 "Tire Pressure Control" 37 "Cab Controller" 36 "Pneumatic - System Controller" 35 "Suspension - System Controller" 34 "Hydraulic Pump Controller" 33 "System Monitor" 32 "Headway Controller" 31 "Propulsion Battery Charger" 30 "Management Computer" 29 "Virtual Terminal (in cab)" 28 "Off Vehicle Gateway" 27 "Power TakeOff (Secondary or Front)" 26 "Body Controller" 25 "Network Interconnect ECU" 24 "Vehicle Security" 23 "Vehicle Navigation" 22 "Aerodynamic Control" 21 "Cab Climate Control" 20 "Trip Recorder" 19 "Instrument Cluster" 18 "Suspension - Drive Axle" 17 "Suspension - Steer Axle" 16 "Steering Controller" 15 "Fuel System" 14 "Cruise Control" 13 "Retarder - Driveline" 12 "Retarder - Engine" 11 "Brakes - Drive Axle" 10 "Brakes - Steer Axle" 9 "Brakes - System Controller" 8 "Axle - Drive" 7 "Axle - Steering" 6 "Power TakeOff - (Main or Rear)" 5 "Shift Control/Console" 4 "Battery Pack Monitor" 3 "Transmission" 2 "Electric Propulsion Control" 1 "Auxiliary Power Unit (APU)" 0 "Engine" 100 "Reserved" 99 "Reserved" 98 "Reserved" 97 "Reserved" 96 "Reserved" 95 "Reserved" 94 "Reserved" 93 "Reserved" 92 "Reserved" 91 "Reserved" 90 "Reserved" 89 "Reserved" 88 "Reserved" 87 "Reserved" 86 "Reserved" 85 "Reserved" 84 "Reserved" 83 "Reserved" 82 "Reserved" 81 "Reserved" 80 "Reserved" 79 "Reserved" 78 "Reserved" 77 "Reserved" 76 "Reserved" 75 "Supplemental Fan" 74 "Lubrication System" 73 "Rollover Detection Control" 72 "Coolant Valve Controller" 71 "Transfer Case Control" 70 "Auxiliary Regeneration Device" 69 "Engine Emission Aftertreatement System" 68 "Aftertreatment system gas measurement" 67 "Electrical System Controller" 66 "I/O Controller" 65 "Gas Flow Measurement" 64 "Endurance Braking" 63 "Engine Valve Controller" 62 "On-Board Diagnostic Unit" 61 "File Server/Printer" 60 "Cab Display" 59 "Starter" 58 "Fan Drive Control" 57 "Steering Column Unit" 56 "Communications Unit, Radio" 55 "Communications Unit, Satellite" 54 "Communications Unit, Cellular" 53 "Alternator/Charging System" 52 "Chassis Controller" 51 "Forward-Looking Collision Warning System" 50 "Auxiliary Heater" 49 "Clutch/Converter Control" 48 "Ramp Control" 47 "Information System Controller" 46 "Oil Sensor Unit" 45 "Vehicle Dynamic Stability Control" 44 "Exhaust Emission Control" 43 "Transmission Display" ;
VAL_ 2565799678 ManufacturerCode 381 "B&G" 374 "Northern Lights" 373 "Electronic Design" 371 "Delphi" 370 "Heinzmann GmbH & Co. KG" 369 "Power Torque Engineering Ltd" 368 "HANSENHOF_electronic" 367 "Fliegl Agrartechnik" 366 "Viewnyx Corp." 365 "Digi-Star, LLC" 364 "OEM Controls Inc." 363 "BEI Duncan" 362 "Alois Poettinger Maschinenfabrik GmbH" 361 "InMach" 360 "HJS Fahrzeugtechnik GmbH & Co KG" 359 "Ludwig Bergmann GmbH" 358 "Victron Energy BV" 357 "Hardi International A/S" 356 "Fischer Panda Generators, Inc" 355 "Mastervolt International B.V." 354 "Junkkari OY" 353 "Hegemon Electronics, Inc." 352 "SAME DEUTZ-FAHR" 351 "Thrane & Thrane" 350 "Noris Marine Systems GmbH & Co KG" 349 "Suonentiet" 348 "Amazonen Werke H. Dreyer" 347 "Honeywell" 346 "Control Solutions" 345 "Korean Maritime University" 344 "Parvus Corporation" 343 "Baumer Group" 342 "THOMAS MAGNETE GmbH" 341 "Boning GmbH & Co" 340 "Continental AG" 339 "Competence Center ISOBUS e.V." 338 "GRAF-SYTECO" 337 "Carraro S.p.A." 336 "APE s.r.o." 335 "Evo Electric Ltd" 334 "Takata-Petri AG" 333 "Hadley Products Corporation" 332 "HWH Corporation" 331 "Horton, Inc." 330 "Kidde Aerospace and Defense" 329 "Deif A/S" 328 "Qwerty Electronik AB" 252 "Sensor-Technik Wiedemann GmbH" 251 "German Agricultural Society" 250 "Kuhn Group" 249 "Schaltbau GmbH" 233 "Yacht Monitoring Solutions Inc." 232 "TSD Integrated Controls" 1863 "Thomas G. Faria Co." 1862 "Sanshin" 1861 "Vector CANtech" 1860 "MMP" 1859 "Kvasar AB" 1858 "Litton" 1857 "Simrad" 1856 "Trimble" 1855 "Furuno USA" 1854 "Northstar Technologies" 1853 "Japan Radio Co." 1852 "Navionics" 1851 "Raymarine" 1850 "Teleflex" 222 "Generac Power Systems, Inc." 221 "SiE" 220 "Beede Electrical Instrument Company, Inc." 219 "Cat OEM Solutions" 218 "Gits Manufacturing Company" 217 "RM Michaelides Software & Elektronik GmbH" 216 "Paneltronics Inc." 215 "Aetna Engineering/Fireboy-Xintex" 214 "MC elettronica Srl" 213 "CNH Belgium N.V." 212 "Sure Power Industries, Inc." 211 "DNA Group" 210 "Iteris, Inc." 209 "Bell Equip. Co. SA (PTY) LTD" 208 "Drew Technologies, Inc." 207 "Otto Engineering" 206 "port GmbH" 205 "SmarTire Systems Inc" 204 "The Morey Corporation" 203 "MILtronik GmbH" 202 "Curtis Instruments, Inc." 201 "Disenos y Tecnologia S.A." 200 "MGM Brakes" 199 "Actia Corp." 198 "Mystic Valley Communications" 197 "Mechron Power Systems" 196 "LEMKEN GmbH & Co. KG" 195 "General Engine Products" 194 "TriMark Corporation" 193 "Nobletec" 192 "Floscan" 191 "XATA Corporation" 190 "Hella KGaA Hueck & Co." 189 "QUALCOMM" 188 "EMP Corp." 187 "Air-Weigh" 186 "Altronic, Inc." 185 "Beede Electrical Instrument Company" 184 "EIA Electronics" 183 "KDS Controls, Inc." 182 "Vehicle Systems Engineering B.V." 181 "Coretronics, Inc." 180 "Smart Power Systems" 179 "TeeJet Technologies Denmark" 178 "Siemens VDO Automotive AG" 177 "Diagnostic System Associates" 176 "Moritz Aerospace" 175 "Veris Technologies, Inc." 174 "AB Volvo Penta" 173 "Ryeso, Inc." 172 "Yanmar Marine USA" 171 "Wachendorff Elektronik GmbH & Co. KG" 170 "Computronics Corporation Ltd." 169 "Marlin Technologies Inc." 168 "Xantrex" 167 "JLG Industries Inc." 166 "Phoenix International" 165 "CPAC Systems AB" 164 "DaimlerChrysler Off-Highway" 163 "BRP Inc." 162 "Axiomatic Technologies" 161 "Offshore Systems (UK) Limited" 160 "Nido" 159 "NTech Industries Inc." 158 "Firestone Industrial Products Company" 157 "ISSPRO Inc." 156 "ITT Industries - Cannon" 155 "Vetronix Corporation" 154 "Westerbeke Corporation" 153 "Woodward, Industrial Controls Division" 152 "elobau GmbH & Co. KG" 151 "Raven Industries Inc. - Flow Controls Division" 150 "Fleetguard" 149 "Holset" 148 "Blue Water Data, Inc." 147 "Nautibus Electronic GmbH" 146 "Maxima Technologies" 145 "MurCal Controls" 144 "Mercury Marine" 143 "W. Gmeiner GmbH & Co." 142 "TRW Automotive (Commercial Steering Systems)" 141 "Thales Navigation Ltd." 140 "Lowrance Electronics, Inc." 139 "Caterpillar Trimble Control Technologies (CTCT), LLC" 138 "Georg Fritzmeier GmbH & Co. KG" 137 "Maretron" 136 "Komatsu Ltd." 135 "Airmar Technology Corporation" 134 "Iris Technology Ltd." 133 "Bucher Schoerling GmbH" 132 "Mulag-Fahrzeugwerk" 131 "ITT Industries" 130 "Nido - Universal Machines B.V." 129 "OMNEX Control Systems, Inc." 128 "Gerhard Duecker GmbH & Co. KG" 127 "Holland USA" 126 "Driver Tech" 125 "Nevada Automotive Test Center" 124 "Hydac Electronic" 123 "Basler Electric" 122 "FG Wilson (Engineering) Limited" 121 "HED (Hydro Electronic Devices, Inc.)" 120 "RDS Technology Ltd." 119 "IntegriNautics" 118 "Intron GmbH" 117 "HUSCO International" 116 "BEELINE Technologies" 115 "NACCO Materials Handling Group, Inc." 114 "EControls, Inc." 113 "Stress-Tek, Inc." 112 "MECALAC" 111 "Maschinenfabrik Bernhard Krone GmbH" 110 "EPIQ Sensor-Nite" 109 "TeeJet Technologies Denmark" 108 "WTK-Elecktronik GmbH" 107 "Grimme Landmaschinen GmbH & Co. KG" 106 "BAE Systems Controls, Inc." 105 "Kiepe Elektrik GmbH & Co. KG" 104 "Claas Selbstfahrende Erntemaschinen GmbH" 103 "Agrocom GmbH & Co. Agrarsystem KG" 102 "AGCO GmbH & Co." 101 "Sensoria" 100 "VDO Technik AG" 99 "International Transmissions Ltd (ITL)" 98 "Mueller-Elektronik GmbH & Co." 97 "Ag Leader Technology, Inc." 96 "Mech@tronic IT GmbH" 95 "Pacific Insight Electronics Corp." 94 "CNH Global N.V." 93 "Perkins Engines Company Ltd." 92 "Ag-Chem Equipment Co., Inc." 91 "BSG Bodensee Steuergeraete GmbH" 90 "Knorr-Bremse SfN GmbH" 89 "Kverneland Group, Electronics Division" 88 "Satloc Precision GPS" 87 "J.C. Bamford Excavators Ltd (JCB)" 86 "C.E. Niehoff & Company" 85 "Kohler Co." 84 "New Holland UK Limited" 83 "Eaton VORAD Technologies" 82 "Bobcat/Ingersoll-Rand" 81 "Fire Research Corp" 80 "Twin Disc, Inc." 79 "Daimler Benz AG - Engine Division (PBM)" 78 "Frank W. Murphy Manufacturing, Inc." 77 "Deere Power Systems Group" 76 "unused" 75 "Deere & Co. Agricultural Division" 74 "Eaton Axle-Brake Division" 73 "LeTourneau, Inc." 72 "Sisu Corporation" 71 "Vansco Electronics Ltd." 70 "Flex-Coil Limited" 69 "Trimble Navigation" 68 "Scania" 67 "Funk Manufacturing Company" 66 "John Deere Construction Equipment Division" 65 "MAN Nutzfahrzeuge AG" 64 "unused" 63 "ZF Industries Inc." 62 "Wabco" 61 "Volvo Truck Corp." 60 "Volvo Trucks North America Inc." 59 "VES Inc." 58 "SPX Corporation, OTC Division" 57 "Sauer-Danfoss Co." 56 "SAIC" 55 "Ryder System Inc." 54 "Meritor Wabco" 53 "Continental Automotive Systems US, Inc." 52 "Meritor Automotive, Inc." 51 "Robert Bosch GmbH" 50 "Robert Bosch Corp" 49 "RE America Inc." 48 "Pollak Alphabet" 47 "Phillips Semiconductor" 46 "Parasoft Computing Solutions" 45 "PACCAR" 44 "Nippondenso Co. Ltd." 43 "International Truck and Engine Corp. Vehicle Electronics" 42 "International Truck and Engine Corp. Engine Electronics" 41 "Motorola Inc." 40 "Motorola AIEG Inc." 39 "Microfirm Inc." 38 "Micro Processor Systems Inc." 37 "Mack Trucks Inc." 36 "Lucas Ltd." 35 "Kenworth Truck Co." 34 "Kelsey Hayes Co." 33 "John Deere" 32 "Jacobs Vehicle Systems" 31 "J Pollak Corp." 30 "Isuzu Motors Ltd." 29 "Hino Motors Ltd." 28 "Grote Ind. Inc." 27 "GMC" 26 "General Motors Corp., Service Technology Group" 25 "Daimler Trucks North America LLC" 24 "Ford Motor Co., Vehicle Controls" 23 "Ford Motor Co., Heavy Truck" 22 "Ford Motor Co., Electronic Concepts $ Systems" 21 "Echilin Inc., Midland Brake Inc." 20 "Eaton Ltd" 19 "Eaton Corp. Trucking Info Services" 18 "Eaton Corp, Transmission Division" 17 "Eaton Corp. Res & Dev" 16 "Eaton Corp." 15 "Dickey-John Corp." 14 "Detroit Diesel Corporation" 13 "Delco Electronics" 12 "Deere & Company, Precision Farming" 11 "Dearborn Group Inc." 10 "Cummins Engine Co." 9 "Chrysler Corp." 8 "Caterpillar Inc." 7 "Case Corp." 6 "Berifors Electronics AB" 5 "AMP Inc." 4 "Ametek-Dixson" 3 "Ametek, US Gauge Division" 2 "Allison Transmission, GMC" 1 "Allied Signal Inc." 0 "Reserved" 231 "Topcon Positioning Systems, Inc." 230 "Saucon Technologies" 229 "Garmin International Inc." 228 "ZF Marine Electronics" 227 "Lykketronic A/S" 226 "Monaco Coach Corporation" 225 "SKF" 224 "EMMI Network, S.L." 223 "Vaueo Retarder Co., Ltd." 263 "IMMI" 262 "HydraForce, Inc" 261 "Red Dot Corporation" 260 "Reichhardt GmbH" 259 "Jetter AG" 258 "ARAG" 257 "Honda Motor Co., Ltd" 256 "Tyco Electronics AMP" 255 "MEAS France" 254 "GE Sensing" 253 "Mobile Control Systems" 298 "Holley Performance" 297 "Zonar Systems Inc" 296 "micro dynamics GmbH" 295 "BEP Marine" 294 "Grayhill Inc." 293 "Spyder Controls Corp." 292 "IKUSI - Angel Iglesias S.A." 291 "Groeneveld Transport Efficiency BV" 290 "Kuebler GmbH" 289 "Watlow" 288 "Mitsubishi FUSO Truck & Bus Corp." 287 "NTech Industries, Inc" 286 "Coelmo srl" 285 "Sea Recovery Corp" 284 "Mobile Tech Chile" 283 "CWF Hamilton & Co Ltd" 282 "Medallion Instrumentation Systems" 281 "Precision Governors LLC" 311 "Patrick Power Products" 310 "TECNORD srl" 309 "Krauss-Maffei Wegmann GmbH & Co. KG" 308 "Cyntrx" 307 "MAS Technologies" 306 "Sleipner Motor AB" 305 "NovAtel Inc" 304 "EmpirBus AB" 303 "CTS Corporation" 302 "Nissin Kogyo Co., LTD" 301 "Parker Hannifin (UK) Ltd FDE group" 300 "Systron Donner Automotive" 299 "Rauch Landmaschinen GmbH" 280 "Leica Geosystems Pty Ltd" 279 "Geometris LP" 278 "Takata Electronics" 277 "LHP Telematics" 276 "Aqua-Hot Heating Systems" 275 "Navico Egersund AS" 274 "LTW Technology Co., LTD" 273 "Active Research Limited" 272 "Gross Mechanical Laboratories, Inc" 327 "Sonceboz SA" 326 "Akron Brass Company" 325 "ASM Automation Sensorik Messtechnik GmbH" 324 "Snap-on Diagnostics" 323 "Mobileye Vision Technologies Ltd." 322 "MICHENKA s.r.o." 321 "Ultra Electronics, Electrics" 320 "Miedema Landbouwwerktuigenfabriek B.V." 319 "Cadec Global" 318 "SAT Plan" 317 "Navtronics Bvba" 316 "ITT Flow Control" 315 "Icom Incorporated" 314 "CSM GmbH" 313 "Ilmor Engineering, Inc" 312 "Lectronix, Inc." 271 "Cole Hersee" 270 "Tennant" 269 "Saft America Inc.,  Space & Defense Division" 268 "Accurate Technologies" 267 "Red Lion Controls, Inc" 266 "International Thermal Research Ltd" 265 "MTS Sensor Technologie GmbH" 264 "Autolync" 248 "Cooper Standard Automotive Active Systems Group" 247 "ePULSE" 246 "Class 1, Inc" 245 "Capstan Ag Systems, Inc." 244 "Techno-Matic" 243 "eRide, Inc." 242 "Kokusandenki Co. Ltd" 241 "Schneider Automation SAS " 240 "Vanair Mfg" 239 "May & Scofield Ltd" 238 "ZF Friedrichshafen AG" 237 "Agtron Enterprises Inc" 236 "Norac Systems International Inc" 235 "SailorMade Marine Telemetry - Tetra Technology Ltd." 234 "Mondial electronic GmbH" ;
VAL_ 2565668606 PGNumber 255 "NotAvailable" ;
VAL_ 2565668606 ControlByte 24 "EAbort" 23 "EEoMACK" 22 "EDPO" 21 "ECTS" 20 "ERTS" 3 "CannotRespond" 2 "AccessDenied" 1 "NACK" 0 "ACK" 255 "Abort" 32 "BAM" 19 "EoMA" 17 "CTS" 16 "RTS" ;
VAL_ 2565406462 ControlByte 24 "EAbort" 23 "EEoMACK" 22 "EDPO" 21 "ECTS" 20 "ERTS" 3 "CannotRespond" 2 "AccessDenied" 1 "NACK" 0 "ACK" 255 "Abort" 32 "BAM" 19 "EoMA" 17 "CTS" 16 "RTS" ;
VAL_ EnvEBS_SimulationMode 1 "SimulateValues" 0 "ManualValueAdjustment" ;
